VERSION ""

NS_ :

BS_:

BU_: SGW PBWM IDCM EVCU2 ECM DMPI BPCM AGSM

BO_ 2654408730 PLUG_AND_CHARGE_CONTRACT: 64 SGW
 SG_ PLUG_AND_CHARGE_CONTRACT_Sig8 : 455|64@0+ (0,0) [0|0] "" IDCM
 SG_ PLUG_AND_CHARGE_CONTRACT_Sig7 : 391|64@0+ (0,0) [0|0] "" IDCM
 SG_ PLUG_AND_CHARGE_CONTRACT_Sig6 : 327|64@0+ (0,0) [0|0] "" IDCM
 SG_ PLUG_AND_CHARGE_CONTRACT_Sig5 : 263|64@0+ (0,0) [0|0] "" IDCM
 SG_ PLUG_AND_CHARGE_CONTRACT_Sig4 : 199|64@0+ (0,0) [0|0] "" IDCM
 SG_ PLUG_AND_CHARGE_CONTRACT_Sig3 : 135|64@0+ (0,0) [0|0] "" IDCM
 SG_ PLUG_AND_CHARGE_CONTRACT_Sig2 : 71|64@0+ (0,0) [0|0] "" IDCM
 SG_ PLUG_AND_CHARGE_CONTRACT_Sig1 : 7|64@0+ (0,0) [0|0] "" IDCM

BO_ 212 PIM_B: 64 DMPI
 SG_ PIM_B_Torque_Achieved : 44|13@0+ (0.125,-512) [-512|511.875] "Nm"  EVCU2
 SG_ PIM_B_Torque_Achieved_V : 129|1@0+ (1,0) [0|1] "" EVCU2
 SG_ PIM_B_TorqAchieved_AEMD_V : 196|1@0+ (1,0) [0|1] "" EVCU2
 SG_ PIM_B_TorqAchieved_AEMD : 299|13@0+ (0.125,-512) [-512|511.875] "Nm"  EVCU2
 SG_ PIM_B_SPT_Stat : 78|2@0+ (1,0) [0|3] "" EVCU2
 SG_ PIM_B_Spd_Lim : 356|16@0+ (1,-32767) [-32767|32678] "rpm"  EVCU2
 SG_ PIM_B_RPM_V : 234|1@0+ (1,0) [0|1] "" PBWM,EVCU2
 SG_ PIM_B_RPM : 28|16@0+ (1,-32768) [-32768|32767] "rpm"  PBWM,EVCU2
 SG_ PIM_B_MtrMinCpbltyTrq : 321|13@0+ (0.125,-512) [-512|511.875] "Nm"  EVCU2
 SG_ PIM_B_MtrMaxCpbltyTrq : 318|13@0+ (0.125,-512) [-512|511.875] "Nm"  EVCU2
 SG_ PIM_B_MtrIndex : 398|5@0+ (1,0) [0|31] "" EVCU2
 SG_ PIM_B_MinTorq : 280|13@0+ (0.125,-512) [-512|511.875] "Nm"  EVCU2
 SG_ PIM_B_MaxTorq : 277|13@0+ (0.125,-512) [-512|511.875] "Nm"  EVCU2
 SG_ PIM_B_Invrtr_State : 186|4@0+ (1,0) [0|15] "" EVCU2
 SG_ PIM_B_InterlockSts : 229|2@0+ (1,0) [0|3] "-"  EVCU2
 SG_ PIM_B_HV_CnctrOpn_Req : 195|1@0+ (1,0) [0|1] "" EVCU2
 SG_ PIM_B_Dschrge_Status : 393|2@0+ (1,0) [0|3] "" EVCU2
 SG_ PIM_B_DeratingFactor : 388|6@0+ (0.02,0) [0|1.26] "" EVCU2
 SG_ PIM_B_DerateReason : 170|4@0+ (1,0) [0|15] "-"  EVCU2
 SG_ PIM_B_DC_Voltage : 271|10@0+ (1,0) [0|1022] "V"  EVCU2
 SG_ PIM_B_DC_Volt_V : 197|1@0+ (1,0) [0|1] "" EVCU2
 SG_ PIM_B_DC_Current_V : 198|1@0+ (1,0) [0|1] "" EVCU2
 SG_ PIM_B_DC_Current : 63|15@0+ (0.1,-1638.4) [-1638.4|1638.3] "A"  EVCU2,BPCM
 SG_ PIM_B_CpbltySpdDivVolt : 340|16@0+ (1,0) [0|65535] "rpm"  EVCU2
 SG_ PIM_B_CoolantTemp : 407|11@0+ (0.1,-40) [-40|164.7] "°C"  EVCU2
 SG_ PIM_B_AccelRawV : 193|1@0+ (1,0) [0|1] "" EVCU2
 SG_ PIM_B_6SO_Status : 64|2@0+ (1,0) [0|3] "" EVCU2
 SG_ PIM_B_3PS_Pos : 194|1@0+ (1,0) [0|1] "" EVCU2
 SG_ MC_PIM_B : 435|4@0+ (1,0) [0|15] "-"  EVCU2
 SG_ MAC_PIM_B : 471|48@0+ (1,0) [0|0] "" EVCU2
 SG_ CRC_PIM_B : 447|8@0+ (1,0) [0|255] "-"  EVCU2
 SG_ Cntr_PIM_B : 455|16@0+ (1,0) [0|65535] "" EVCU2
 SG_ PIM_B_AccelRaw : 372|16@0+ (1,-32768) [-32768|32767] "rpm/sec"  EVCU2

BO_ 211 PIM_A: 64 DMPI
 SG_ PIM_A_Torque_Achieved : 44|13@0+ (0.125,-512) [-512|511.875] "Nm"  EVCU2,ECM
 SG_ PIM_A_Torque_Achieved_V : 129|1@0+ (1,0) [0|1] "" EVCU2,ECM
 SG_ PIM_A_TorqAchieved_AEMD_V : 196|1@0+ (1,0) [0|1] "" EVCU2
 SG_ PIM_A_TorqAchieved_AEMD : 299|13@0+ (0.125,-512) [-512|511.875] "Nm"  EVCU2
 SG_ PIM_A_SPT_Stat : 78|2@0+ (1,0) [0|3] "" EVCU2
 SG_ PIM_A_Spd_Lim : 356|16@0+ (1,-32767) [-32767|32678] "rpm"  EVCU2
 SG_ PIM_A_RPM_V : 234|1@0+ (1,0) [0|1] "" EVCU2
 SG_ PIM_A_RPM : 28|16@0+ (1,-32768) [-32768|32767] "rpm"  EVCU2
 SG_ PIM_A_MtrMinCpbltyTrq : 321|13@0+ (0.125,-512) [-512|511.875] "Nm"  EVCU2
 SG_ PIM_A_MtrMaxCpbltyTrq : 318|13@0+ (0.125,-512) [-512|511.875] "Nm"  EVCU2
 SG_ PIM_A_MtrIndex : 398|5@0+ (1,0) [0|31] "" EVCU2
 SG_ PIM_A_MinTorq : 280|13@0+ (0.125,-512) [-512|511.875] "Nm"  EVCU2
 SG_ PIM_A_MaxTorq : 277|13@0+ (0.125,-512) [-512|511.875] "Nm"  EVCU2
 SG_ PIM_A_Invrtr_State : 186|4@0+ (1,0) [0|15] "" EVCU2
 SG_ PIM_A_InterlockSts : 229|2@0+ (1,0) [0|3] "-"  EVCU2
 SG_ PIM_A_HV_CnctrOpn_Req : 195|1@0+ (1,0) [0|1] "" EVCU2
 SG_ PIM_A_Dschrge_Status : 393|2@0+ (1,0) [0|3] "" EVCU2
 SG_ PIM_A_DeratingFactor : 388|6@0+ (0.02,0) [0|1.26] "" EVCU2
 SG_ PIM_A_DerateReason : 170|4@0+ (1,0) [0|15] "-"  EVCU2
 SG_ PIM_A_DC_Voltage : 271|10@0+ (1,0) [0|1022] "V"  EVCU2
 SG_ PIM_A_DC_Volt_V : 197|1@0+ (1,0) [0|1] "" EVCU2
 SG_ PIM_A_DC_Current_V : 198|1@0+ (1,0) [0|1] "" EVCU2
 SG_ PIM_A_DC_Current : 63|15@0+ (0.1,-1638.4) [-1638.4|1638.3] "A"  EVCU2,BPCM
 SG_ PIM_A_CpbltySpdDivVolt : 340|16@0+ (1,0) [0|65535] "rpm"  EVCU2
 SG_ PIM_A_CoolantTemp : 407|11@0+ (0.1,-40) [-40|164.7] "°C"  EVCU2
 SG_ PIM_A_AccelRawV : 193|1@0+ (1,0) [0|1] "" EVCU2
 SG_ PIM_A_6SO_Status : 64|2@0+ (1,0) [0|3] "" EVCU2
 SG_ PIM_A_3PS_Pos : 194|1@0+ (1,0) [0|1] "" EVCU2
 SG_ MC_PIM_A : 435|4@0+ (1,0) [0|15] "-"  EVCU2
 SG_ MAC_PIM_A : 471|48@0+ (1,0) [0|0] "" EVCU2
 SG_ CRC_PIM_A : 447|8@0+ (1,0) [0|255] "-"  EVCU2
 SG_ Cntr_PIM_A : 455|16@0+ (1,0) [0|65535] "" EVCU2
 SG_ PIM_A_AccelRaw : 372|16@0+ (1,-32768) [-32768|32767] "rpm/sec"  EVCU2

BO_ 2654339132 PDC_INFO_FD_PBWM: 32 PBWM
 SG_ WakeupSource_FD11_PBWM : 23|8@0+ (1,0) [0|255] "" EVCU2,SGW
 SG_ WakeupSource_FD05_PBWM : 175|8@0+ (1,0) [0|255] "" EVCU2,SGW
 SG_ StayActiveSource_FD11_PBWM : 31|64@0+ (1,0) [0|0] "" EVCU2,SGW
 SG_ StayActiveSource_FD05_PBWM : 99|64@0+ (1,0) [0|0] "" EVCU2,SGW
 SG_ PreviousCanNMState_FD11_PBWM : 11|4@0+ (1,0) [0|15] "" EVCU2,SGW
 SG_ PreviousCanNMState_FD05_PBWM : 103|4@0+ (1,0) [0|15] "" EVCU2,SGW
 SG_ GenericFailSts_FD11_PBWM : 5|1@0+ (1,0) [0|1] "" EVCU2,SGW
 SG_ GenericFailSts_FD05_PBWM : 89|1@0+ (1,0) [0|1] "" EVCU2,SGW
 SG_ EOL_FD11_PBWM : 7|1@0+ (1,0) [0|1] "-"  EVCU2,SGW
 SG_ EOL_FD05_PBWM : 1|1@0+ (1,0) [0|1] "-"  EVCU2,SGW
 SG_ DES_FD11_PBWM : 4|2@0+ (1,0) [0|3] "" EVCU2,SGW
 SG_ DES_FD05_PBWM : 91|2@0+ (1,0) [0|3] "" EVCU2,SGW
 SG_ CurrentFailSts_FD11_PBWM : 2|1@0+ (1,0) [0|1] "" EVCU2,SGW
 SG_ CurrentFailSts_FD05_PBWM : 6|1@0+ (1,0) [0|1] "" EVCU2,SGW
 SG_ CurrentCanNMState_FD11_PBWM : 15|4@0+ (1,0) [0|15] "" EVCU2,SGW
 SG_ CurrentCanNMState_FD05_PBWM : 95|4@0+ (1,0) [0|15] "" EVCU2,SGW

BO_ 2654339138 PDC_INFO_FD_DMPI: 32 DMPI
 SG_ WakeupSource_FD11_DMPI : 23|8@0+ (1,0) [0|255] "" EVCU2,SGW
 SG_ WakeupSource_FD05_DMPI : 175|8@0+ (1,0) [0|255] "" EVCU2,SGW
 SG_ StayActiveSource_FD11_DMPI : 31|64@0+ (1,0) [0|0] "" EVCU2,SGW
 SG_ StayActiveSource_FD05_DMPI : 99|64@0+ (1,0) [0|0] "" EVCU2,SGW
 SG_ PreviousCanNMState_FD11_DMPI : 11|4@0+ (1,0) [0|15] "" EVCU2,SGW
 SG_ PreviousCanNMState_FD05_DMPI : 103|4@0+ (1,0) [0|15] "" EVCU2,SGW
 SG_ GenericFailSts_FD11_DMPI : 5|1@0+ (1,0) [0|1] "" EVCU2,SGW
 SG_ GenericFailSts_FD05_DMPI : 89|1@0+ (1,0) [0|1] "" EVCU2,SGW
 SG_ EOL_FD11_DMPI : 7|1@0+ (1,0) [0|1] "-"  EVCU2,SGW
 SG_ EOL_FD05_DMPI : 1|1@0+ (1,0) [0|1] "-"  EVCU2,SGW
 SG_ DES_FD11_DMPI : 4|2@0+ (1,0) [0|3] "" EVCU2,SGW
 SG_ DES_FD05_DMPI : 91|2@0+ (1,0) [0|3] "" EVCU2,SGW
 SG_ CurrentFailSts_FD11_DMPI : 2|1@0+ (1,0) [0|1] "" EVCU2,SGW
 SG_ CurrentFailSts_FD05_DMPI : 6|1@0+ (1,0) [0|1] "" EVCU2,SGW
 SG_ CurrentCanNMState_FD11_DMPI : 15|4@0+ (1,0) [0|15] "" EVCU2,SGW
 SG_ CurrentCanNMState_FD05_DMPI : 95|4@0+ (1,0) [0|15] "" EVCU2,SGW

BO_ 1811 REAL_TIME_CLOCK: 64 EVCU2
 SG_ Real_Time_Validity : 39|1@0+ (1,0) [0|1] "" DMPI
 SG_ Real_Time_Clock : 7|32@0+ (1,0) [0|4294967295] "" DMPI
 SG_ MessageCounter_REAL_TIME_CLOCK : 435|4@0+ (1,0) [0|15] "-"  DMPI
 SG_ CRC_ANCHOR3_REAL_TIME_CLOCK : 447|8@0+ (1,0) [0|255] "-"  DMPI

BO_ 215 PCU_FD_1: 64 DMPI
 SG_ Pinion_OverspeedWarning : 33|1@0+ (1,0) [0|1] "" EVCU2
 SG_ PCU_Temporary_Stop_Flag : 75|1@0+ (1,0) [0|1] "" EVCU2
 SG_ PCU_MIL_Request : 103|1@0+ (1,0) [0|1] "" EVCU2,ECM
 SG_ PCU_MaxBoostedVoltage : 7|10@0+ (1,0) [0|1023] "V"  EVCU2
 SG_ PCU_Max_DischargePowerLmt : 31|14@0+ (0.01,0) [0|163.83] "kW"  EVCU2
 SG_ PCU_Max_ChargePowerLmt : 13|14@0+ (0.01,0) [0|163.83] "kW"  EVCU2
 SG_ PCU_DriveReadyCompletion_Status : 32|1@0+ (1,0) [0|1] "" EVCU2
 SG_ PCU_Diagnostic_Code : 87|16@0+ (1,0) [0|65535] "" EVCU2
 SG_ MessageCounter_PCU_FD_1 : 435|4@0+ (1,0) [0|15] "" EVCU2
 SG_ MAC_PCU_FD_1 : 471|48@0+ (1,0) [0|0] "" EVCU2
 SG_ CRC_PCU_FD_1 : 447|8@0+ (1,0) [0|255] "" EVCU2
 SG_ Cntr_PCU_FD_1 : 455|16@0+ (1,0) [0|65535] "" EVCU2
 SG_ BoostConverterFailureSts : 74|3@0+ (1,0) [0|7] "" EVCU2
 SG_ BoostConverter_Current : 102|15@0+ (0.1,-1638.3) [-1638.3|1638.40] "A"  EVCU2
 SG_ BoostConv_UpperIGBT_TempFltd : 47|12@0+ (0.1,-40) [-40|369.5] "°C"  EVCU2
 SG_ BoostConv_ReactorTemp : 71|12@0+ (0.1,-40) [-40|369.5] "ºC"  EVCU2
 SG_ BoostConv_LowerIGBT_TempFltd : 51|12@0+ (0.1,-40) [-40|369.5] "ºC"  EVCU2
 SG_ Output_Torque_Limit : 127|15@0+ (2,0) [0|65534] "Nm"  EVCU2
 SG_ BoostConverterDerateReason : 136|9@0+ (1,0) [0|511] "" EVCU2
 SG_ PCU_Max_DischargePowerLmt_ShrTrm : 159|14@0+ (0.01,0) [0|163.83] "kW"  EVCU2
 SG_ DMPI_OilTemperatureSts : 128|1@0+ (1,0) [0|1] "" EVCU2
 SG_ DMPI_TransmissionTemperature : 143|6@0+ (3,-40) [-40|149] "ºC"  EVCU2
 SG_ REPRGD_PFC_CLR_DMPI : 161|1@0+ (1,0) [0|1] "" ECM
 SG_ CODE_CLR_DMPI : 137|1@0+ (1,0) [0|1] "" ECM

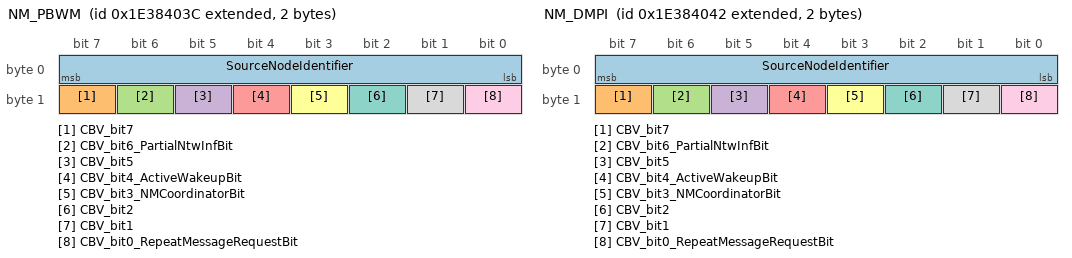
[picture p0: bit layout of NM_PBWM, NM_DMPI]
BO_ 2654486588 NM_PBWM: 2 PBWM
 SG_ SourceNodeIdentifier : 7|8@0+ (1,0) [0|255] "-"  DMPI,EVCU2,IDCM,SGW,BPCM,ECM
 SG_ CBV_bit7 : 15|1@0+ (1,0) [0|1] "" DMPI,EVCU2,IDCM,SGW,BPCM,ECM
 SG_ CBV_bit6_PartialNtwInfBit : 14|1@0+ (1,0) [0|1] "" DMPI,EVCU2,IDCM,SGW,BPCM,ECM
 SG_ CBV_bit5 : 13|1@0+ (1,0) [0|1] "" DMPI,EVCU2,IDCM,SGW,BPCM,ECM
 SG_ CBV_bit4_ActiveWakeupBit : 12|1@0+ (1,0) [0|1] "" DMPI,EVCU2,IDCM,SGW,BPCM,ECM
 SG_ CBV_bit3_NMCoordinatorBit : 11|1@0+ (1,0) [0|1] "" DMPI,EVCU2,IDCM,SGW,BPCM,ECM
 SG_ CBV_bit2 : 10|1@0+ (1,0) [0|1] "" DMPI,EVCU2,IDCM,SGW,BPCM,ECM
 SG_ CBV_bit1 : 9|1@0+ (1,0) [0|1] "" DMPI,EVCU2,IDCM,SGW,BPCM,ECM
 SG_ CBV_bit0_RepeatMessageRequestBit : 8|1@0+ (1,0) [0|1] "" DMPI,EVCU2,IDCM,SGW,BPCM,ECM

BO_ 2654486594 NM_DMPI: 2 DMPI
 SG_ SourceNodeIdentifier : 7|8@0+ (1,0) [0|255] "-"  PBWM,EVCU2,IDCM,SGW,BPCM,ECM
 SG_ CBV_bit7 : 15|1@0+ (1,0) [0|1] "" PBWM,EVCU2,IDCM,SGW,BPCM,ECM
 SG_ CBV_bit6_PartialNtwInfBit : 14|1@0+ (1,0) [0|1] "" PBWM,EVCU2,IDCM,SGW,BPCM,ECM
 SG_ CBV_bit5 : 13|1@0+ (1,0) [0|1] "" PBWM,EVCU2,IDCM,SGW,BPCM,ECM
 SG_ CBV_bit4_ActiveWakeupBit : 12|1@0+ (1,0) [0|1] "" PBWM,EVCU2,IDCM,SGW,BPCM,ECM
 SG_ CBV_bit3_NMCoordinatorBit : 11|1@0+ (1,0) [0|1] "" PBWM,EVCU2,IDCM,SGW,BPCM,ECM
 SG_ CBV_bit2 : 10|1@0+ (1,0) [0|1] "" PBWM,EVCU2,IDCM,SGW,BPCM,ECM
 SG_ CBV_bit1 : 9|1@0+ (1,0) [0|1] "" PBWM,EVCU2,IDCM,SGW,BPCM,ECM
 SG_ CBV_bit0_RepeatMessageRequestBit : 8|1@0+ (1,0) [0|1] "" PBWM,EVCU2,IDCM,SGW,BPCM,ECM

BO_ 214 INVTARGET1_2: 64 EVCU2
 SG_ UDCMin_Unlim_MCPB_2 : 129|16@0+ (0.01,0) [0|655.35] "V"  DMPI
 SG_ UDCMin_Unlim_MCPA_2 : 81|16@0+ (0.01,0) [0|655.35] "V"  DMPI
 SG_ UDCMax_Unlim_MCPB_2 : 113|16@0+ (0.01,0) [0|655.35] "V"  DMPI
 SG_ UDCMax_Unlim_MCPA_2 : 65|16@0+ (0.01,0) [0|655.35] "V"  DMPI
 SG_ TqGrdtLim_MCPB_2 : 144|16@0+ (0.1,0) [0|6553.5] "Nm/s"  DMPI
 SG_ TqGrdtLim_MCPA_2 : 97|16@0+ (0.1,0) [0|6553.5] "Nm/s"  DMPI
 SG_ TorqueCommand_MCPB_2 : 201|13@0+ (0.125,-512) [-512|511.875] "Nm"  DMPI
 SG_ TorqueCommand_MCPA_2 : 7|13@0+ (0.125,-512) [-512|511.875] "Nm"  DMPI
 SG_ TargetMotorRPM_MCPB_2 : 216|16@0+ (0.5,-16384) [-16384|16383.5] "rpm"  DMPI
 SG_ TargetMotorRPM_MCPA_2 : 22|16@0+ (0.5,-16384) [-16384|16383.5] "rpm"  DMPI
 SG_ SpdGrdtLim_MCPB_2 : 273|11@0+ (20,0) [0|40940] "rpm/s"  DMPI
 SG_ SpdGrdtLim_MCPA_2 : 160|11@0+ (20,0) [0|40940] "rpm/s"  DMPI
 SG_ Mtr_6SO_Request_MCPB_2 : 145|1@0+ (1,0) [0|1] "" DMPI
 SG_ Mtr_6SO_Request_MCPA_2 : 38|1@0+ (1,0) [0|1] "" DMPI
 SG_ ModeCommand_MCPB_2 : 220|4@0+ (1,0) [0|15] "" DMPI
 SG_ ModeCommand_MCPA_2 : 10|4@0+ (1,0) [0|15] "" DMPI
 SG_ MinTorque_Limit_MCPB_2 : 296|14@0+ (0.1,-1638.2) [-1638.2|0.1] "Nm"  DMPI
 SG_ MinTorque_Limit_MCPA_2 : 199|14@0+ (0.1,-1638.2) [-1638.2|0.1] "Nm"  DMPI
 SG_ MessageCounter_INVTARGET1_2 : 435|4@0+ (1,0) [0|15] "" DMPI
 SG_ MaxTorque_Limit_MCPB_2 : 294|14@0+ (0.1,0) [0|1638.3] "Nm"  DMPI
 SG_ MaxTorque_Limit_MCPA_2 : 181|14@0+ (0.1,0) [0|1638.3] "Nm"  DMPI
 SG_ MAC_INVTARGET1_2 : 471|48@0+ (1,0) [0|0] "" DMPI
 SG_ LgsDiagCldStrtCndMet_MCPB_2 : 267|1@0+ (1,0) [0|1] "" DMPI
 SG_ LgsDiagCldStrtCndFltPr_MCPB_2 : 268|1@0+ (1,0) [0|1] "" DMPI
 SG_ HVBatVlt_V_2 : 266|1@0+ (1,0) [0|1] "" DMPI
 SG_ EVCU_END_Request_Flag_2 : 256|1@0+ (1,0) [0|1] "" DMPI
 SG_ CRC_INVTARGET1_2 : 447|8@0+ (1,0) [0|255] "" DMPI
 SG_ Cntr_INVTARGET1_2 : 455|16@0+ (1,0) [0|65535] "" DMPI
 SG_ AEMD_MinOffset_MCPB_2 : 252|12@0+ (0.125,-511.875) [-511.875|0] "Nm"  DMPI
 SG_ AEMD_MinOffset_MCPA_2 : 41|12@0+ (0.125,-511.875) [-511.875|0] "Nm"  DMPI
 SG_ AEMD_MaxOffset_MCPB_2 : 232|12@0+ (0.125,0) [0|511.875] "Nm"  DMPI
 SG_ AEMD_Cutoff_FreqLow_MCPB_2 : 399|8@0+ (0.1,4.5) [4.5|30] "Hz"  DMPI
 SG_ AEMD_Cutoff_FreqLow_MCPA_2 : 391|8@0+ (0.1,4.5) [4.5|30] "Hz"  DMPI
 SG_ AEMD_Cutoff_FreqHigh_MCPB_2 : 383|8@0+ (0.1,0) [0|25.5] "Hz"  DMPI
 SG_ AEMD_Cutoff_FreqHigh_MCPA_2 : 375|8@0+ (0.1,0) [0|25.5] "Hz"  DMPI
 SG_ AEMD_Sclr_Gn_MCPB_2 : 354|11@0+ (0.01,0) [0|20.47] "rad/s/Nm"  DMPI
 SG_ AEMD_Sclr_Gn_MCPA_2 : 349|11@0+ (0.01,0) [0|20.47] "rad/s/Nm"  DMPI
 SG_ AEMD_Torque_BoostVolt_Margin : 37|12@0+ (0.125,0) [0|511.875] "Nm"  DMPI
 SG_ Boost_Torque_Margin_MCPB : 343|10@0+ (0.5,-256) [-256|255.5] "Nm"  DMPI
 SG_ Boost_Torque_Margin_MCPA : 321|10@0+ (0.5,-256) [-256|255.5] "Nm"  DMPI

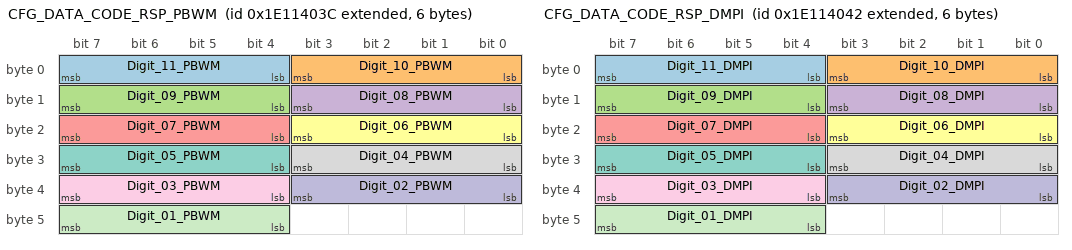
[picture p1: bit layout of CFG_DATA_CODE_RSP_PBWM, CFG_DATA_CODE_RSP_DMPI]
BO_ 2651930684 CFG_DATA_CODE_RSP_PBWM: 6 PBWM
 SG_ Digit_11_PBWM : 7|4@0+ (1,0) [0|15] "-"  EVCU2
 SG_ Digit_10_PBWM : 3|4@0+ (1,0) [0|15] "-"  EVCU2
 SG_ Digit_09_PBWM : 15|4@0+ (1,0) [0|15] "-"  EVCU2
 SG_ Digit_08_PBWM : 11|4@0+ (1,0) [0|15] "-"  EVCU2
 SG_ Digit_07_PBWM : 23|4@0+ (1,0) [0|15] "-"  EVCU2
 SG_ Digit_06_PBWM : 19|4@0+ (1,0) [0|15] "-"  EVCU2
 SG_ Digit_05_PBWM : 31|4@0+ (1,0) [0|15] "-"  EVCU2
 SG_ Digit_04_PBWM : 27|4@0+ (1,0) [0|15] "-"  EVCU2
 SG_ Digit_03_PBWM : 39|4@0+ (1,0) [0|15] "-"  EVCU2
 SG_ Digit_02_PBWM : 35|4@0+ (1,0) [0|15] "-"  EVCU2
 SG_ Digit_01_PBWM : 47|4@0+ (1,0) [0|15] "-"  EVCU2

BO_ 2651930690 CFG_DATA_CODE_RSP_DMPI: 6 DMPI
 SG_ Digit_11_DMPI : 7|4@0+ (1,0) [0|15] "-"  EVCU2
 SG_ Digit_10_DMPI : 3|4@0+ (1,0) [0|15] "-"  EVCU2
 SG_ Digit_09_DMPI : 15|4@0+ (1,0) [0|15] "-"  EVCU2
 SG_ Digit_08_DMPI : 11|4@0+ (1,0) [0|15] "-"  EVCU2
 SG_ Digit_07_DMPI : 23|4@0+ (1,0) [0|15] "-"  EVCU2
 SG_ Digit_06_DMPI : 19|4@0+ (1,0) [0|15] "-"  EVCU2
 SG_ Digit_05_DMPI : 31|4@0+ (1,0) [0|15] "-"  EVCU2
 SG_ Digit_04_DMPI : 27|4@0+ (1,0) [0|15] "-"  EVCU2
 SG_ Digit_03_DMPI : 39|4@0+ (1,0) [0|15] "-"  EVCU2
 SG_ Digit_02_DMPI : 35|4@0+ (1,0) [0|15] "-"  EVCU2
 SG_ Digit_01_DMPI : 47|4@0+ (1,0) [0|15] "-"  EVCU2

BO_ 2564682188 DIAGNOSTIC_ROE_PBWM: 8 PBWM
 SG_ N_PDU : 7|64@0+ (1,0) [0|0] "" SGW

BO_ 2564682444 DIAGNOSTIC_ROE_FD_PBWM: 64 PBWM
 SG_ N_PDU : 7|64@0+ (1,0) [0|0] "" SGW

BO_ 2564682307 DIAGNOSTIC_ROE_FD_DMPI: 64 DMPI
 SG_ N_PDU : 7|64@0+ (1,0) [0|0] "" SGW

BO_ 2564682051 DIAGNOSTIC_ROE_DMPI: 8 DMPI
 SG_ N_PDU : 7|64@0+ (1,0) [0|0] "" SGW

BO_ 2564485580 DIAGNOSTIC_RESPONSE_PBWM: 8 PBWM
 SG_ N_PDU : 7|64@0+ (1,0) [0|0] "" SGW

BO_ 2564485836 DIAGNOSTIC_RESPONSE_FD_PBWM: 64 PBWM
 SG_ N_PDU : 7|64@0+ (1,0) [0|0] "" SGW

BO_ 2564485699 DIAGNOSTIC_RESPONSE_FD_DMPI: 64 DMPI
 SG_ N_PDU : 7|64@0+ (1,0) [0|0] "" SGW

BO_ 2564485443 DIAGNOSTIC_RESPONSE_DMPI: 8 DMPI
 SG_ N_PDU : 7|64@0+ (1,0) [0|0] "" SGW

BO_ 2564476145 DIAGNOSTIC_REQUEST_PBWM: 8 SGW
 SG_ N_PDU : 7|64@0+ (1,0) [0|0] "" PBWM

BO_ 2564476146 DIAGNOSTIC_REQUEST_FD_PBWM: 64 SGW
 SG_ N_PDU : 7|64@0+ (1,0) [0|0] "" PBWM

BO_ 2564441074 DIAGNOSTIC_REQUEST_FD_DMPI: 64 SGW
 SG_ N_PDU : 7|64@0+ (1,0) [0|0] "" DMPI

BO_ 2564441073 DIAGNOSTIC_REQUEST_DMPI: 8 SGW
 SG_ N_PDU : 7|64@0+ (1,0) [0|0] "" DMPI

BO_ 504 MCPB_STATUS: 32 EVCU2
 SG_ MCPB_DC_Current_P : 38|15@0+ (0.1,-1638.4) [-1638.4|1638.3] "A"  BPCM
 SG_ MC_MCPB_STATUS : 179|4@0+ (1,0) [0|15] "-"  BPCM
 SG_ CRC_MCPB_STATUS : 191|8@0+ (1,0) [0|255] "-"  BPCM

BO_ 503 MCPA_STATUS: 32 EVCU2
 SG_ MCPA_DC_Current_P : 38|15@0+ (0.1,-1638.4) [-1638.4|1638.3] "A"  BPCM
 SG_ MC_MCPA_STATUS : 179|4@0+ (1,0) [0|15] "-"  BPCM
 SG_ CRC_MCPA_STATUS : 191|8@0+ (1,0) [0|255] "-"  BPCM

BO_ 124 GLIWA_MCPB_TX: 8 EVCU2
 SG_ N_PDU : 7|64@0+ (1,0) [0|0] "" SGW

BO_ 127 GLIWA_MCPB_RX: 8 SGW
 SG_ N_PDU : 7|64@0+ (1,0) [0|0] "" EVCU2

BO_ 123 GLIWA_MCPA_TX: 8 EVCU2
 SG_ N_PDU : 7|64@0+ (1,0) [0|0] "" SGW

BO_ 126 GLIWA_MCPA_RX: 8 SGW
 SG_ N_PDU : 7|64@0+ (1,0) [0|0] "" EVCU2

BO_ 1072 IDCM_CHADEMO_STATUS1: 64 IDCM
 SG_ EVSE_ThrshldVoltage : 399|10@0+ (1,0) [0|1023] "V"  EVCU2
 SG_ EVSE_RemainingSec : 423|8@0+ (10,0) [0|2550] "sec"  EVCU2
 SG_ EVSE_RemainingMin : 415|8@0+ (1,0) [0|255] "min"  EVCU2
 SG_ EVSE_EnergizingState : 402|1@0+ (1,0) [0|1] "" EVCU2
 SG_ EVSE_ChargingSystemError : 400|1@0+ (1,0) [0|1] "" EVCU2
 SG_ EVSE_CHAdeMOProtocol : 405|3@0+ (1,0) [0|7] "" EVCU2
 SG_ EVSE_BatteryCompatibilty : 401|1@0+ (1,0) [0|1] "" EVCU2
 SG_ CdM_Charger_connector_lock : 7|1@0+ (1,0) [0|1] "" EVCU2
 SG_ CdM_ExtFun_Thres_Volt : 356|11@0+ (1,0) [0|2047] "V"  EVCU2
 SG_ CdM_Avail_output_current_EXT : 370|10@0+ (1,0) [0|1023] "A"  EVCU2

BO_ 1073 EVCU_CHADEMO_STATUS1: 64 EVCU2
 SG_ VehicleDriveSts : 402|1@0+ (1,0) [0|1] "" IDCM
 SG_ TotalBatteryCapacity : 415|16@0+ (0.1,0) [0|6553.5] "KWh"  IDCM
 SG_ StopReqBeforeCharge : 400|1@0+ (1,0) [0|1] "" IDCM
 SG_ MinBatteryPackVoltage : 399|10@0+ (1,0) [0|1023] "V"  IDCM
 SG_ EVContactorSts : 401|1@0+ (1,0) [0|1] "" IDCM
 SG_ DisplaySOC : 390|7@0+ (1,0) [0|127] "%"  IDCM
 SG_ ChargedReferenceConstant : 374|7@0+ (1,0) [0|127] "%"  IDCM
 SG_ ChargedCurrentMin : 383|8@0+ (1,0) [0|255] "A"  IDCM
 SG_ CHAdeMOProtocol : 405|3@0+ (1,0) [0|7] "" IDCM
 SG_ BattVoltDeviationErr : 391|1@0+ (1,0) [0|1] "" IDCM
 SG_ EVCU_CP3Cmd : 375|1@0+ (1,0) [0|1] "" IDCM
 SG_ CdM_Remained_batt_capacity : 367|8@0+ (0.1,0) [0|25.5] "kWh"  IDCM
 SG_ CdM_ExtFun_Veh_HC_Control_Comp : 347|1@0+ (1,0) [0|1] "" IDCM
 SG_ CdM_ExtFun_Veh_Dyn_Control_Comp : 348|1@0+ (1,0) [0|1] "" IDCM
 SG_ CdM_ExtFun_Min_Batt_Volt : 346|11@0+ (1,0) [0|2047] "V"  IDCM
 SG_ CdM_Chrg_current_req_ext : 342|10@0+ (1,0) [0|1023] "A"  IDCM

BO_ 577 SYNCHRO_DC_GLOBAL: 32 ECM
 SG_ QualifyDriveCycle : 7|1@0+ (1,0) [0|1] "" DMPI,BPCM

BO_ 220 PT_SYSTEM_FD_OBD: 48 EVCU2
 SG_ VIN_MSG_OBD : 25|2@0+ (1,0) [0|3] "" DMPI,PBWM
 SG_ VIN_DATA_OBD : 39|56@0+ (1,0) [0|0] "" DMPI,PBWM
 SG_ VehicleSpeedVSOSig_OBD : 119|13@0+ (0.0625,0) [0|511.9375] "Km/h"  DMPI,PBWM,BPCM
 SG_ TotalOdometer_OBD : 95|20@0+ (1,0) [0|1048575] "km"  DMPI,PBWM,BPCM
 SG_ OperationalModeSts_OBD : 107|4@0+ (1,0) [0|15] "" PBWM,DMPI,IDCM,BPCM,AGSM,ECM
 SG_ EngineSpeedFailSts_W_OBD : 149|1@0+ (1,0) [0|1] "" DMPI
 SG_ EngineSpeed_W_OBD : 23|14@0+ (1,0) [0|16383] "1/min"  DMPI,PBWM,BPCM,ECM
 SG_ CmdIgnSts_OBD : 122|3@0+ (1,0) [0|7] "" PBWM,DMPI,IDCM,BPCM,AGSM,ECM
 SG_ IgnitionOnCounter_OBD : 7|16@0+ (1,0) [0|65535] "" DMPI,PBWM,BPCM
 SG_ ExternalTemperatureC_OBD : 135|9@0+ (0.5,-85) [-85|170.5] "°C"  DMPI,PBWM,BPCM
 SG_ Battery_Volt_1_OBD : 142|9@0+ (0.025,5) [5|17.775] "Volt"  DMPI,PBWM,BPCM
 SG_ MessageCounter_PT_SYSTEM_FD_OBD : 307|4@0+ (1,0) [0|15] "-"  DMPI,BPCM,AGSM,ECM
 SG_ CRC_PT_SYSTEM_FD_OBD : 319|8@0+ (1,0) [0|255] "-"  DMPI,BPCM,AGSM,ECM

BO_ 200 PT_SYSTEM_FD_4: 64 EVCU2
 SG_ TotalAxle_Rq_BSM_PT : 55|16@0+ (2,-65534) [-65534|65536] "Nm"  DMPI
 SG_ TotalAxle_Min_Rq_BSM_PT : 113|1@0+ (1,0) [0|1] "" DMPI
 SG_ TotalAxle_Max_Rq_BSM_PT : 114|1@0+ (1,0) [0|1] "" DMPI
 SG_ Total_AxleTorque_Static_PT : 71|16@0+ (2,-65534) [-65534|65536] "Nm"  DMPI
 SG_ RHFWheelSpeed_PT : 111|13@0+ (0.0625,0) [0|511.9375] "Km/h"  DMPI
 SG_ RHF_WheelSensorFailSts_PT : 9|1@0+ (1,0) [0|1] "" DMPI
 SG_ LHFWheelSpeed_PT : 7|13@0+ (0.0625,0) [0|511.9375] "Km/h"  DMPI
 SG_ LHF_WheelSensorFailSts_PT : 10|1@0+ (1,0) [0|1] "" DMPI
 SG_ Ft_RrCouplingTrq_Desired_PT : 103|8@0+ (12,0) [0|3060] "Nm"  DMPI
 SG_ Ft_RrCouplingTrq_Actual_PT : 87|8@0+ (12,0) [0|3060] "Nm"  DMPI
 SG_ ESCActive_PT : 8|1@0+ (1,0) [0|1] "" DMPI
 SG_ Axle_TorqueStatic_D_TTC_PT : 23|16@0+ (2,-65534) [-65534|65536] "Nm"  DMPI
 SG_ Axle_TorqueStatic_D_TTC_ESC_PT : 39|16@0+ (2,-65534) [-65534|65536] "Nm"  DMPI
 SG_ AWDSysStat_PT : 123|3@0+ (1,0) [0|7] "-"  DMPI
 SG_ AtmosphericPressureFailSts_PT : 112|1@0+ (1,0) [0|1] "" DMPI
 SG_ AtmosphericPressure_W_PT : 95|8@0+ (3.6,300) [300|1218] "mbar"  DMPI
 SG_ MessageCounter_PT_SYSTEM_FD_4 : 435|4@0+ (1,0) [0|15] "-"  DMPI
 SG_ CRC_PT_SYSTEM_FD_4 : 447|8@0+ (1,0) [0|255] "-"  DMPI

CM_ SG_ 212 PIM_B_Torque_Achieved_V "Achieved Torque value Validity, [1] = True";
CM_ SG_ 212 PIM_B_Torque_Achieved "Motr B Torque Achieved";
CM_ SG_ 212 PIM_B_TorqAchieved_AEMD_V "Motor Torque Achieved Validity";
CM_ SG_ 212 PIM_B_TorqAchieved_AEMD "Motor Torque Achieved";
CM_ SG_ 212 PIM_B_SPT_Stat "Inverter Isolation Status";
CM_ SG_ 212 PIM_B_Spd_Lim "Limited motor speed during reduced performance from MCP B";
CM_ SG_ 212 PIM_B_RPM_V "Motor B Speed Validity, [1] = True";
CM_ SG_ 212 PIM_B_RPM "Motor B Speed Raw";
CM_ SG_ 212 PIM_B_MtrMinCpbltyTrq "Motor B Min Capability Torque";
CM_ SG_ 212 PIM_B_MtrMaxCpbltyTrq "Motor B Max Capability Torque";
CM_ SG_ 212 PIM_B_MtrIndex "Motor B Capability Curve Array Index";
CM_ SG_ 212 PIM_B_MinTorq "Motor B Minimum Torque";
CM_ SG_ 212 PIM_B_MaxTorq "Motor B Maximum Torque";
CM_ SG_ 212 PIM_B_Invrtr_State "Inverter State of Operation of Motor B";
CM_ SG_ 212 PIM_B_InterlockSts "Front inverter interlock state";
CM_ SG_ 212 PIM_B_HV_CnctrOpn_Req "HV Battery pack contactor request";
CM_ SG_ 212 PIM_B_Dschrge_Status "The active discharge status of MCPB";
CM_ SG_ 212 PIM_B_DeratingFactor "Motor B Derating Factor";
CM_ SG_ 212 PIM_B_DerateReason "Inverter Derating Reason";
CM_ SG_ 212 PIM_B_DC_Voltage "Inverter Front DC Voltage.";
CM_ SG_ 212 PIM_B_DC_Volt_V "Motor B DC current  validity, [1] = True";
CM_ SG_ 212 PIM_B_DC_Current_V "Motor B DC current  validity, [1] = True";
CM_ SG_ 212 PIM_B_DC_Current "Motor B DC Current";
CM_ SG_ 212 PIM_B_CpbltySpdDivVolt "Motor B Speed at Capability Curve";
CM_ SG_ 212 PIM_B_CoolantTemp "PIM Coolant Temperature";
CM_ SG_ 212 PIM_B_AccelRawV "Motor B Acceleration Validity";
CM_ SG_ 212 CRC_PIM_B "CRC according to SAE J1850 standard that has to be calculated from bit 63 to bit 8 at each frame transmission.";
CM_ SG_ 212 MC_PIM_B "Message counter according to SAE J1850 standard that has to be calculated from bit 63 to bit 8 at each frame transmission.";
CM_ SG_ 212 PIM_B_3PS_Pos "3 phase motor short possible from MCP B; True = [1]";
CM_ SG_ 212 PIM_B_AccelRaw "Motor B Acceleration";
CM_ SG_ 211 CRC_PIM_A "CRC according to SAE J1850 standard that has to be calculated from bit 63 to bit 8 at each frame transmission.";
CM_ SG_ 211 MC_PIM_A "Message counter according to SAE J1850 standard that has to be calculated from bit 63 to bit 8 at each frame transmission.";
CM_ SG_ 211 PIM_A_3PS_Pos "3 phase motor short possible from MCP B; True = [1]";
CM_ SG_ 211 PIM_A_AccelRaw "Motor A Acceleration";
CM_ SG_ 211 PIM_A_AccelRawV "Motor A Acceleration Validity";
CM_ SG_ 211 PIM_A_CoolantTemp "PIM Coolant Temperature";
CM_ SG_ 211 PIM_A_CpbltySpdDivVolt "Motor A Speed at Capability Curve";
CM_ SG_ 211 PIM_A_DC_Current "Motor A DC Current";
CM_ SG_ 211 PIM_A_DC_Current_V "Motor A DC current  validity, [1] = True";
CM_ SG_ 211 PIM_A_DC_Volt_V "Motor A DC current  validity, [1] = True";
CM_ SG_ 211 PIM_A_DC_Voltage "Inverter Front DC Voltage.";
CM_ SG_ 211 PIM_A_DerateReason "Inverter Derating Reason";
CM_ SG_ 211 PIM_A_DeratingFactor "Motor A Derating Factor";
CM_ SG_ 211 PIM_A_Dschrge_Status "The active discharge status of MCPA";
CM_ SG_ 211 PIM_A_HV_CnctrOpn_Req "HV Battery pack contactor request";
CM_ SG_ 211 PIM_A_InterlockSts "Front inverter interlock state";
CM_ SG_ 211 PIM_A_Invrtr_State "Inverter State of Operation of Motor A";
CM_ SG_ 211 PIM_A_MaxTorq "Motor A Maximum Torque";
CM_ SG_ 211 PIM_A_MinTorq "Motor A Minimum Torque";
CM_ SG_ 211 PIM_A_MtrIndex "Motor A Capability Curve Array Index";
CM_ SG_ 211 PIM_A_MtrMaxCpbltyTrq "Motor A Max Capability Torque";
CM_ SG_ 211 PIM_A_MtrMinCpbltyTrq "Motor A Min Capability Torque";
CM_ SG_ 211 PIM_A_RPM "Motor A Speed Raw";
CM_ SG_ 211 PIM_A_RPM_V "Motor A Speed Validity, [1] = True";
CM_ SG_ 211 PIM_A_Spd_Lim "Limited motor speed during reduced performance from MCP B";
CM_ SG_ 211 PIM_A_SPT_Stat "Inverter Isolation Status";
CM_ SG_ 211 PIM_A_TorqAchieved_AEMD "Motor Torque Achieved";
CM_ SG_ 211 PIM_A_TorqAchieved_AEMD_V "Motor Torque Achieved Validity";
CM_ SG_ 211 PIM_A_Torque_Achieved "Motr A Torque Achieved";
CM_ SG_ 211 PIM_A_Torque_Achieved_V "Achieved Torque value Validity, [1] = True";
CM_ SG_ 2654339132 CurrentCanNMState_FD05_PBWM "Indicates that CanNM state the ECU is currently executing";
CM_ SG_ 2654339132 CurrentCanNMState_FD11_PBWM "Indicates that CanNM state the ECU is currently executing";
CM_ SG_ 2654339132 CurrentFailSts_FD05_PBWM "Indicates the presence/absence of at least one DTC with DTCStatus = present in the System Memory";
CM_ SG_ 2654339132 CurrentFailSts_FD11_PBWM "Indicates the presence/absence of at least one DTC with DTCStatus = present in the System Memory";
CM_ SG_ 2654339132 DES_FD05_PBWM "Indicates whether the ECU?s CAN cell is in either ErrorActive, or ErrorPassive state OR has just now recovered from a BusOff condition";
CM_ SG_ 2654339132 DES_FD11_PBWM "Indicates whether the ECU?s CAN cell is in either ErrorActive, or ErrorPassive state OR has just now recovered from a BusOff condition";
CM_ SG_ 2654339132 EOL_FD05_PBWM "Indicates if the ECU requires configuration data at the assembly plant End Of Line";
CM_ SG_ 2654339132 EOL_FD11_PBWM "Indicates if the ECU requires configuration data at the assembly plant End Of Line";
CM_ SG_ 2654339132 GenericFailSts_FD05_PBWM "Indicates the presence/absent of at least one DTC in the System Memory";
CM_ SG_ 2654339132 GenericFailSts_FD11_PBWM "Indicates the presence/absent of at least one DTC in the System Memory";
CM_ SG_ 2654339132 PreviousCanNMState_FD05_PBWM "Indicates the last CanNM state that the ECU existed in";
CM_ SG_ 2654339132 PreviousCanNMState_FD11_PBWM "Indicates the last CanNM state that the ECU existed in";
CM_ SG_ 2654339132 StayActiveSource_FD05_PBWM "Indicates the source that requests the ECU to stay active";
CM_ SG_ 2654339132 StayActiveSource_FD11_PBWM "Indicates the source that requests the ECU to stay active";
CM_ SG_ 2654339132 WakeupSource_FD05_PBWM "Indicates the reason the ECU was most recently awakened";
CM_ SG_ 2654339132 WakeupSource_FD11_PBWM "Indicates the reason the ECU was most recently awakened";
CM_ SG_ 2654339138 WakeupSource_FD11_DMPI "Indicates the reason the ECU was most recently awakened";
CM_ SG_ 2654339138 WakeupSource_FD05_DMPI "Indicates the reason the ECU was most recently awakened";
CM_ SG_ 2654339138 StayActiveSource_FD11_DMPI "Indicates the source that requests the ECU to stay active";
CM_ SG_ 2654339138 StayActiveSource_FD05_DMPI "Indicates the source that requests the ECU to stay active";
CM_ SG_ 2654339138 PreviousCanNMState_FD11_DMPI "Indicates the last CanNM state that the ECU existed in";
CM_ SG_ 2654339138 PreviousCanNMState_FD05_DMPI "Indicates the last CanNM state that the ECU existed in";
CM_ SG_ 2654339138 GenericFailSts_FD11_DMPI "Indicates the presence/absent of at least one DTC in the System Memory";
CM_ SG_ 2654339138 GenericFailSts_FD05_DMPI "Indicates the presence/absent of at least one DTC in the System Memory";
CM_ SG_ 2654339138 EOL_FD11_DMPI "Indicates if the ECU requires configuration data at the assembly plant End Of Line";
CM_ SG_ 2654339138 EOL_FD05_DMPI "Indicates if the ECU requires configuration data at the assembly plant End Of Line";
CM_ SG_ 2654339138 DES_FD11_DMPI "Indicates whether the ECU?s CAN cell is in either ErrorActive, or ErrorPassive state OR has just now recovered from a BusOff condition";
CM_ SG_ 2654339138 DES_FD05_DMPI "Indicates whether the ECU?s CAN cell is in either ErrorActive, or ErrorPassive state OR has just now recovered from a BusOff condition";
CM_ SG_ 2654339138 CurrentFailSts_FD11_DMPI "Indicates the presence/absence of at least one DTC with DTCStatus = present in the System Memory";
CM_ SG_ 2654339138 CurrentFailSts_FD05_DMPI "Indicates the presence/absence of at least one DTC with DTCStatus = present in the System Memory";
CM_ SG_ 2654339138 CurrentCanNMState_FD11_DMPI "Indicates that CanNM state the ECU is currently executing";
CM_ SG_ 2654339138 CurrentCanNMState_FD05_DMPI "Indicates that CanNM state the ECU is currently executing";
CM_ SG_ 1811 Real_Time_Validity "EVCU Real Time Clock Validity";
CM_ SG_ 1811 Real_Time_Clock "EVCU Real Time Clock";
CM_ SG_ 1811 MessageCounter_REAL_TIME_CLOCK "This signal is a counter used for safety checks strategies. This counter is incremented of 1 (one) unit at each frame transmission.";
CM_ SG_ 1811 CRC_ANCHOR3_REAL_TIME_CLOCK "CRC according to SAE J1850 standard at each frame transmission.";
CM_ SG_ 215 REPRGD_PFC_CLR_DMPI "Set Readiness to Incomplete";
CM_ SG_ 215 Pinion_OverspeedWarning "Over Speed flag";
CM_ SG_ 215 PCU_Temporary_Stop_Flag "Temporary Stop Flag";
CM_ SG_ 215 PCU_MaxBoostedVoltage "Maximum Achievable Boosted Voltage";
CM_ SG_ 215 PCU_Max_DischargePowerLmt_ShrTrm "This signal indicates maximum boost converter discharge power limit for the short term";
CM_ SG_ 215 PCU_Max_DischargePowerLmt "Availability Wout";
CM_ SG_ 215 PCU_Max_ChargePowerLmt "Availability Win";
CM_ SG_ 215 PCU_DriveReadyCompletion_Status "PCU Drive Ready Completion Status";
CM_ SG_ 215 PCU_Diagnostic_Code "PCU Diagnostic code";
CM_ SG_ 215 Output_Torque_Limit "Output Torque Limit for Differential Protection (Abs/positive values only)";
CM_ SG_ 215 MessageCounter_PCU_FD_1 "This signal is a counter used for safety checks strategies. This counter is incremented of 1 (one) unit at each frame transmission.";
CM_ SG_ 215 MAC_PCU_FD_1 "MAC";
CM_ SG_ 215 DMPI_TransmissionTemperature "Transmission Oil Teperature";
CM_ SG_ 215 DMPI_OilTemperatureSts "Transmission oil temperature status flag";
CM_ SG_ 215 CRC_PCU_FD_1 "CRC according to SAE J1850 standard at each frame transmission.";
CM_ SG_ 215 CODE_CLR_DMPI "Clear emission related faults";
CM_ SG_ 215 Cntr_PCU_FD_1 "Cntr";
CM_ SG_ 215 BoostConverterFailureSts "Boost Converter Failure Status";
CM_ SG_ 215 BoostConverterDerateReason "Boost Converter Derate Reason";
CM_ SG_ 215 BoostConv_UpperIGBT_TempFltd "Boost converter lower IGBT temperature";
CM_ SG_ 215 BoostConv_ReactorTemp "Boost converter reactor temperature";
CM_ SG_ 215 BoostConv_LowerIGBT_TempFltd "Boost converter upper IGBT temperature";
CM_ SG_ 2654486588 SourceNodeIdentifier "Source Node Identifier";
CM_ SG_ 2654486588 CBV_bit6_PartialNtwInfBit "Partial Network Information Bit (PNI)";
CM_ SG_ 2654486588 CBV_bit4_ActiveWakeupBit "Active Wakeup Bit";
CM_ SG_ 2654486588 CBV_bit3_NMCoordinatorBit "NM Coordinator Sleep Bit";
CM_ SG_ 2654486588 CBV_bit0_RepeatMessageRequestBit "Repeat Message Request Bit";
CM_ SG_ 2654486594 SourceNodeIdentifier "Source Node Identifier";
CM_ SG_ 2654486594 CBV_bit6_PartialNtwInfBit "Partial Network Information Bit (PNI)";
CM_ SG_ 2654486594 CBV_bit4_ActiveWakeupBit "Active Wakeup Bit";
CM_ SG_ 2654486594 CBV_bit3_NMCoordinatorBit "NM Coordinator Sleep Bit";
CM_ SG_ 2654486594 CBV_bit0_RepeatMessageRequestBit "Repeat Message Request Bit";
CM_ SG_ 214 UDCMin_Unlim_MCPB_2 "Minimum DC voltage limit before linear generator derating Consider Max or Min torque. Default 36V";
CM_ SG_ 214 UDCMin_Unlim_MCPA_2 "Minimum DC voltage limit before linear generator derating Consider Max or Min torque. Default 36V";
CM_ SG_ 214 UDCMax_Unlim_MCPB_2 "Maximum DC voltage limit before linear generator derating Consider Max or Min torque. Default 52V";
CM_ SG_ 214 UDCMax_Unlim_MCPA_2 "Maximum DC voltage limit before linear generator derating Consider Max or Min torque. Default 52V";
CM_ SG_ 214 TqGrdtLim_MCPB_2 "Positive or Negative Torque Gradient applied for Torque Control Mode and Speed Control Mode. Default 1000Nm/s";
CM_ SG_ 214 TqGrdtLim_MCPA_2 "Positive or Negative Torque Gradient applied for Torque Control Mode and Speed Control Mode. Default 1000Nm/s";
CM_ SG_ 214 TorqueCommand_MCPB_2 "Torque command for MCPB";
CM_ SG_ 214 TorqueCommand_MCPA_2 "Torque command for MCPA";
CM_ SG_ 214 TargetMotorRPM_MCPB_2 "Target Motor RPM for MCPB";
CM_ SG_ 214 TargetMotorRPM_MCPA_2 "Target Motor RPM for MCPA";
CM_ SG_ 214 SpdGrdtLim_MCPB_2 "Positive or negative (symetric) Speed Request Gradient applicable on both sign only for Speed Control Mode. Default 25,000 rpm/s";
CM_ SG_ 214 SpdGrdtLim_MCPA_2 "Positive or negative (symetric) Speed Request Gradient applicable on both sign only for Speed Control Mode. Default 25,000 rpm/s";
CM_ SG_ 214 Mtr_6SO_Request_MCPB_2 "Six Switch Open Request  for MCPB (1=RequestActive; 0=RequestNotActive)";
CM_ SG_ 214 Mtr_6SO_Request_MCPA_2 "Six Switch Open Request  for MCPA (1=RequestActive; 0=RequestNotActive)";
CM_ SG_ 214 ModeCommand_MCPB_2 "Mode command for MCPB";
CM_ SG_ 214 ModeCommand_MCPA_2 "Mode command for MCPA";
CM_ SG_ 214 MinTorque_Limit_MCPB_2 "Minimum Limit of Electric Machine torque defined by Master Controller";
CM_ SG_ 214 MinTorque_Limit_MCPA_2 "Minimum Limit of Electric Machine torque defined by Master Controller";
CM_ SG_ 214 MessageCounter_INVTARGET1_2 "This signal is a counter used for safety checks strategies. This counter is incremented of 1 (one) unit at each frame transmission.";
CM_ SG_ 214 MaxTorque_Limit_MCPB_2 "Maximum Limit of Electric Machine torque defined by Master Controller";
CM_ SG_ 214 MaxTorque_Limit_MCPA_2 "Maximum Limit of Electric Machine torque defined by Master Controller";
CM_ SG_ 214 MAC_INVTARGET1_2 "MAC";
CM_ SG_ 214 LgsDiagCldStrtCndMet_MCPB_2 "Legislated diagnostics cold start conditions met; true = [1]";
CM_ SG_ 214 LgsDiagCldStrtCndFltPr_MCPB_2 "Legislated diagnostics cold start conditions fault present; true = [1]";
CM_ SG_ 214 HVBatVlt_V_2 "High voltage battery pack voltage Validity";
CM_ SG_ 214 EVCU_END_Request_Flag_2 "PCU END Request Flag";
CM_ SG_ 214 CRC_INVTARGET1_2 "CRC according to SAE J1850 standard at each frame transmission.";
CM_ SG_ 214 Cntr_INVTARGET1_2 "Cntr";
CM_ SG_ 214 Boost_Torque_Margin_MCPB "Motor B Torque marging for Boost converter Voltage";
CM_ SG_ 214 Boost_Torque_Margin_MCPA "Motor A Torque marging for Boost converter Voltage";
CM_ SG_ 214 AEMD_Torque_BoostVolt_Margin "AEMD Torque for Boost Voltage Control";
CM_ SG_ 214 AEMD_Sclr_Gn_MCPB_2 "MCPB AEMD Scalar Gain";
CM_ SG_ 214 AEMD_Sclr_Gn_MCPA_2 "MCPA AEMD Scalar Gain";
CM_ SG_ 214 AEMD_MinOffset_MCPB_2 "MCPB AEMD Min Offset";
CM_ SG_ 214 AEMD_MinOffset_MCPA_2 "MCPA AEMD Min Offset";
CM_ SG_ 214 AEMD_MaxOffset_MCPB_2 "MCPB AEMD Max Offset";
CM_ SG_ 214 AEMD_Cutoff_FreqLow_MCPB_2 "AEMD cut-off Frequency Low for MCPB";
CM_ SG_ 214 AEMD_Cutoff_FreqLow_MCPA_2 "AEMD cut-off Frequency Low for MCPA";
CM_ SG_ 214 AEMD_Cutoff_FreqHigh_MCPB_2 "AEMD cut-off Frequency High for MCPB";
CM_ SG_ 214 AEMD_Cutoff_FreqHigh_MCPA_2 "AEMD cut-off Frequency High for MCPA";
CM_ SG_ 2564682188 N_PDU "This signal is used for diagnostic purposes";
CM_ SG_ 2564682444 N_PDU "This signal is used for diagnostic purposes";
CM_ SG_ 2564682307 N_PDU "This signal is used for diagnostic purposes";
CM_ SG_ 2564682051 N_PDU "This signal is used for diagnostic purposes";
CM_ SG_ 2564485580 N_PDU "This signal is used for diagnostic purposes";
CM_ SG_ 2564485836 N_PDU "This signal is used for diagnostic purposes";
CM_ SG_ 2564485699 N_PDU "This signal is used for diagnostic purposes";
CM_ SG_ 2564485443 N_PDU "This signal is used for diagnostic purposes";
CM_ SG_ 2564476145 N_PDU "This signal is used for diagnostic purposes";
CM_ SG_ 2564476146 N_PDU "This signal is used for diagnostic purposes";
CM_ SG_ 2564441074 N_PDU "This signal is used for diagnostic purposes";
CM_ SG_ 2564441073 N_PDU "This signal is used for diagnostic purposes";
CM_ SG_ 504 MCPB_DC_Current_P "Motor B DC Current";
CM_ SG_ 504 MC_MCPB_STATUS "Message counter according to SAE J1850 standard that has to be calculated from bit 63 to bit 8 at each frame transmission.";
CM_ SG_ 504 CRC_MCPB_STATUS "CRC according to SAE J1850 standard that has to be calculated from bit 63 to bit 8 at each frame transmission.";
CM_ SG_ 503 MCPA_DC_Current_P "Motor A DC Current";
CM_ SG_ 503 MC_MCPA_STATUS "Message counter according to SAE J1850 standard that has to be calculated from bit 63 to bit 8 at each frame transmission.";
CM_ SG_ 503 CRC_MCPA_STATUS "CRC according to SAE J1850 standard that has to be calculated from bit 63 to bit 8 at each frame transmission.";
CM_ SG_ 1072 EVSE_ThrshldVoltage "Voltage to judge changing stop which shall be used for the protection of traction battery";
CM_ SG_ 1072 EVSE_RemainingSec "Remaining charging time managed by charger";
CM_ SG_ 1072 EVSE_RemainingMin "Remaining charging time managed by charger";
CM_ SG_ 1072 EVSE_EnergizingState "Status flag indicating a state in which voltage can be applied from charge";
CM_ SG_ 1072 EVSE_ChargingSystemError "flag indicating vehicle error or charger error";
CM_ SG_ 1072 EVSE_CHAdeMOProtocol "Charging control version that charger corresponds with.";
CM_ SG_ 1072 EVSE_BatteryCompatibilty "available output voltage of charger  is not suitable for charging to battery.";
CM_ SG_ 1072 CdM_ExtFun_Thres_Volt "\"Voltage to judge changing stop which shall be  used for the protection of traction battery.\"";
CM_ SG_ 1072 CdM_Charger_connector_lock "This signal was created for LP3. Requester is Daniel Grobbel. CR number is 17996.";
CM_ SG_ 1072 CdM_Avail_output_current_EXT "Maximum output current value of the charger";
CM_ SG_ 1073 VehicleDriveSts "flag indicating position of a shift lever of vehicle";
CM_ SG_ 1073 TotalBatteryCapacity "Charged rate of battery calculated by vehicle that is only used for display on charger";
CM_ SG_ 1073 StopReqBeforeCharge "Stop request of charging control from vehicle before charging";
CM_ SG_ 1073 MinBatteryPackVoltage "The minimum voltage of the vehicle traction battery";
CM_ SG_ 1073 EVCU_CP3Cmd "Vehicle charge permission command for CHAdeMO";
CM_ SG_ 1073 EVContactorSts "closing / opening of EV contactor and a termination of weldingdetection";
CM_ SG_ 1073 DisplaySOC "Charged rate of battery calculated by vehicle that is only used for display on charger";
CM_ SG_ 1073 ChargedReferenceConstant "Fixed value to display charged rate";
CM_ SG_ 1073 ChargedCurrentMin "Minimum current required for charging";
CM_ SG_ 1073 CHAdeMOProtocol "Charging control version that charger corresponds with.";
CM_ SG_ 1073 CdM_Remained_batt_capacity "CHAdeMO - Remaining capacitance of the vehicle mounted battery (used so that the charger can display charge rate) - Backwords Compatibily";
CM_ SG_ 1073 CdM_ExtFun_Veh_HC_Control_Comp "A flag indicating a vehicle is compatible with high current control";
CM_ SG_ 1073 CdM_ExtFun_Veh_Dyn_Control_Comp "Flag indicating vehicle that is compatible with dynamic control.";
CM_ SG_ 1073 CdM_ExtFun_Min_Batt_Volt "The minimum voltage of the vehicle traction battery (voltage at the vehicle inlet).";
CM_ SG_ 1073 CdM_Chrg_current_req_ext "Current value that vehicle requests charger during charging";
CM_ SG_ 1073 BattVoltDeviationErr "Error flag indicating a voltage deviation";
CM_ SG_ 577 QualifyDriveCycle "Qualified Drive Cycle";
CM_ SG_ 220 VIN_MSG_OBD "VIN Message Information";
CM_ SG_ 220 VIN_DATA_OBD "VIN Digits (8 bit ascii encoded)";
CM_ SG_ 220 VehicleSpeedVSOSig_OBD "It is the average vehicle speed calculated.";
CM_ SG_ 220 OperationalModeSts_OBD "Used to give information about the Operational Mode Status";
CM_ SG_ 220 MessageCounter_PT_SYSTEM_FD_OBD "This signal is a counter used for safety checks strategies. This counter is incremented of 1 (one) unit at each frame transmission.";
CM_ SG_ 220 IgnitionOnCounter_OBD "Used to give information about the number of ignition cycles the vehicle has experienced";
CM_ SG_ 220 ExternalTemperatureC_OBD "Used to indicate the external temperature value in °C";
CM_ SG_ 220 EngineSpeedFailSts_W_OBD "Used to indicate if a Fail is present for the engine speed";
CM_ SG_ 220 EngineSpeed_W_OBD "It gives information on C-CAN network about engine speed";
CM_ SG_ 220 TotalOdometer_OBD "Used to give information about the total odometer value in km.";
CM_ SG_ 220 CRC_PT_SYSTEM_FD_OBD "CRC according to SAE J1850 standard at each frame transmission.";
CM_ SG_ 220 CmdIgnSts_OBD "Used to give information about the key selector position";
CM_ SG_ 220 Battery_Volt_1_OBD "Battery Volt 1 signal";
CM_ SG_ 200 TotalAxle_Rq_BSM_PT "Combined axle traction torque request";
CM_ SG_ 200 TotalAxle_Min_Rq_BSM_PT "Combined axle traction torque min limit flag. Active = [1]";
CM_ SG_ 200 TotalAxle_Max_Rq_BSM_PT "Combined axle traction torque max limit flag. Active = [1]";
CM_ SG_ 200 Total_AxleTorque_Static_PT "Static Axle Torque (effective total Axle torque)";
CM_ SG_ 200 RHFWheelSpeed_PT "This is the value of the right front wheel speed";
CM_ SG_ 200 RHF_WheelSensorFailSts_PT "This signal indicates the fail status of RHF sensor";
CM_ SG_ 200 MessageCounter_PT_SYSTEM_FD_4 "This signal is a counter used for safety checks strategies. This counter is incremented of 1 (one) unit at each frame transmission.";
CM_ SG_ 200 LHFWheelSpeed_PT "This is the value of the left front wheel speed";
CM_ SG_ 200 LHF_WheelSensorFailSts_PT "This signal indicates the fail status of LHF sensor";
CM_ SG_ 200 Ft_RrCouplingTrq_Desired_PT "Desired center differential torque (Nm)";
CM_ SG_ 200 Ft_RrCouplingTrq_Actual_PT "Actual center differential torque (Nm)";
CM_ SG_ 200 ESCActive_PT "This signal is set to Active when the brake intervention by ESC is active.";
CM_ SG_ 200 CRC_PT_SYSTEM_FD_4 "CRC according to SAE J1850 standard at each frame transmission.";
CM_ SG_ 200 Axle_TorqueStatic_D_TTC_PT "Driver requested Axle torque (filtered/ torque shaped)";
CM_ SG_ 200 Axle_TorqueStatic_D_TTC_ESC_PT "Driver requested Axle torque (filtered/ torque shaped) including ESC torque intervention";
CM_ SG_ 200 AWDSysStat_PT "Transfer Case Status";
CM_ SG_ 200 AtmosphericPressureFailSts_PT "This signal indicates if the atmospheric pressure sensor is in fail.";
CM_ SG_ 200 AtmosphericPressure_W_PT "It indicates atmospheric pressure read from the atmospheric pressure sensor";
BA_DEF_ BO_ "CANFD_BRS" ENUM "0","1";
BA_DEF_ BO_ "VFrameFormat" ENUM "StandardCAN","ExtendedCAN","reserved","reserved","reserved","reserved","reserved","reserved","reserved","reserved","reserved","reserved","reserved","reserved","StandardCAN_FD","ExtendedCAN_FD";
BA_DEF_ BO_ "CanTpFcFrameId" HEX 0 2147483647;
BA_DEF_ BO_ "DiagConnection" HEX 0 65535;
BA_DEF_ BO_ "DiagState" ENUM "No","Yes";
BA_DEF_ BO_ "NmAsrMessage" ENUM "No","Yes";
BA_DEF_ BO_ "GenMsgDelayTime" INT 0 65535;
BA_DEF_ BO_ "GenMsgCycleTime" INT 0 65535;
BA_DEF_ BO_ "GenMsgCycleTimeFast" INT 0 65535;
BA_DEF_ BO_ "GenMsgStartDelayTime" INT 0 65535;
BA_DEF_ BO_ "GenMsgILSupport" ENUM "No","Yes";
BA_DEF_ BO_ "GenMsgNrOfRepetition" INT 0 255;
BA_DEF_ BO_ "GenMsgSendType" ENUM "Cyclic","NotUsed","NotUsed","NotUsed","NotUsed","NotUsed","NotUsed","NotUsed","NoMsgSendType";
BA_DEF_ BO_ "NmMessage" ENUM "No","Yes";
BA_DEF_ BO_ "DiagResponse" ENUM "No","Yes";
BA_DEF_ BO_ "Type" ENUM "P","C","PE","COC","PE_Cntrl","E","E_Cntrl","OC","S","BAF","DC","EM","MM","ISO-TP","-";
BA_DEF_ BO_ "DiagRequest" ENUM "No","Yes";
BA_DEF_ SG_ "GenSigTimeoutTime_SGW" INT 0 65535;
BA_DEF_ SG_ "GenSigTimeoutTime_PBWM" INT 0 65535;
BA_DEF_ SG_ "GenSigTimeoutTime_IDCM" INT 0 65535;
BA_DEF_ SG_ "GenSigTimeoutTime_EVCU2" INT 0 65535;
BA_DEF_ SG_ "GenSigTimeoutTime_ECM" INT 0 65535;
BA_DEF_ SG_ "GenSigTimeoutTime_DMPI" INT 0 65535;
BA_DEF_ SG_ "GenSigTimeoutTime_BPCM" INT 0 65535;
BA_DEF_ SG_ "GenSigTimeoutTime_AGSM" INT 0 65535;
BA_DEF_ SG_ "SystemSignalLongSymbol" STRING ;
BA_DEF_ SG_ "GenSigSendType" ENUM "NotUsed","OnWrite","OnWriteWithRepetition","OnChange","OnChangeWithRepetition","IfActive","IfActiveWithRepetition","NoSigSendType";
BA_DEF_ SG_ "GenSigInactiveValue" INT 0 2147483647;
BA_DEF_ SG_ "GenSigStartValue" INT 0 2147483647;
BA_DEF_DEF_ "CANFD_BRS" "0";
BA_DEF_DEF_ "VFrameFormat" "StandardCAN_FD";
BA_DEF_DEF_ "CanTpFcFrameId" 2147483647;
BA_DEF_DEF_ "DiagConnection" 0;
BA_DEF_DEF_ "DiagState" "No";
BA_DEF_DEF_ "NmAsrMessage" "No";
BA_DEF_DEF_ "GenMsgDelayTime" 0;
BA_DEF_DEF_ "GenMsgCycleTime" 0;
BA_DEF_DEF_ "GenMsgCycleTimeFast" 0;
BA_DEF_DEF_ "GenMsgStartDelayTime" 0;
BA_DEF_DEF_ "GenMsgILSupport" "No";
BA_DEF_DEF_ "GenMsgNrOfRepetition" 0;
BA_DEF_DEF_ "GenMsgSendType" "NoMsgSendType";
BA_DEF_DEF_ "NmMessage" "No";
BA_DEF_DEF_ "DiagResponse" "No";
BA_DEF_DEF_ "Type" "-";
BA_DEF_DEF_ "DiagRequest" "No";
BA_DEF_DEF_ "GenSigTimeoutTime_SGW" 2500;
BA_DEF_DEF_ "GenSigTimeoutTime_PBWM" 2500;
BA_DEF_DEF_ "GenSigTimeoutTime_IDCM" 2500;
BA_DEF_DEF_ "GenSigTimeoutTime_EVCU2" 2500;
BA_DEF_DEF_ "GenSigTimeoutTime_ECM" 2500;
BA_DEF_DEF_ "GenSigTimeoutTime_DMPI" 2500;
BA_DEF_DEF_ "GenSigTimeoutTime_BPCM" 2500;
BA_DEF_DEF_ "GenSigTimeoutTime_AGSM" 2500;
BA_DEF_DEF_ "SystemSignalLongSymbol" "";
BA_DEF_DEF_ "GenSigSendType" "NoSigSendType";
BA_DEF_DEF_ "GenSigInactiveValue" 0;
BA_DEF_DEF_ "GenSigStartValue" 0;
BA_ "CANFD_BRS" BO_ 2654408730 1;
BA_ "VFrameFormat" BO_ 2654408730 15;
BA_ "CanTpFcFrameId" BO_ 2654408730 506929178;
BA_ "GenMsgDelayTime" BO_ 2654408730 20;
BA_ "GenMsgILSupport" BO_ 2654408730 1;
BA_ "Type" BO_ 2654408730 13;
BA_ "CANFD_BRS" BO_ 212 1;
BA_ "GenMsgCycleTime" BO_ 212 10;
BA_ "GenMsgILSupport" BO_ 212 1;
BA_ "GenMsgSendType" BO_ 212 0;
BA_ "Type" BO_ 212 1;
BA_ "CANFD_BRS" BO_ 211 1;
BA_ "GenMsgCycleTime" BO_ 211 10;
BA_ "GenMsgILSupport" BO_ 211 1;
BA_ "GenMsgSendType" BO_ 211 0;
BA_ "Type" BO_ 211 1;
BA_ "CANFD_BRS" BO_ 2654339132 1;
BA_ "VFrameFormat" BO_ 2654339132 15;
BA_ "GenMsgCycleTime" BO_ 2654339132 1000;
BA_ "GenMsgILSupport" BO_ 2654339132 1;
BA_ "GenMsgSendType" BO_ 2654339132 0;
BA_ "Type" BO_ 2654339132 1;
BA_ "CANFD_BRS" BO_ 2654339138 1;
BA_ "VFrameFormat" BO_ 2654339138 15;
BA_ "GenMsgCycleTime" BO_ 2654339138 1000;
BA_ "GenMsgILSupport" BO_ 2654339138 1;
BA_ "GenMsgSendType" BO_ 2654339138 0;
BA_ "Type" BO_ 2654339138 1;
BA_ "CANFD_BRS" BO_ 1811 1;
BA_ "GenMsgDelayTime" BO_ 1811 20;
BA_ "GenMsgCycleTime" BO_ 1811 1000;
BA_ "GenMsgILSupport" BO_ 1811 1;
BA_ "GenMsgSendType" BO_ 1811 0;
BA_ "Type" BO_ 1811 1;
BA_ "CANFD_BRS" BO_ 215 1;
BA_ "GenMsgCycleTime" BO_ 215 10;
BA_ "GenMsgILSupport" BO_ 215 1;
BA_ "GenMsgSendType" BO_ 215 0;
BA_ "Type" BO_ 215 1;
BA_ "CANFD_BRS" BO_ 2654486588 1;
BA_ "VFrameFormat" BO_ 2654486588 15;
BA_ "NmAsrMessage" BO_ 2654486588 1;
BA_ "NmMessage" BO_ 2654486588 1;
BA_ "Type" BO_ 2654486588 8;
BA_ "CANFD_BRS" BO_ 2654486594 1;
BA_ "VFrameFormat" BO_ 2654486594 15;
BA_ "NmAsrMessage" BO_ 2654486594 1;
BA_ "NmMessage" BO_ 2654486594 1;
BA_ "Type" BO_ 2654486594 8;
BA_ "CANFD_BRS" BO_ 214 1;
BA_ "GenMsgCycleTime" BO_ 214 5;
BA_ "GenMsgILSupport" BO_ 214 1;
BA_ "GenMsgSendType" BO_ 214 0;
BA_ "Type" BO_ 214 1;
BA_ "CANFD_BRS" BO_ 2651930684 1;
BA_ "VFrameFormat" BO_ 2651930684 15;
BA_ "GenMsgILSupport" BO_ 2651930684 1;
BA_ "Type" BO_ 2651930684 11;
BA_ "CANFD_BRS" BO_ 2651930690 1;
BA_ "VFrameFormat" BO_ 2651930690 15;
BA_ "GenMsgILSupport" BO_ 2651930690 1;
BA_ "Type" BO_ 2651930690 11;
BA_ "VFrameFormat" BO_ 2564682188 1;
BA_ "DiagConnection" BO_ 2564682188 61900;
BA_ "DiagResponse" BO_ 2564682188 1;
BA_ "Type" BO_ 2564682188 8;
BA_ "CANFD_BRS" BO_ 2564682444 1;
BA_ "VFrameFormat" BO_ 2564682444 15;
BA_ "DiagConnection" BO_ 2564682444 62156;
BA_ "DiagResponse" BO_ 2564682444 1;
BA_ "Type" BO_ 2564682444 8;
BA_ "CANFD_BRS" BO_ 2564682307 1;
BA_ "VFrameFormat" BO_ 2564682307 15;
BA_ "DiagConnection" BO_ 2564682307 62019;
BA_ "DiagResponse" BO_ 2564682307 1;
BA_ "Type" BO_ 2564682307 8;
BA_ "VFrameFormat" BO_ 2564682051 1;
BA_ "DiagConnection" BO_ 2564682051 61763;
BA_ "DiagResponse" BO_ 2564682051 1;
BA_ "Type" BO_ 2564682051 8;
BA_ "VFrameFormat" BO_ 2564485580 1;
BA_ "DiagConnection" BO_ 2564485580 61900;
BA_ "DiagResponse" BO_ 2564485580 1;
BA_ "Type" BO_ 2564485580 8;
BA_ "CANFD_BRS" BO_ 2564485836 1;
BA_ "VFrameFormat" BO_ 2564485836 15;
BA_ "DiagConnection" BO_ 2564485836 62156;
BA_ "DiagResponse" BO_ 2564485836 1;
BA_ "Type" BO_ 2564485836 8;
BA_ "CANFD_BRS" BO_ 2564485699 1;
BA_ "VFrameFormat" BO_ 2564485699 15;
BA_ "DiagConnection" BO_ 2564485699 62019;
BA_ "DiagResponse" BO_ 2564485699 1;
BA_ "Type" BO_ 2564485699 8;
BA_ "VFrameFormat" BO_ 2564485443 1;
BA_ "DiagConnection" BO_ 2564485443 61763;
BA_ "DiagResponse" BO_ 2564485443 1;
BA_ "Type" BO_ 2564485443 8;
BA_ "VFrameFormat" BO_ 2564476145 1;
BA_ "DiagConnection" BO_ 2564476145 61900;
BA_ "Type" BO_ 2564476145 8;
BA_ "DiagRequest" BO_ 2564476145 1;
BA_ "CANFD_BRS" BO_ 2564476146 1;
BA_ "VFrameFormat" BO_ 2564476146 15;
BA_ "DiagConnection" BO_ 2564476146 62156;
BA_ "Type" BO_ 2564476146 8;
BA_ "DiagRequest" BO_ 2564476146 1;
BA_ "CANFD_BRS" BO_ 2564441074 1;
BA_ "VFrameFormat" BO_ 2564441074 15;
BA_ "DiagConnection" BO_ 2564441074 62019;
BA_ "Type" BO_ 2564441074 8;
BA_ "DiagRequest" BO_ 2564441074 1;
BA_ "VFrameFormat" BO_ 2564441073 1;
BA_ "DiagConnection" BO_ 2564441073 61763;
BA_ "Type" BO_ 2564441073 8;
BA_ "DiagRequest" BO_ 2564441073 1;
BA_ "CANFD_BRS" BO_ 504 1;
BA_ "GenMsgCycleTime" BO_ 504 20;
BA_ "GenMsgILSupport" BO_ 504 1;
BA_ "GenMsgSendType" BO_ 504 0;
BA_ "Type" BO_ 504 1;
BA_ "CANFD_BRS" BO_ 503 1;
BA_ "GenMsgCycleTime" BO_ 503 20;
BA_ "GenMsgILSupport" BO_ 503 1;
BA_ "GenMsgSendType" BO_ 503 0;
BA_ "Type" BO_ 503 1;
BA_ "CANFD_BRS" BO_ 124 1;
BA_ "GenMsgILSupport" BO_ 124 1;
BA_ "Type" BO_ 124 8;
BA_ "CANFD_BRS" BO_ 127 1;
BA_ "GenMsgILSupport" BO_ 127 1;
BA_ "Type" BO_ 127 8;
BA_ "CANFD_BRS" BO_ 123 1;
BA_ "GenMsgILSupport" BO_ 123 1;
BA_ "Type" BO_ 123 8;
BA_ "CANFD_BRS" BO_ 126 1;
BA_ "GenMsgILSupport" BO_ 126 1;
BA_ "Type" BO_ 126 8;
BA_ "CANFD_BRS" BO_ 1072 1;
BA_ "GenMsgCycleTime" BO_ 1072 100;
BA_ "GenMsgILSupport" BO_ 1072 1;
BA_ "GenMsgSendType" BO_ 1072 0;
BA_ "Type" BO_ 1072 1;
BA_ "CANFD_BRS" BO_ 1073 1;
BA_ "GenMsgCycleTime" BO_ 1073 100;
BA_ "GenMsgILSupport" BO_ 1073 1;
BA_ "GenMsgSendType" BO_ 1073 0;
BA_ "Type" BO_ 1073 1;
BA_ "CANFD_BRS" BO_ 577 1;
BA_ "GenMsgDelayTime" BO_ 577 20;
BA_ "GenMsgCycleTime" BO_ 577 1000;
BA_ "GenMsgILSupport" BO_ 577 1;
BA_ "GenMsgSendType" BO_ 577 0;
BA_ "Type" BO_ 577 3;
BA_ "CANFD_BRS" BO_ 220 1;
BA_ "GenMsgCycleTime" BO_ 220 10;
BA_ "GenMsgILSupport" BO_ 220 1;
BA_ "GenMsgSendType" BO_ 220 0;
BA_ "Type" BO_ 220 1;
BA_ "CANFD_BRS" BO_ 200 1;
BA_ "GenMsgCycleTime" BO_ 200 10;
BA_ "GenMsgILSupport" BO_ 200 1;
BA_ "GenMsgSendType" BO_ 200 0;
BA_ "Type" BO_ 200 1;
BA_ "GenSigTimeoutTime_SGW" SG_ 215 PCU_Max_ChargePowerLmt 0;
BA_ "GenSigTimeoutTime_PBWM" SG_ 215 PCU_Max_ChargePowerLmt 0;
BA_ "GenSigTimeoutTime_IDCM" SG_ 215 PCU_Max_ChargePowerLmt 0;
BA_ "GenSigTimeoutTime_ECM" SG_ 215 PCU_Max_ChargePowerLmt 0;
BA_ "GenSigTimeoutTime_DMPI" SG_ 215 PCU_Max_ChargePowerLmt 0;
BA_ "GenSigTimeoutTime_BPCM" SG_ 215 PCU_Max_ChargePowerLmt 0;
BA_ "GenSigTimeoutTime_AGSM" SG_ 215 PCU_Max_ChargePowerLmt 0;
BA_ "GenSigTimeoutTime_SGW" SG_ 215 Output_Torque_Limit 0;
BA_ "GenSigTimeoutTime_PBWM" SG_ 215 Output_Torque_Limit 0;
BA_ "GenSigTimeoutTime_IDCM" SG_ 215 Output_Torque_Limit 0;
BA_ "GenSigTimeoutTime_ECM" SG_ 215 Output_Torque_Limit 0;
BA_ "GenSigTimeoutTime_DMPI" SG_ 215 Output_Torque_Limit 0;
BA_ "GenSigTimeoutTime_BPCM" SG_ 215 Output_Torque_Limit 0;
BA_ "GenSigTimeoutTime_AGSM" SG_ 215 Output_Torque_Limit 0;
BA_ "GenSigStartValue" SG_ 215 Output_Torque_Limit 32767;
BA_ "GenSigTimeoutTime_SGW" SG_ 215 BoostConv_UpperIGBT_TempFltd 0;
BA_ "GenSigTimeoutTime_PBWM" SG_ 215 BoostConv_UpperIGBT_TempFltd 0;
BA_ "GenSigTimeoutTime_IDCM" SG_ 215 BoostConv_UpperIGBT_TempFltd 0;
BA_ "GenSigTimeoutTime_ECM" SG_ 215 BoostConv_UpperIGBT_TempFltd 0;
BA_ "GenSigTimeoutTime_SGW" SG_ 215 BoostConverter_Current 0;
BA_ "GenSigTimeoutTime_PBWM" SG_ 215 BoostConverter_Current 0;
BA_ "GenSigTimeoutTime_IDCM" SG_ 215 BoostConverter_Current 0;
BA_ "GenSigTimeoutTime_ECM" SG_ 215 BoostConverter_Current 0;
BA_ "GenSigTimeoutTime_DMPI" SG_ 215 BoostConverter_Current 0;
BA_ "GenSigTimeoutTime_BPCM" SG_ 215 BoostConverter_Current 0;
BA_ "GenSigTimeoutTime_AGSM" SG_ 215 BoostConverter_Current 0;
BA_ "GenSigStartValue" SG_ 215 BoostConverter_Current 16384;
BA_ "GenSigTimeoutTime_SGW" SG_ 215 CODE_CLR_DMPI 0;
BA_ "GenSigTimeoutTime_PBWM" SG_ 215 CODE_CLR_DMPI 0;
BA_ "GenSigTimeoutTime_IDCM" SG_ 215 CODE_CLR_DMPI 0;
BA_ "GenSigTimeoutTime_EVCU2" SG_ 215 CODE_CLR_DMPI 0;
BA_ "GenSigTimeoutTime_DMPI" SG_ 215 CODE_CLR_DMPI 0;
BA_ "GenSigTimeoutTime_BPCM" SG_ 215 CODE_CLR_DMPI 0;
BA_ "GenSigTimeoutTime_AGSM" SG_ 215 CODE_CLR_DMPI 0;
BA_ "GenSigTimeoutTime_SGW" SG_ 215 REPRGD_PFC_CLR_DMPI 0;
BA_ "GenSigTimeoutTime_PBWM" SG_ 215 REPRGD_PFC_CLR_DMPI 0;
BA_ "GenSigTimeoutTime_IDCM" SG_ 215 REPRGD_PFC_CLR_DMPI 0;
BA_ "GenSigTimeoutTime_EVCU2" SG_ 215 REPRGD_PFC_CLR_DMPI 0;
BA_ "GenSigTimeoutTime_DMPI" SG_ 215 REPRGD_PFC_CLR_DMPI 0;
BA_ "GenSigTimeoutTime_BPCM" SG_ 215 REPRGD_PFC_CLR_DMPI 0;
BA_ "GenSigTimeoutTime_AGSM" SG_ 215 REPRGD_PFC_CLR_DMPI 0;
BA_ "GenSigTimeoutTime_SGW" SG_ 215 DMPI_TransmissionTemperature 0;
BA_ "GenSigTimeoutTime_PBWM" SG_ 215 DMPI_TransmissionTemperature 0;
BA_ "GenSigTimeoutTime_IDCM" SG_ 215 DMPI_TransmissionTemperature 0;
BA_ "GenSigTimeoutTime_ECM" SG_ 215 DMPI_TransmissionTemperature 0;
BA_ "GenSigTimeoutTime_DMPI" SG_ 215 DMPI_TransmissionTemperature 0;
BA_ "GenSigTimeoutTime_BPCM" SG_ 215 DMPI_TransmissionTemperature 0;
BA_ "GenSigTimeoutTime_AGSM" SG_ 215 DMPI_TransmissionTemperature 0;
BA_ "GenSigTimeoutTime_SGW" SG_ 215 BoostConverterDerateReason 0;
BA_ "GenSigTimeoutTime_PBWM" SG_ 215 BoostConverterDerateReason 0;
BA_ "GenSigTimeoutTime_IDCM" SG_ 215 BoostConverterDerateReason 0;
BA_ "GenSigTimeoutTime_ECM" SG_ 215 BoostConverterDerateReason 0;
BA_ "GenSigTimeoutTime_DMPI" SG_ 215 BoostConverterDerateReason 0;
BA_ "GenSigTimeoutTime_BPCM" SG_ 215 BoostConverterDerateReason 0;
BA_ "GenSigTimeoutTime_AGSM" SG_ 215 BoostConverterDerateReason 0;
BA_ "GenSigTimeoutTime_SGW" SG_ 215 DMPI_OilTemperatureSts 0;
BA_ "GenSigTimeoutTime_PBWM" SG_ 215 DMPI_OilTemperatureSts 0;
BA_ "GenSigTimeoutTime_IDCM" SG_ 215 DMPI_OilTemperatureSts 0;
BA_ "GenSigTimeoutTime_ECM" SG_ 215 DMPI_OilTemperatureSts 0;
BA_ "GenSigTimeoutTime_DMPI" SG_ 215 DMPI_OilTemperatureSts 0;
BA_ "GenSigTimeoutTime_BPCM" SG_ 215 DMPI_OilTemperatureSts 0;
BA_ "GenSigTimeoutTime_AGSM" SG_ 215 DMPI_OilTemperatureSts 0;
BA_ "GenSigTimeoutTime_SGW" SG_ 215 PCU_Max_DischargePowerLmt_ShrTrm 0;
BA_ "GenSigTimeoutTime_PBWM" SG_ 215 PCU_Max_DischargePowerLmt_ShrTrm 0;
BA_ "GenSigTimeoutTime_IDCM" SG_ 215 PCU_Max_DischargePowerLmt_ShrTrm 0;
BA_ "GenSigTimeoutTime_ECM" SG_ 215 PCU_Max_DischargePowerLmt_ShrTrm 0;
BA_ "GenSigTimeoutTime_DMPI" SG_ 215 PCU_Max_DischargePowerLmt_ShrTrm 0;
BA_ "GenSigTimeoutTime_BPCM" SG_ 215 PCU_Max_DischargePowerLmt_ShrTrm 0;
BA_ "GenSigTimeoutTime_AGSM" SG_ 215 PCU_Max_DischargePowerLmt_ShrTrm 0;
BA_ "GenSigTimeoutTime_SGW" SG_ 214 AEMD_Sclr_Gn_MCPA_2 0;
BA_ "GenSigTimeoutTime_PBWM" SG_ 214 AEMD_Sclr_Gn_MCPA_2 0;
BA_ "GenSigTimeoutTime_IDCM" SG_ 214 AEMD_Sclr_Gn_MCPA_2 0;
BA_ "GenSigTimeoutTime_EVCU2" SG_ 214 AEMD_Sclr_Gn_MCPA_2 0;
BA_ "GenSigTimeoutTime_ECM" SG_ 214 AEMD_Sclr_Gn_MCPA_2 0;
BA_ "GenSigTimeoutTime_BPCM" SG_ 214 AEMD_Sclr_Gn_MCPA_2 0;
BA_ "GenSigTimeoutTime_AGSM" SG_ 214 AEMD_Sclr_Gn_MCPA_2 0;
BA_ "GenSigTimeoutTime_SGW" SG_ 214 AEMD_Sclr_Gn_MCPB_2 0;
BA_ "GenSigTimeoutTime_PBWM" SG_ 214 AEMD_Sclr_Gn_MCPB_2 0;
BA_ "GenSigTimeoutTime_IDCM" SG_ 214 AEMD_Sclr_Gn_MCPB_2 0;
BA_ "GenSigTimeoutTime_EVCU2" SG_ 214 AEMD_Sclr_Gn_MCPB_2 0;
BA_ "GenSigTimeoutTime_ECM" SG_ 214 AEMD_Sclr_Gn_MCPB_2 0;
BA_ "GenSigTimeoutTime_BPCM" SG_ 214 AEMD_Sclr_Gn_MCPB_2 0;
BA_ "GenSigTimeoutTime_AGSM" SG_ 214 AEMD_Sclr_Gn_MCPB_2 0;
BA_ "GenSigTimeoutTime_SGW" SG_ 214 AEMD_Torque_BoostVolt_Margin 0;
BA_ "GenSigTimeoutTime_PBWM" SG_ 214 AEMD_Torque_BoostVolt_Margin 0;
BA_ "GenSigTimeoutTime_IDCM" SG_ 214 AEMD_Torque_BoostVolt_Margin 0;
BA_ "GenSigTimeoutTime_EVCU2" SG_ 214 AEMD_Torque_BoostVolt_Margin 0;
BA_ "GenSigTimeoutTime_ECM" SG_ 214 AEMD_Torque_BoostVolt_Margin 0;
BA_ "GenSigTimeoutTime_BPCM" SG_ 214 AEMD_Torque_BoostVolt_Margin 0;
BA_ "GenSigTimeoutTime_AGSM" SG_ 214 AEMD_Torque_BoostVolt_Margin 0;
BA_ "GenSigTimeoutTime_SGW" SG_ 214 Boost_Torque_Margin_MCPB 0;
BA_ "GenSigTimeoutTime_PBWM" SG_ 214 Boost_Torque_Margin_MCPB 0;
BA_ "GenSigTimeoutTime_IDCM" SG_ 214 Boost_Torque_Margin_MCPB 0;
BA_ "GenSigTimeoutTime_EVCU2" SG_ 214 Boost_Torque_Margin_MCPB 0;
BA_ "GenSigTimeoutTime_ECM" SG_ 214 Boost_Torque_Margin_MCPB 0;
BA_ "GenSigTimeoutTime_BPCM" SG_ 214 Boost_Torque_Margin_MCPB 0;
BA_ "GenSigTimeoutTime_AGSM" SG_ 214 Boost_Torque_Margin_MCPB 0;
BA_ "GenSigStartValue" SG_ 214 Boost_Torque_Margin_MCPB 512;
BA_ "GenSigTimeoutTime_SGW" SG_ 214 Boost_Torque_Margin_MCPA 0;
BA_ "GenSigTimeoutTime_PBWM" SG_ 214 Boost_Torque_Margin_MCPA 0;
BA_ "GenSigTimeoutTime_IDCM" SG_ 214 Boost_Torque_Margin_MCPA 0;
BA_ "GenSigTimeoutTime_EVCU2" SG_ 214 Boost_Torque_Margin_MCPA 0;
BA_ "GenSigTimeoutTime_ECM" SG_ 214 Boost_Torque_Margin_MCPA 0;
BA_ "GenSigTimeoutTime_BPCM" SG_ 214 Boost_Torque_Margin_MCPA 0;
BA_ "GenSigTimeoutTime_AGSM" SG_ 214 Boost_Torque_Margin_MCPA 0;
BA_ "GenSigStartValue" SG_ 214 Boost_Torque_Margin_MCPA 512;
BA_ "GenSigTimeoutTime_SGW" SG_ 214 MinTorque_Limit_MCPA_2 0;
BA_ "GenSigTimeoutTime_PBWM" SG_ 214 MinTorque_Limit_MCPA_2 0;
BA_ "GenSigTimeoutTime_IDCM" SG_ 214 MinTorque_Limit_MCPA_2 0;
BA_ "GenSigTimeoutTime_EVCU2" SG_ 214 MinTorque_Limit_MCPA_2 0;
BA_ "GenSigTimeoutTime_ECM" SG_ 214 MinTorque_Limit_MCPA_2 0;
BA_ "GenSigTimeoutTime_BPCM" SG_ 214 MinTorque_Limit_MCPA_2 0;
BA_ "GenSigTimeoutTime_AGSM" SG_ 214 MinTorque_Limit_MCPA_2 0;
BA_ "GenSigTimeoutTime_BPCM" SG_ 214 MinTorque_Limit_MCPB_2 0;
BA_ "GenSigTimeoutTime_AGSM" SG_ 214 MinTorque_Limit_MCPB_2 0;
BA_ "GenSigTimeoutTime_SGW" SG_ 214 AEMD_Cutoff_FreqHigh_MCPA_2 0;
BA_ "GenSigTimeoutTime_PBWM" SG_ 214 AEMD_Cutoff_FreqHigh_MCPA_2 0;
BA_ "GenSigTimeoutTime_IDCM" SG_ 214 AEMD_Cutoff_FreqHigh_MCPA_2 0;
BA_ "GenSigTimeoutTime_EVCU2" SG_ 214 AEMD_Cutoff_FreqHigh_MCPA_2 0;
BA_ "GenSigTimeoutTime_ECM" SG_ 214 AEMD_Cutoff_FreqHigh_MCPA_2 0;
BA_ "GenSigTimeoutTime_BPCM" SG_ 214 AEMD_Cutoff_FreqHigh_MCPA_2 0;
BA_ "GenSigTimeoutTime_AGSM" SG_ 214 AEMD_Cutoff_FreqHigh_MCPA_2 0;
BA_ "GenSigTimeoutTime_SGW" SG_ 214 AEMD_Cutoff_FreqHigh_MCPB_2 0;
BA_ "GenSigTimeoutTime_PBWM" SG_ 214 AEMD_Cutoff_FreqHigh_MCPB_2 0;
BA_ "GenSigTimeoutTime_IDCM" SG_ 214 AEMD_Cutoff_FreqHigh_MCPB_2 0;
BA_ "GenSigTimeoutTime_EVCU2" SG_ 214 AEMD_Cutoff_FreqHigh_MCPB_2 0;
BA_ "GenSigTimeoutTime_ECM" SG_ 214 AEMD_Cutoff_FreqHigh_MCPB_2 0;
BA_ "GenSigTimeoutTime_BPCM" SG_ 214 AEMD_Cutoff_FreqHigh_MCPB_2 0;
BA_ "GenSigTimeoutTime_AGSM" SG_ 214 AEMD_Cutoff_FreqHigh_MCPB_2 0;
BA_ "GenSigTimeoutTime_SGW" SG_ 214 AEMD_Cutoff_FreqLow_MCPA_2 0;
BA_ "GenSigTimeoutTime_PBWM" SG_ 214 AEMD_Cutoff_FreqLow_MCPA_2 0;
BA_ "GenSigTimeoutTime_IDCM" SG_ 214 AEMD_Cutoff_FreqLow_MCPA_2 0;
BA_ "GenSigTimeoutTime_EVCU2" SG_ 214 AEMD_Cutoff_FreqLow_MCPA_2 0;
BA_ "GenSigTimeoutTime_ECM" SG_ 214 AEMD_Cutoff_FreqLow_MCPA_2 0;
BA_ "GenSigTimeoutTime_BPCM" SG_ 214 AEMD_Cutoff_FreqLow_MCPA_2 0;
BA_ "GenSigTimeoutTime_AGSM" SG_ 214 AEMD_Cutoff_FreqLow_MCPA_2 0;
BA_ "GenSigTimeoutTime_SGW" SG_ 214 AEMD_Cutoff_FreqLow_MCPB_2 0;
BA_ "GenSigTimeoutTime_PBWM" SG_ 214 AEMD_Cutoff_FreqLow_MCPB_2 0;
BA_ "GenSigTimeoutTime_IDCM" SG_ 214 AEMD_Cutoff_FreqLow_MCPB_2 0;
BA_ "GenSigTimeoutTime_EVCU2" SG_ 214 AEMD_Cutoff_FreqLow_MCPB_2 0;
BA_ "GenSigTimeoutTime_ECM" SG_ 214 AEMD_Cutoff_FreqLow_MCPB_2 0;
BA_ "GenSigTimeoutTime_BPCM" SG_ 214 AEMD_Cutoff_FreqLow_MCPB_2 0;
BA_ "GenSigTimeoutTime_AGSM" SG_ 214 AEMD_Cutoff_FreqLow_MCPB_2 0;
BA_ "GenSigTimeoutTime_SGW" SG_ 214 AEMD_MaxOffset_MCPB_2 0;
BA_ "GenSigTimeoutTime_PBWM" SG_ 214 AEMD_MaxOffset_MCPB_2 0;
BA_ "GenSigTimeoutTime_IDCM" SG_ 214 AEMD_MaxOffset_MCPB_2 0;
BA_ "GenSigTimeoutTime_EVCU2" SG_ 214 AEMD_MaxOffset_MCPB_2 0;
BA_ "GenSigTimeoutTime_ECM" SG_ 214 AEMD_MaxOffset_MCPB_2 0;
BA_ "GenSigTimeoutTime_BPCM" SG_ 214 AEMD_MaxOffset_MCPB_2 0;
BA_ "GenSigTimeoutTime_AGSM" SG_ 214 AEMD_MaxOffset_MCPB_2 0;
BA_ "GenSigTimeoutTime_SGW" SG_ 214 AEMD_MinOffset_MCPA_2 0;
BA_ "GenSigTimeoutTime_PBWM" SG_ 214 AEMD_MinOffset_MCPA_2 0;
BA_ "GenSigTimeoutTime_IDCM" SG_ 214 AEMD_MinOffset_MCPA_2 0;
BA_ "GenSigTimeoutTime_EVCU2" SG_ 214 AEMD_MinOffset_MCPA_2 0;
BA_ "GenSigTimeoutTime_ECM" SG_ 214 AEMD_MinOffset_MCPA_2 0;
BA_ "GenSigTimeoutTime_BPCM" SG_ 214 AEMD_MinOffset_MCPA_2 0;
BA_ "GenSigTimeoutTime_AGSM" SG_ 214 AEMD_MinOffset_MCPA_2 0;
BA_ "GenSigStartValue" SG_ 214 AEMD_MinOffset_MCPA_2 4095;
BA_ "GenSigTimeoutTime_SGW" SG_ 214 AEMD_MinOffset_MCPB_2 0;
BA_ "GenSigTimeoutTime_PBWM" SG_ 214 AEMD_MinOffset_MCPB_2 0;
BA_ "GenSigTimeoutTime_IDCM" SG_ 214 AEMD_MinOffset_MCPB_2 0;
BA_ "GenSigTimeoutTime_EVCU2" SG_ 214 AEMD_MinOffset_MCPB_2 0;
BA_ "GenSigTimeoutTime_ECM" SG_ 214 AEMD_MinOffset_MCPB_2 0;
BA_ "GenSigTimeoutTime_BPCM" SG_ 214 AEMD_MinOffset_MCPB_2 0;
BA_ "GenSigTimeoutTime_AGSM" SG_ 214 AEMD_MinOffset_MCPB_2 0;
BA_ "GenSigStartValue" SG_ 214 AEMD_MinOffset_MCPB_2 4095;
BA_ "GenSigTimeoutTime_SGW" SG_ 214 Cntr_INVTARGET1_2 0;
BA_ "GenSigTimeoutTime_PBWM" SG_ 214 Cntr_INVTARGET1_2 0;
BA_ "GenSigTimeoutTime_IDCM" SG_ 214 Cntr_INVTARGET1_2 0;
BA_ "GenSigTimeoutTime_EVCU2" SG_ 214 Cntr_INVTARGET1_2 0;
BA_ "GenSigTimeoutTime_ECM" SG_ 214 Cntr_INVTARGET1_2 0;
BA_ "GenSigTimeoutTime_BPCM" SG_ 214 Cntr_INVTARGET1_2 0;
BA_ "GenSigTimeoutTime_AGSM" SG_ 214 Cntr_INVTARGET1_2 0;
BA_ "GenSigTimeoutTime_SGW" SG_ 214 CRC_INVTARGET1_2 0;
BA_ "GenSigTimeoutTime_PBWM" SG_ 214 CRC_INVTARGET1_2 0;
BA_ "GenSigTimeoutTime_IDCM" SG_ 214 CRC_INVTARGET1_2 0;
BA_ "GenSigTimeoutTime_EVCU2" SG_ 214 CRC_INVTARGET1_2 0;
BA_ "GenSigTimeoutTime_ECM" SG_ 214 CRC_INVTARGET1_2 0;
BA_ "GenSigTimeoutTime_BPCM" SG_ 214 CRC_INVTARGET1_2 0;
BA_ "GenSigTimeoutTime_AGSM" SG_ 214 CRC_INVTARGET1_2 0;
BA_ "GenSigTimeoutTime_SGW" SG_ 214 EVCU_END_Request_Flag_2 0;
BA_ "GenSigTimeoutTime_PBWM" SG_ 214 EVCU_END_Request_Flag_2 0;
BA_ "GenSigTimeoutTime_IDCM" SG_ 214 EVCU_END_Request_Flag_2 0;
BA_ "GenSigTimeoutTime_EVCU2" SG_ 214 EVCU_END_Request_Flag_2 0;
BA_ "GenSigTimeoutTime_ECM" SG_ 214 EVCU_END_Request_Flag_2 0;
BA_ "GenSigTimeoutTime_BPCM" SG_ 214 EVCU_END_Request_Flag_2 0;
BA_ "GenSigTimeoutTime_AGSM" SG_ 214 EVCU_END_Request_Flag_2 0;
BA_ "GenSigTimeoutTime_SGW" SG_ 214 HVBatVlt_V_2 0;
BA_ "GenSigTimeoutTime_PBWM" SG_ 214 HVBatVlt_V_2 0;
BA_ "GenSigTimeoutTime_IDCM" SG_ 214 HVBatVlt_V_2 0;
BA_ "GenSigTimeoutTime_EVCU2" SG_ 214 HVBatVlt_V_2 0;
BA_ "GenSigTimeoutTime_ECM" SG_ 214 HVBatVlt_V_2 0;
BA_ "GenSigTimeoutTime_BPCM" SG_ 214 HVBatVlt_V_2 0;
BA_ "GenSigTimeoutTime_AGSM" SG_ 214 HVBatVlt_V_2 0;
BA_ "GenSigTimeoutTime_SGW" SG_ 214 LgsDiagCldStrtCndFltPr_MCPB_2 0;
BA_ "GenSigTimeoutTime_PBWM" SG_ 214 LgsDiagCldStrtCndFltPr_MCPB_2 0;
BA_ "GenSigTimeoutTime_IDCM" SG_ 214 LgsDiagCldStrtCndFltPr_MCPB_2 0;
BA_ "GenSigTimeoutTime_EVCU2" SG_ 214 LgsDiagCldStrtCndFltPr_MCPB_2 0;
BA_ "GenSigTimeoutTime_ECM" SG_ 214 LgsDiagCldStrtCndFltPr_MCPB_2 0;
BA_ "GenSigTimeoutTime_BPCM" SG_ 214 LgsDiagCldStrtCndFltPr_MCPB_2 0;
BA_ "GenSigTimeoutTime_AGSM" SG_ 214 LgsDiagCldStrtCndFltPr_MCPB_2 0;
BA_ "GenSigTimeoutTime_SGW" SG_ 214 LgsDiagCldStrtCndMet_MCPB_2 0;
BA_ "GenSigTimeoutTime_PBWM" SG_ 214 LgsDiagCldStrtCndMet_MCPB_2 0;
BA_ "GenSigTimeoutTime_IDCM" SG_ 214 LgsDiagCldStrtCndMet_MCPB_2 0;
BA_ "GenSigTimeoutTime_EVCU2" SG_ 214 LgsDiagCldStrtCndMet_MCPB_2 0;
BA_ "GenSigTimeoutTime_ECM" SG_ 214 LgsDiagCldStrtCndMet_MCPB_2 0;
BA_ "GenSigTimeoutTime_BPCM" SG_ 214 LgsDiagCldStrtCndMet_MCPB_2 0;
BA_ "GenSigTimeoutTime_AGSM" SG_ 214 LgsDiagCldStrtCndMet_MCPB_2 0;
BA_ "GenSigTimeoutTime_SGW" SG_ 214 MAC_INVTARGET1_2 0;
BA_ "GenSigTimeoutTime_PBWM" SG_ 214 MAC_INVTARGET1_2 0;
BA_ "GenSigTimeoutTime_IDCM" SG_ 214 MAC_INVTARGET1_2 0;
BA_ "GenSigTimeoutTime_EVCU2" SG_ 214 MAC_INVTARGET1_2 0;
BA_ "GenSigTimeoutTime_ECM" SG_ 214 MAC_INVTARGET1_2 0;
BA_ "GenSigTimeoutTime_BPCM" SG_ 214 MAC_INVTARGET1_2 0;
BA_ "GenSigTimeoutTime_AGSM" SG_ 214 MAC_INVTARGET1_2 0;
BA_ "GenSigTimeoutTime_SGW" SG_ 214 MaxTorque_Limit_MCPA_2 0;
BA_ "GenSigTimeoutTime_PBWM" SG_ 214 MaxTorque_Limit_MCPA_2 0;
BA_ "GenSigTimeoutTime_IDCM" SG_ 214 MaxTorque_Limit_MCPA_2 0;
BA_ "GenSigTimeoutTime_EVCU2" SG_ 214 MaxTorque_Limit_MCPA_2 0;
BA_ "GenSigTimeoutTime_ECM" SG_ 214 MaxTorque_Limit_MCPA_2 0;
BA_ "GenSigTimeoutTime_BPCM" SG_ 214 MaxTorque_Limit_MCPA_2 0;
BA_ "GenSigTimeoutTime_AGSM" SG_ 214 MaxTorque_Limit_MCPA_2 0;
BA_ "GenSigStartValue" SG_ 214 MaxTorque_Limit_MCPA_2 16382;
BA_ "GenSigTimeoutTime_SGW" SG_ 214 MaxTorque_Limit_MCPB_2 0;
BA_ "GenSigTimeoutTime_PBWM" SG_ 214 MaxTorque_Limit_MCPB_2 0;
BA_ "GenSigTimeoutTime_IDCM" SG_ 214 MaxTorque_Limit_MCPB_2 0;
BA_ "GenSigTimeoutTime_EVCU2" SG_ 214 MaxTorque_Limit_MCPB_2 0;
BA_ "GenSigTimeoutTime_ECM" SG_ 214 MaxTorque_Limit_MCPB_2 0;
BA_ "GenSigTimeoutTime_BPCM" SG_ 214 MaxTorque_Limit_MCPB_2 0;
BA_ "GenSigTimeoutTime_AGSM" SG_ 214 MaxTorque_Limit_MCPB_2 0;
BA_ "GenSigStartValue" SG_ 214 MaxTorque_Limit_MCPB_2 16382;
BA_ "GenSigTimeoutTime_SGW" SG_ 214 MessageCounter_INVTARGET1_2 0;
BA_ "GenSigTimeoutTime_PBWM" SG_ 214 MessageCounter_INVTARGET1_2 0;
BA_ "GenSigTimeoutTime_IDCM" SG_ 214 MessageCounter_INVTARGET1_2 0;
BA_ "GenSigTimeoutTime_EVCU2" SG_ 214 MessageCounter_INVTARGET1_2 0;
BA_ "GenSigTimeoutTime_ECM" SG_ 214 MessageCounter_INVTARGET1_2 0;
BA_ "GenSigTimeoutTime_BPCM" SG_ 214 MessageCounter_INVTARGET1_2 0;
BA_ "GenSigTimeoutTime_AGSM" SG_ 214 MessageCounter_INVTARGET1_2 0;
BA_ "GenSigTimeoutTime_SGW" SG_ 1811 CRC_ANCHOR3_REAL_TIME_CLOCK 0;
BA_ "GenSigTimeoutTime_PBWM" SG_ 1811 CRC_ANCHOR3_REAL_TIME_CLOCK 0;
BA_ "GenSigTimeoutTime_IDCM" SG_ 1811 CRC_ANCHOR3_REAL_TIME_CLOCK 0;
BA_ "GenSigTimeoutTime_EVCU2" SG_ 1811 CRC_ANCHOR3_REAL_TIME_CLOCK 0;
BA_ "GenSigTimeoutTime_ECM" SG_ 1811 CRC_ANCHOR3_REAL_TIME_CLOCK 0;
BA_ "GenSigTimeoutTime_BPCM" SG_ 1811 CRC_ANCHOR3_REAL_TIME_CLOCK 0;
BA_ "GenSigTimeoutTime_AGSM" SG_ 1811 CRC_ANCHOR3_REAL_TIME_CLOCK 0;
BA_ "GenSigTimeoutTime_SGW" SG_ 1811 MessageCounter_REAL_TIME_CLOCK 0;
BA_ "GenSigTimeoutTime_PBWM" SG_ 1811 MessageCounter_REAL_TIME_CLOCK 0;
BA_ "GenSigTimeoutTime_IDCM" SG_ 1811 MessageCounter_REAL_TIME_CLOCK 0;
BA_ "GenSigTimeoutTime_EVCU2" SG_ 1811 MessageCounter_REAL_TIME_CLOCK 0;
BA_ "GenSigTimeoutTime_ECM" SG_ 1811 MessageCounter_REAL_TIME_CLOCK 0;
BA_ "GenSigTimeoutTime_BPCM" SG_ 1811 MessageCounter_REAL_TIME_CLOCK 0;
BA_ "GenSigTimeoutTime_AGSM" SG_ 1811 MessageCounter_REAL_TIME_CLOCK 0;
BA_ "GenSigTimeoutTime_SGW" SG_ 1811 Real_Time_Clock 0;
BA_ "GenSigTimeoutTime_PBWM" SG_ 1811 Real_Time_Clock 0;
BA_ "GenSigTimeoutTime_IDCM" SG_ 1811 Real_Time_Clock 0;
BA_ "GenSigTimeoutTime_EVCU2" SG_ 1811 Real_Time_Clock 0;
BA_ "GenSigTimeoutTime_ECM" SG_ 1811 Real_Time_Clock 0;
BA_ "GenSigTimeoutTime_BPCM" SG_ 1811 Real_Time_Clock 0;
BA_ "GenSigTimeoutTime_AGSM" SG_ 1811 Real_Time_Clock 0;
BA_ "GenSigTimeoutTime_SGW" SG_ 1811 Real_Time_Validity 0;
BA_ "GenSigTimeoutTime_PBWM" SG_ 1811 Real_Time_Validity 0;
BA_ "GenSigTimeoutTime_IDCM" SG_ 1811 Real_Time_Validity 0;
BA_ "GenSigTimeoutTime_EVCU2" SG_ 1811 Real_Time_Validity 0;
BA_ "GenSigTimeoutTime_ECM" SG_ 1811 Real_Time_Validity 0;
BA_ "GenSigTimeoutTime_BPCM" SG_ 1811 Real_Time_Validity 0;
BA_ "GenSigTimeoutTime_AGSM" SG_ 1811 Real_Time_Validity 0;
BA_ "GenSigTimeoutTime_SGW" SG_ 220 ExternalTemperatureC_OBD 0;
BA_ "GenSigTimeoutTime_IDCM" SG_ 220 ExternalTemperatureC_OBD 0;
BA_ "GenSigTimeoutTime_EVCU2" SG_ 220 ExternalTemperatureC_OBD 0;
BA_ "GenSigTimeoutTime_ECM" SG_ 220 ExternalTemperatureC_OBD 0;
BA_ "GenSigTimeoutTime_AGSM" SG_ 220 ExternalTemperatureC_OBD 0;
BA_ "GenSigStartValue" SG_ 220 ExternalTemperatureC_OBD 511;
BA_ "GenSigTimeoutTime_SGW" SG_ 220 IgnitionOnCounter_OBD 0;
BA_ "GenSigTimeoutTime_IDCM" SG_ 220 IgnitionOnCounter_OBD 0;
BA_ "GenSigTimeoutTime_EVCU2" SG_ 220 IgnitionOnCounter_OBD 0;
BA_ "GenSigTimeoutTime_ECM" SG_ 220 IgnitionOnCounter_OBD 0;
BA_ "GenSigTimeoutTime_AGSM" SG_ 220 IgnitionOnCounter_OBD 0;
BA_ "GenSigTimeoutTime_SGW" SG_ 220 CRC_PT_SYSTEM_FD_OBD 0;
BA_ "GenSigTimeoutTime_PBWM" SG_ 220 CRC_PT_SYSTEM_FD_OBD 0;
BA_ "GenSigTimeoutTime_IDCM" SG_ 220 CRC_PT_SYSTEM_FD_OBD 0;
BA_ "GenSigTimeoutTime_EVCU2" SG_ 220 CRC_PT_SYSTEM_FD_OBD 0;
BA_ "GenSigTimeoutTime_SGW" SG_ 220 CmdIgnSts_OBD 0;
BA_ "GenSigTimeoutTime_EVCU2" SG_ 220 CmdIgnSts_OBD 0;
BA_ "GenSigTimeoutTime_SGW" SG_ 220 MessageCounter_PT_SYSTEM_FD_OBD 0;
BA_ "GenSigTimeoutTime_PBWM" SG_ 220 MessageCounter_PT_SYSTEM_FD_OBD 0;
BA_ "GenSigTimeoutTime_IDCM" SG_ 220 MessageCounter_PT_SYSTEM_FD_OBD 0;
BA_ "GenSigTimeoutTime_EVCU2" SG_ 220 MessageCounter_PT_SYSTEM_FD_OBD 0;
BA_ "GenSigTimeoutTime_SGW" SG_ 220 VIN_MSG_OBD 0;
BA_ "GenSigTimeoutTime_IDCM" SG_ 220 VIN_MSG_OBD 0;
BA_ "GenSigTimeoutTime_EVCU2" SG_ 220 VIN_MSG_OBD 0;
BA_ "GenSigTimeoutTime_ECM" SG_ 220 VIN_MSG_OBD 0;
BA_ "GenSigTimeoutTime_BPCM" SG_ 220 VIN_MSG_OBD 0;
BA_ "GenSigTimeoutTime_AGSM" SG_ 220 VIN_MSG_OBD 0;
BA_ "GenSigStartValue" SG_ 220 VIN_MSG_OBD 3;
BA_ "GenSigTimeoutTime_SGW" SG_ 577 QualifyDriveCycle 0;
BA_ "GenSigTimeoutTime_PBWM" SG_ 577 QualifyDriveCycle 0;
BA_ "GenSigTimeoutTime_IDCM" SG_ 577 QualifyDriveCycle 0;
BA_ "GenSigTimeoutTime_EVCU2" SG_ 577 QualifyDriveCycle 0;
BA_ "GenSigTimeoutTime_ECM" SG_ 577 QualifyDriveCycle 0;
BA_ "GenSigTimeoutTime_AGSM" SG_ 577 QualifyDriveCycle 0;
BA_ "GenSigSendType" SG_ 577 QualifyDriveCycle 3;
BA_ "GenSigTimeoutTime_SGW" SG_ 220 EngineSpeed_W_OBD 0;
BA_ "GenSigTimeoutTime_IDCM" SG_ 220 EngineSpeed_W_OBD 0;
BA_ "GenSigTimeoutTime_EVCU2" SG_ 220 EngineSpeed_W_OBD 0;
BA_ "GenSigTimeoutTime_AGSM" SG_ 220 EngineSpeed_W_OBD 0;
BA_ "GenSigTimeoutTime_SGW" SG_ 220 EngineSpeedFailSts_W_OBD 0;
BA_ "GenSigTimeoutTime_PBWM" SG_ 220 EngineSpeedFailSts_W_OBD 0;
BA_ "GenSigTimeoutTime_IDCM" SG_ 220 EngineSpeedFailSts_W_OBD 0;
BA_ "GenSigTimeoutTime_EVCU2" SG_ 220 EngineSpeedFailSts_W_OBD 0;
BA_ "GenSigTimeoutTime_ECM" SG_ 220 EngineSpeedFailSts_W_OBD 0;
BA_ "GenSigTimeoutTime_BPCM" SG_ 220 EngineSpeedFailSts_W_OBD 0;
BA_ "GenSigTimeoutTime_AGSM" SG_ 220 EngineSpeedFailSts_W_OBD 0;
BA_ "GenSigTimeoutTime_SGW" SG_ 220 OperationalModeSts_OBD 0;
BA_ "GenSigTimeoutTime_EVCU2" SG_ 220 OperationalModeSts_OBD 0;
BA_ "GenSigTimeoutTime_SGW" SG_ 220 TotalOdometer_OBD 0;
BA_ "GenSigTimeoutTime_IDCM" SG_ 220 TotalOdometer_OBD 0;
BA_ "GenSigTimeoutTime_EVCU2" SG_ 220 TotalOdometer_OBD 0;
BA_ "GenSigTimeoutTime_ECM" SG_ 220 TotalOdometer_OBD 0;
BA_ "GenSigTimeoutTime_AGSM" SG_ 220 TotalOdometer_OBD 0;
BA_ "GenSigTimeoutTime_SGW" SG_ 220 VehicleSpeedVSOSig_OBD 0;
BA_ "GenSigTimeoutTime_IDCM" SG_ 220 VehicleSpeedVSOSig_OBD 0;
BA_ "GenSigTimeoutTime_EVCU2" SG_ 220 VehicleSpeedVSOSig_OBD 0;
BA_ "GenSigTimeoutTime_ECM" SG_ 220 VehicleSpeedVSOSig_OBD 0;
BA_ "GenSigTimeoutTime_AGSM" SG_ 220 VehicleSpeedVSOSig_OBD 0;
BA_ "GenSigTimeoutTime_SGW" SG_ 220 VIN_DATA_OBD 0;
BA_ "GenSigTimeoutTime_IDCM" SG_ 220 VIN_DATA_OBD 0;
BA_ "GenSigTimeoutTime_EVCU2" SG_ 220 VIN_DATA_OBD 0;
BA_ "GenSigTimeoutTime_ECM" SG_ 220 VIN_DATA_OBD 0;
BA_ "GenSigTimeoutTime_BPCM" SG_ 220 VIN_DATA_OBD 0;
BA_ "GenSigTimeoutTime_AGSM" SG_ 220 VIN_DATA_OBD 0;
BA_ "GenSigTimeoutTime_SGW" SG_ 200 TotalAxle_Min_Rq_BSM_PT 0;
BA_ "GenSigTimeoutTime_PBWM" SG_ 200 TotalAxle_Min_Rq_BSM_PT 0;
BA_ "GenSigTimeoutTime_IDCM" SG_ 200 TotalAxle_Min_Rq_BSM_PT 0;
BA_ "GenSigTimeoutTime_EVCU2" SG_ 200 TotalAxle_Min_Rq_BSM_PT 0;
BA_ "GenSigTimeoutTime_ECM" SG_ 200 TotalAxle_Min_Rq_BSM_PT 0;
BA_ "GenSigTimeoutTime_BPCM" SG_ 200 TotalAxle_Min_Rq_BSM_PT 0;
BA_ "GenSigTimeoutTime_AGSM" SG_ 200 TotalAxle_Min_Rq_BSM_PT 0;
BA_ "GenSigTimeoutTime_SGW" SG_ 200 TotalAxle_Rq_BSM_PT 0;
BA_ "GenSigTimeoutTime_PBWM" SG_ 200 TotalAxle_Rq_BSM_PT 0;
BA_ "GenSigTimeoutTime_IDCM" SG_ 200 TotalAxle_Rq_BSM_PT 0;
BA_ "GenSigTimeoutTime_EVCU2" SG_ 200 TotalAxle_Rq_BSM_PT 0;
BA_ "GenSigTimeoutTime_ECM" SG_ 200 TotalAxle_Rq_BSM_PT 0;
BA_ "GenSigTimeoutTime_BPCM" SG_ 200 TotalAxle_Rq_BSM_PT 0;
BA_ "GenSigTimeoutTime_AGSM" SG_ 200 TotalAxle_Rq_BSM_PT 0;
BA_ "GenSigStartValue" SG_ 200 TotalAxle_Rq_BSM_PT 32767;
BA_ "GenSigTimeoutTime_SGW" SG_ 200 Ft_RrCouplingTrq_Actual_PT 0;
BA_ "GenSigTimeoutTime_PBWM" SG_ 200 Ft_RrCouplingTrq_Actual_PT 0;
BA_ "GenSigTimeoutTime_IDCM" SG_ 200 Ft_RrCouplingTrq_Actual_PT 0;
BA_ "GenSigTimeoutTime_EVCU2" SG_ 200 Ft_RrCouplingTrq_Actual_PT 0;
BA_ "GenSigTimeoutTime_ECM" SG_ 200 Ft_RrCouplingTrq_Actual_PT 0;
BA_ "GenSigTimeoutTime_BPCM" SG_ 200 Ft_RrCouplingTrq_Actual_PT 0;
BA_ "GenSigTimeoutTime_AGSM" SG_ 200 Ft_RrCouplingTrq_Actual_PT 0;
BA_ "GenSigStartValue" SG_ 200 Ft_RrCouplingTrq_Actual_PT 255;
BA_ "GenSigTimeoutTime_SGW" SG_ 200 Ft_RrCouplingTrq_Desired_PT 0;
BA_ "GenSigTimeoutTime_PBWM" SG_ 200 Ft_RrCouplingTrq_Desired_PT 0;
BA_ "GenSigTimeoutTime_IDCM" SG_ 200 Ft_RrCouplingTrq_Desired_PT 0;
BA_ "GenSigTimeoutTime_EVCU2" SG_ 200 Ft_RrCouplingTrq_Desired_PT 0;
BA_ "GenSigTimeoutTime_ECM" SG_ 200 Ft_RrCouplingTrq_Desired_PT 0;
BA_ "GenSigTimeoutTime_BPCM" SG_ 200 Ft_RrCouplingTrq_Desired_PT 0;
BA_ "GenSigTimeoutTime_AGSM" SG_ 200 Ft_RrCouplingTrq_Desired_PT 0;
BA_ "GenSigStartValue" SG_ 200 Ft_RrCouplingTrq_Desired_PT 255;
BA_ "GenSigTimeoutTime_SGW" SG_ 200 LHF_WheelSensorFailSts_PT 0;
BA_ "GenSigTimeoutTime_PBWM" SG_ 200 LHF_WheelSensorFailSts_PT 0;
BA_ "GenSigTimeoutTime_IDCM" SG_ 200 LHF_WheelSensorFailSts_PT 0;
BA_ "GenSigTimeoutTime_EVCU2" SG_ 200 LHF_WheelSensorFailSts_PT 0;
BA_ "GenSigTimeoutTime_ECM" SG_ 200 LHF_WheelSensorFailSts_PT 0;
BA_ "GenSigTimeoutTime_BPCM" SG_ 200 LHF_WheelSensorFailSts_PT 0;
BA_ "GenSigTimeoutTime_AGSM" SG_ 200 LHF_WheelSensorFailSts_PT 0;
BA_ "GenSigTimeoutTime_SGW" SG_ 200 LHFWheelSpeed_PT 0;
BA_ "GenSigTimeoutTime_PBWM" SG_ 200 LHFWheelSpeed_PT 0;
BA_ "GenSigTimeoutTime_IDCM" SG_ 200 LHFWheelSpeed_PT 0;
BA_ "GenSigTimeoutTime_EVCU2" SG_ 200 LHFWheelSpeed_PT 0;
BA_ "GenSigTimeoutTime_ECM" SG_ 200 LHFWheelSpeed_PT 0;
BA_ "GenSigTimeoutTime_BPCM" SG_ 200 LHFWheelSpeed_PT 0;
BA_ "GenSigTimeoutTime_AGSM" SG_ 200 LHFWheelSpeed_PT 0;
BA_ "GenSigTimeoutTime_SGW" SG_ 200 RHF_WheelSensorFailSts_PT 0;
BA_ "GenSigTimeoutTime_PBWM" SG_ 200 RHF_WheelSensorFailSts_PT 0;
BA_ "GenSigTimeoutTime_IDCM" SG_ 200 RHF_WheelSensorFailSts_PT 0;
BA_ "GenSigTimeoutTime_EVCU2" SG_ 200 RHF_WheelSensorFailSts_PT 0;
BA_ "GenSigTimeoutTime_ECM" SG_ 200 RHF_WheelSensorFailSts_PT 0;
BA_ "GenSigTimeoutTime_BPCM" SG_ 200 RHF_WheelSensorFailSts_PT 0;
BA_ "GenSigTimeoutTime_AGSM" SG_ 200 RHF_WheelSensorFailSts_PT 0;
BA_ "GenSigTimeoutTime_SGW" SG_ 200 RHFWheelSpeed_PT 0;
BA_ "GenSigTimeoutTime_PBWM" SG_ 200 RHFWheelSpeed_PT 0;
BA_ "GenSigTimeoutTime_IDCM" SG_ 200 RHFWheelSpeed_PT 0;
BA_ "GenSigTimeoutTime_EVCU2" SG_ 200 RHFWheelSpeed_PT 0;
BA_ "GenSigTimeoutTime_ECM" SG_ 200 RHFWheelSpeed_PT 0;
BA_ "GenSigTimeoutTime_BPCM" SG_ 200 RHFWheelSpeed_PT 0;
BA_ "GenSigTimeoutTime_AGSM" SG_ 200 RHFWheelSpeed_PT 0;
BA_ "GenSigTimeoutTime_SGW" SG_ 200 Total_AxleTorque_Static_PT 0;
BA_ "GenSigTimeoutTime_PBWM" SG_ 200 Total_AxleTorque_Static_PT 0;
BA_ "GenSigTimeoutTime_IDCM" SG_ 200 Total_AxleTorque_Static_PT 0;
BA_ "GenSigTimeoutTime_EVCU2" SG_ 200 Total_AxleTorque_Static_PT 0;
BA_ "GenSigTimeoutTime_ECM" SG_ 200 Total_AxleTorque_Static_PT 0;
BA_ "GenSigTimeoutTime_BPCM" SG_ 200 Total_AxleTorque_Static_PT 0;
BA_ "GenSigTimeoutTime_AGSM" SG_ 200 Total_AxleTorque_Static_PT 0;
BA_ "GenSigStartValue" SG_ 200 Total_AxleTorque_Static_PT 32767;
BA_ "GenSigTimeoutTime_SGW" SG_ 200 TotalAxle_Max_Rq_BSM_PT 0;
BA_ "GenSigTimeoutTime_PBWM" SG_ 200 TotalAxle_Max_Rq_BSM_PT 0;
BA_ "GenSigTimeoutTime_IDCM" SG_ 200 TotalAxle_Max_Rq_BSM_PT 0;
BA_ "GenSigTimeoutTime_EVCU2" SG_ 200 TotalAxle_Max_Rq_BSM_PT 0;
BA_ "GenSigTimeoutTime_ECM" SG_ 200 TotalAxle_Max_Rq_BSM_PT 0;
BA_ "GenSigTimeoutTime_BPCM" SG_ 200 TotalAxle_Max_Rq_BSM_PT 0;
BA_ "GenSigTimeoutTime_AGSM" SG_ 200 TotalAxle_Max_Rq_BSM_PT 0;
BA_ "GenSigTimeoutTime_SGW" SG_ 200 CRC_PT_SYSTEM_FD_4 0;
BA_ "GenSigTimeoutTime_PBWM" SG_ 200 CRC_PT_SYSTEM_FD_4 0;
BA_ "GenSigTimeoutTime_IDCM" SG_ 200 CRC_PT_SYSTEM_FD_4 0;
BA_ "GenSigTimeoutTime_EVCU2" SG_ 200 CRC_PT_SYSTEM_FD_4 0;
BA_ "GenSigTimeoutTime_ECM" SG_ 200 CRC_PT_SYSTEM_FD_4 0;
BA_ "GenSigTimeoutTime_BPCM" SG_ 200 CRC_PT_SYSTEM_FD_4 0;
BA_ "GenSigTimeoutTime_AGSM" SG_ 200 CRC_PT_SYSTEM_FD_4 0;
BA_ "GenSigTimeoutTime_SGW" SG_ 200 MessageCounter_PT_SYSTEM_FD_4 0;
BA_ "GenSigTimeoutTime_PBWM" SG_ 200 MessageCounter_PT_SYSTEM_FD_4 0;
BA_ "GenSigTimeoutTime_IDCM" SG_ 200 MessageCounter_PT_SYSTEM_FD_4 0;
BA_ "GenSigTimeoutTime_EVCU2" SG_ 200 MessageCounter_PT_SYSTEM_FD_4 0;
BA_ "GenSigTimeoutTime_ECM" SG_ 200 MessageCounter_PT_SYSTEM_FD_4 0;
BA_ "GenSigTimeoutTime_BPCM" SG_ 200 MessageCounter_PT_SYSTEM_FD_4 0;
BA_ "GenSigTimeoutTime_AGSM" SG_ 200 MessageCounter_PT_SYSTEM_FD_4 0;
BA_ "GenSigTimeoutTime_SGW" SG_ 220 Battery_Volt_1_OBD 0;
BA_ "GenSigTimeoutTime_IDCM" SG_ 220 Battery_Volt_1_OBD 0;
BA_ "GenSigTimeoutTime_EVCU2" SG_ 220 Battery_Volt_1_OBD 0;
BA_ "GenSigTimeoutTime_ECM" SG_ 220 Battery_Volt_1_OBD 0;
BA_ "GenSigTimeoutTime_AGSM" SG_ 220 Battery_Volt_1_OBD 0;
BA_ "GenSigTimeoutTime_SGW" SG_ 200 AtmosphericPressure_W_PT 0;
BA_ "GenSigTimeoutTime_PBWM" SG_ 200 AtmosphericPressure_W_PT 0;
BA_ "GenSigTimeoutTime_IDCM" SG_ 200 AtmosphericPressure_W_PT 0;
BA_ "GenSigTimeoutTime_EVCU2" SG_ 200 AtmosphericPressure_W_PT 0;
BA_ "GenSigTimeoutTime_ECM" SG_ 200 AtmosphericPressure_W_PT 0;
BA_ "GenSigTimeoutTime_BPCM" SG_ 200 AtmosphericPressure_W_PT 0;
BA_ "GenSigTimeoutTime_AGSM" SG_ 200 AtmosphericPressure_W_PT 0;
BA_ "GenSigStartValue" SG_ 200 AtmosphericPressure_W_PT 255;
BA_ "GenSigTimeoutTime_SGW" SG_ 200 AtmosphericPressureFailSts_PT 0;
BA_ "GenSigTimeoutTime_PBWM" SG_ 200 AtmosphericPressureFailSts_PT 0;
BA_ "GenSigTimeoutTime_IDCM" SG_ 200 AtmosphericPressureFailSts_PT 0;
BA_ "GenSigTimeoutTime_EVCU2" SG_ 200 AtmosphericPressureFailSts_PT 0;
BA_ "GenSigTimeoutTime_ECM" SG_ 200 AtmosphericPressureFailSts_PT 0;
BA_ "GenSigTimeoutTime_BPCM" SG_ 200 AtmosphericPressureFailSts_PT 0;
BA_ "GenSigTimeoutTime_AGSM" SG_ 200 AtmosphericPressureFailSts_PT 0;
BA_ "GenSigTimeoutTime_SGW" SG_ 200 AWDSysStat_PT 0;
BA_ "GenSigTimeoutTime_PBWM" SG_ 200 AWDSysStat_PT 0;
BA_ "GenSigTimeoutTime_IDCM" SG_ 200 AWDSysStat_PT 0;
BA_ "GenSigTimeoutTime_EVCU2" SG_ 200 AWDSysStat_PT 0;
BA_ "GenSigTimeoutTime_ECM" SG_ 200 AWDSysStat_PT 0;
BA_ "GenSigTimeoutTime_BPCM" SG_ 200 AWDSysStat_PT 0;
BA_ "GenSigTimeoutTime_AGSM" SG_ 200 AWDSysStat_PT 0;
BA_ "GenSigStartValue" SG_ 200 AWDSysStat_PT 7;
BA_ "GenSigTimeoutTime_SGW" SG_ 200 Axle_TorqueStatic_D_TTC_ESC_PT 0;
BA_ "GenSigTimeoutTime_PBWM" SG_ 200 Axle_TorqueStatic_D_TTC_ESC_PT 0;
BA_ "GenSigTimeoutTime_IDCM" SG_ 200 Axle_TorqueStatic_D_TTC_ESC_PT 0;
BA_ "GenSigTimeoutTime_EVCU2" SG_ 200 Axle_TorqueStatic_D_TTC_ESC_PT 0;
BA_ "GenSigTimeoutTime_ECM" SG_ 200 Axle_TorqueStatic_D_TTC_ESC_PT 0;
BA_ "GenSigTimeoutTime_BPCM" SG_ 200 Axle_TorqueStatic_D_TTC_ESC_PT 0;
BA_ "GenSigTimeoutTime_AGSM" SG_ 200 Axle_TorqueStatic_D_TTC_ESC_PT 0;
BA_ "GenSigStartValue" SG_ 200 Axle_TorqueStatic_D_TTC_ESC_PT 32767;
BA_ "GenSigTimeoutTime_SGW" SG_ 200 Axle_TorqueStatic_D_TTC_PT 0;
BA_ "GenSigTimeoutTime_PBWM" SG_ 200 Axle_TorqueStatic_D_TTC_PT 0;
BA_ "GenSigTimeoutTime_IDCM" SG_ 200 Axle_TorqueStatic_D_TTC_PT 0;
BA_ "GenSigTimeoutTime_EVCU2" SG_ 200 Axle_TorqueStatic_D_TTC_PT 0;
BA_ "GenSigTimeoutTime_ECM" SG_ 200 Axle_TorqueStatic_D_TTC_PT 0;
BA_ "GenSigTimeoutTime_BPCM" SG_ 200 Axle_TorqueStatic_D_TTC_PT 0;
BA_ "GenSigTimeoutTime_AGSM" SG_ 200 Axle_TorqueStatic_D_TTC_PT 0;
BA_ "GenSigStartValue" SG_ 200 Axle_TorqueStatic_D_TTC_PT 32767;
BA_ "GenSigTimeoutTime_SGW" SG_ 200 ESCActive_PT 0;
BA_ "GenSigTimeoutTime_PBWM" SG_ 200 ESCActive_PT 0;
BA_ "GenSigTimeoutTime_IDCM" SG_ 200 ESCActive_PT 0;
BA_ "GenSigTimeoutTime_EVCU2" SG_ 200 ESCActive_PT 0;
BA_ "GenSigTimeoutTime_ECM" SG_ 200 ESCActive_PT 0;
BA_ "GenSigTimeoutTime_BPCM" SG_ 200 ESCActive_PT 0;
BA_ "GenSigTimeoutTime_AGSM" SG_ 200 ESCActive_PT 0;
BA_ "GenSigTimeoutTime_AGSM" SG_ 503 MC_MCPA_STATUS 0;
BA_ "GenSigTimeoutTime_SGW" SG_ 503 MCPA_DC_Current_P 0;
BA_ "GenSigTimeoutTime_PBWM" SG_ 503 MCPA_DC_Current_P 0;
BA_ "GenSigTimeoutTime_IDCM" SG_ 503 MCPA_DC_Current_P 0;
BA_ "GenSigTimeoutTime_EVCU2" SG_ 503 MCPA_DC_Current_P 0;
BA_ "GenSigTimeoutTime_ECM" SG_ 503 MCPA_DC_Current_P 0;
BA_ "GenSigTimeoutTime_DMPI" SG_ 503 MCPA_DC_Current_P 0;
BA_ "GenSigTimeoutTime_AGSM" SG_ 503 MCPA_DC_Current_P 0;
BA_ "GenSigStartValue" SG_ 503 MCPA_DC_Current_P 16384;
BA_ "GenSigTimeoutTime_SGW" SG_ 504 CRC_MCPB_STATUS 0;
BA_ "GenSigTimeoutTime_PBWM" SG_ 504 CRC_MCPB_STATUS 0;
BA_ "GenSigTimeoutTime_IDCM" SG_ 504 CRC_MCPB_STATUS 0;
BA_ "GenSigTimeoutTime_EVCU2" SG_ 504 CRC_MCPB_STATUS 0;
BA_ "GenSigTimeoutTime_ECM" SG_ 504 CRC_MCPB_STATUS 0;
BA_ "GenSigTimeoutTime_DMPI" SG_ 504 CRC_MCPB_STATUS 0;
BA_ "GenSigTimeoutTime_AGSM" SG_ 504 CRC_MCPB_STATUS 0;
BA_ "GenSigTimeoutTime_SGW" SG_ 214 UDCMin_Unlim_MCPA_2 0;
BA_ "GenSigTimeoutTime_PBWM" SG_ 214 UDCMin_Unlim_MCPA_2 0;
BA_ "GenSigTimeoutTime_IDCM" SG_ 214 UDCMin_Unlim_MCPA_2 0;
BA_ "GenSigTimeoutTime_EVCU2" SG_ 214 UDCMin_Unlim_MCPA_2 0;
BA_ "GenSigTimeoutTime_ECM" SG_ 214 UDCMin_Unlim_MCPA_2 0;
BA_ "GenSigTimeoutTime_BPCM" SG_ 214 UDCMin_Unlim_MCPA_2 0;
BA_ "GenSigTimeoutTime_AGSM" SG_ 214 UDCMin_Unlim_MCPA_2 0;
BA_ "GenSigTimeoutTime_SGW" SG_ 214 UDCMin_Unlim_MCPB_2 0;
BA_ "GenSigTimeoutTime_PBWM" SG_ 214 UDCMin_Unlim_MCPB_2 0;
BA_ "GenSigTimeoutTime_IDCM" SG_ 214 UDCMin_Unlim_MCPB_2 0;
BA_ "GenSigTimeoutTime_EVCU2" SG_ 214 UDCMin_Unlim_MCPB_2 0;
BA_ "GenSigTimeoutTime_ECM" SG_ 214 UDCMin_Unlim_MCPB_2 0;
BA_ "GenSigTimeoutTime_BPCM" SG_ 214 UDCMin_Unlim_MCPB_2 0;
BA_ "GenSigTimeoutTime_AGSM" SG_ 214 UDCMin_Unlim_MCPB_2 0;
BA_ "GenSigTimeoutTime_SGW" SG_ 214 MinTorque_Limit_MCPB_2 0;
BA_ "GenSigTimeoutTime_PBWM" SG_ 214 MinTorque_Limit_MCPB_2 0;
BA_ "GenSigTimeoutTime_IDCM" SG_ 214 MinTorque_Limit_MCPB_2 0;
BA_ "GenSigTimeoutTime_EVCU2" SG_ 214 MinTorque_Limit_MCPB_2 0;
BA_ "GenSigTimeoutTime_ECM" SG_ 214 MinTorque_Limit_MCPB_2 0;
BA_ "GenSigTimeoutTime_SGW" SG_ 214 ModeCommand_MCPA_2 0;
BA_ "GenSigTimeoutTime_PBWM" SG_ 214 ModeCommand_MCPA_2 0;
BA_ "GenSigTimeoutTime_IDCM" SG_ 214 ModeCommand_MCPA_2 0;
BA_ "GenSigTimeoutTime_EVCU2" SG_ 214 ModeCommand_MCPA_2 0;
BA_ "GenSigTimeoutTime_ECM" SG_ 214 ModeCommand_MCPA_2 0;
BA_ "GenSigTimeoutTime_BPCM" SG_ 214 ModeCommand_MCPA_2 0;
BA_ "GenSigTimeoutTime_AGSM" SG_ 214 ModeCommand_MCPA_2 0;
BA_ "GenSigTimeoutTime_SGW" SG_ 214 ModeCommand_MCPB_2 0;
BA_ "GenSigTimeoutTime_PBWM" SG_ 214 ModeCommand_MCPB_2 0;
BA_ "GenSigTimeoutTime_IDCM" SG_ 214 ModeCommand_MCPB_2 0;
BA_ "GenSigTimeoutTime_EVCU2" SG_ 214 ModeCommand_MCPB_2 0;
BA_ "GenSigTimeoutTime_ECM" SG_ 214 ModeCommand_MCPB_2 0;
BA_ "GenSigTimeoutTime_BPCM" SG_ 214 ModeCommand_MCPB_2 0;
BA_ "GenSigTimeoutTime_AGSM" SG_ 214 ModeCommand_MCPB_2 0;
BA_ "GenSigTimeoutTime_SGW" SG_ 214 Mtr_6SO_Request_MCPA_2 0;
BA_ "GenSigTimeoutTime_PBWM" SG_ 214 Mtr_6SO_Request_MCPA_2 0;
BA_ "GenSigTimeoutTime_IDCM" SG_ 214 Mtr_6SO_Request_MCPA_2 0;
BA_ "GenSigTimeoutTime_EVCU2" SG_ 214 Mtr_6SO_Request_MCPA_2 0;
BA_ "GenSigTimeoutTime_ECM" SG_ 214 Mtr_6SO_Request_MCPA_2 0;
BA_ "GenSigTimeoutTime_BPCM" SG_ 214 Mtr_6SO_Request_MCPA_2 0;
BA_ "GenSigTimeoutTime_AGSM" SG_ 214 Mtr_6SO_Request_MCPA_2 0;
BA_ "GenSigTimeoutTime_BPCM" SG_ 214 Mtr_6SO_Request_MCPB_2 0;
BA_ "GenSigTimeoutTime_AGSM" SG_ 214 Mtr_6SO_Request_MCPB_2 0;
BA_ "GenSigTimeoutTime_SGW" SG_ 214 Mtr_6SO_Request_MCPB_2 0;
BA_ "GenSigTimeoutTime_PBWM" SG_ 214 Mtr_6SO_Request_MCPB_2 0;
BA_ "GenSigTimeoutTime_IDCM" SG_ 214 Mtr_6SO_Request_MCPB_2 0;
BA_ "GenSigTimeoutTime_EVCU2" SG_ 214 Mtr_6SO_Request_MCPB_2 0;
BA_ "GenSigTimeoutTime_ECM" SG_ 214 Mtr_6SO_Request_MCPB_2 0;
BA_ "GenSigTimeoutTime_SGW" SG_ 214 SpdGrdtLim_MCPA_2 0;
BA_ "GenSigTimeoutTime_PBWM" SG_ 214 SpdGrdtLim_MCPA_2 0;
BA_ "GenSigTimeoutTime_IDCM" SG_ 214 SpdGrdtLim_MCPA_2 0;
BA_ "GenSigTimeoutTime_EVCU2" SG_ 214 SpdGrdtLim_MCPA_2 0;
BA_ "GenSigTimeoutTime_ECM" SG_ 214 SpdGrdtLim_MCPA_2 0;
BA_ "GenSigTimeoutTime_BPCM" SG_ 214 SpdGrdtLim_MCPA_2 0;
BA_ "GenSigTimeoutTime_AGSM" SG_ 214 SpdGrdtLim_MCPA_2 0;
BA_ "GenSigTimeoutTime_SGW" SG_ 214 SpdGrdtLim_MCPB_2 0;
BA_ "GenSigTimeoutTime_PBWM" SG_ 214 SpdGrdtLim_MCPB_2 0;
BA_ "GenSigTimeoutTime_IDCM" SG_ 214 SpdGrdtLim_MCPB_2 0;
BA_ "GenSigTimeoutTime_EVCU2" SG_ 214 SpdGrdtLim_MCPB_2 0;
BA_ "GenSigTimeoutTime_ECM" SG_ 214 SpdGrdtLim_MCPB_2 0;
BA_ "GenSigTimeoutTime_BPCM" SG_ 214 SpdGrdtLim_MCPB_2 0;
BA_ "GenSigTimeoutTime_AGSM" SG_ 214 SpdGrdtLim_MCPB_2 0;
BA_ "GenSigTimeoutTime_SGW" SG_ 214 TargetMotorRPM_MCPA_2 0;
BA_ "GenSigTimeoutTime_PBWM" SG_ 214 TargetMotorRPM_MCPA_2 0;
BA_ "GenSigTimeoutTime_IDCM" SG_ 214 TargetMotorRPM_MCPA_2 0;
BA_ "GenSigTimeoutTime_EVCU2" SG_ 214 TargetMotorRPM_MCPA_2 0;
BA_ "GenSigTimeoutTime_ECM" SG_ 214 TargetMotorRPM_MCPA_2 0;
BA_ "GenSigTimeoutTime_BPCM" SG_ 214 TargetMotorRPM_MCPA_2 0;
BA_ "GenSigTimeoutTime_AGSM" SG_ 214 TargetMotorRPM_MCPA_2 0;
BA_ "GenSigStartValue" SG_ 214 TargetMotorRPM_MCPA_2 32768;
BA_ "GenSigTimeoutTime_SGW" SG_ 214 TargetMotorRPM_MCPB_2 0;
BA_ "GenSigTimeoutTime_PBWM" SG_ 214 TargetMotorRPM_MCPB_2 0;
BA_ "GenSigTimeoutTime_IDCM" SG_ 214 TargetMotorRPM_MCPB_2 0;
BA_ "GenSigTimeoutTime_EVCU2" SG_ 214 TargetMotorRPM_MCPB_2 0;
BA_ "GenSigTimeoutTime_ECM" SG_ 214 TargetMotorRPM_MCPB_2 0;
BA_ "GenSigTimeoutTime_BPCM" SG_ 214 TargetMotorRPM_MCPB_2 0;
BA_ "GenSigTimeoutTime_AGSM" SG_ 214 TargetMotorRPM_MCPB_2 0;
BA_ "GenSigStartValue" SG_ 214 TargetMotorRPM_MCPB_2 32768;
BA_ "GenSigTimeoutTime_SGW" SG_ 214 TorqueCommand_MCPA_2 0;
BA_ "GenSigTimeoutTime_PBWM" SG_ 214 TorqueCommand_MCPA_2 0;
BA_ "GenSigTimeoutTime_IDCM" SG_ 214 TorqueCommand_MCPA_2 0;
BA_ "GenSigTimeoutTime_EVCU2" SG_ 214 TorqueCommand_MCPA_2 0;
BA_ "GenSigTimeoutTime_ECM" SG_ 214 TorqueCommand_MCPA_2 0;
BA_ "GenSigTimeoutTime_BPCM" SG_ 214 TorqueCommand_MCPA_2 0;
BA_ "GenSigTimeoutTime_AGSM" SG_ 214 TorqueCommand_MCPA_2 0;
BA_ "GenSigStartValue" SG_ 214 TorqueCommand_MCPA_2 4096;
BA_ "GenSigTimeoutTime_SGW" SG_ 214 TorqueCommand_MCPB_2 0;
BA_ "GenSigTimeoutTime_PBWM" SG_ 214 TorqueCommand_MCPB_2 0;
BA_ "GenSigTimeoutTime_IDCM" SG_ 214 TorqueCommand_MCPB_2 0;
BA_ "GenSigTimeoutTime_EVCU2" SG_ 214 TorqueCommand_MCPB_2 0;
BA_ "GenSigTimeoutTime_ECM" SG_ 214 TorqueCommand_MCPB_2 0;
BA_ "GenSigTimeoutTime_BPCM" SG_ 214 TorqueCommand_MCPB_2 0;
BA_ "GenSigTimeoutTime_AGSM" SG_ 214 TorqueCommand_MCPB_2 0;
BA_ "GenSigStartValue" SG_ 214 TorqueCommand_MCPB_2 4096;
BA_ "GenSigTimeoutTime_SGW" SG_ 214 TqGrdtLim_MCPA_2 0;
BA_ "GenSigTimeoutTime_PBWM" SG_ 214 TqGrdtLim_MCPA_2 0;
BA_ "GenSigTimeoutTime_IDCM" SG_ 214 TqGrdtLim_MCPA_2 0;
BA_ "GenSigTimeoutTime_EVCU2" SG_ 214 TqGrdtLim_MCPA_2 0;
BA_ "GenSigTimeoutTime_ECM" SG_ 214 TqGrdtLim_MCPA_2 0;
BA_ "GenSigTimeoutTime_BPCM" SG_ 214 TqGrdtLim_MCPA_2 0;
BA_ "GenSigTimeoutTime_AGSM" SG_ 214 TqGrdtLim_MCPA_2 0;
BA_ "GenSigTimeoutTime_SGW" SG_ 214 TqGrdtLim_MCPB_2 0;
BA_ "GenSigTimeoutTime_PBWM" SG_ 214 TqGrdtLim_MCPB_2 0;
BA_ "GenSigTimeoutTime_IDCM" SG_ 214 TqGrdtLim_MCPB_2 0;
BA_ "GenSigTimeoutTime_EVCU2" SG_ 214 TqGrdtLim_MCPB_2 0;
BA_ "GenSigTimeoutTime_ECM" SG_ 214 TqGrdtLim_MCPB_2 0;
BA_ "GenSigTimeoutTime_BPCM" SG_ 214 TqGrdtLim_MCPB_2 0;
BA_ "GenSigTimeoutTime_AGSM" SG_ 214 TqGrdtLim_MCPB_2 0;
BA_ "GenSigTimeoutTime_SGW" SG_ 214 UDCMax_Unlim_MCPA_2 0;
BA_ "GenSigTimeoutTime_PBWM" SG_ 214 UDCMax_Unlim_MCPA_2 0;
BA_ "GenSigTimeoutTime_IDCM" SG_ 214 UDCMax_Unlim_MCPA_2 0;
BA_ "GenSigTimeoutTime_EVCU2" SG_ 214 UDCMax_Unlim_MCPA_2 0;
BA_ "GenSigTimeoutTime_ECM" SG_ 214 UDCMax_Unlim_MCPA_2 0;
BA_ "GenSigTimeoutTime_BPCM" SG_ 214 UDCMax_Unlim_MCPA_2 0;
BA_ "GenSigTimeoutTime_AGSM" SG_ 214 UDCMax_Unlim_MCPA_2 0;
BA_ "GenSigTimeoutTime_SGW" SG_ 214 UDCMax_Unlim_MCPB_2 0;
BA_ "GenSigTimeoutTime_PBWM" SG_ 214 UDCMax_Unlim_MCPB_2 0;
BA_ "GenSigTimeoutTime_IDCM" SG_ 214 UDCMax_Unlim_MCPB_2 0;
BA_ "GenSigTimeoutTime_EVCU2" SG_ 214 UDCMax_Unlim_MCPB_2 0;
BA_ "GenSigTimeoutTime_ECM" SG_ 214 UDCMax_Unlim_MCPB_2 0;
BA_ "GenSigTimeoutTime_BPCM" SG_ 214 UDCMax_Unlim_MCPB_2 0;
BA_ "GenSigTimeoutTime_AGSM" SG_ 214 UDCMax_Unlim_MCPB_2 0;
BA_ "GenSigTimeoutTime_SGW" SG_ 1072 EVSE_ChargingSystemError 0;
BA_ "GenSigTimeoutTime_SGW" SG_ 1072 EVSE_EnergizingState 0;
BA_ "GenSigTimeoutTime_PBWM" SG_ 1072 EVSE_EnergizingState 0;
BA_ "GenSigTimeoutTime_IDCM" SG_ 1072 EVSE_EnergizingState 0;
BA_ "GenSigTimeoutTime_ECM" SG_ 1072 EVSE_EnergizingState 0;
BA_ "GenSigTimeoutTime_DMPI" SG_ 1072 EVSE_EnergizingState 0;
BA_ "GenSigTimeoutTime_BPCM" SG_ 1072 EVSE_EnergizingState 0;
BA_ "GenSigTimeoutTime_AGSM" SG_ 1072 EVSE_EnergizingState 0;
BA_ "GenSigTimeoutTime_SGW" SG_ 1072 EVSE_RemainingMin 0;
BA_ "GenSigTimeoutTime_PBWM" SG_ 1072 EVSE_RemainingMin 0;
BA_ "GenSigTimeoutTime_IDCM" SG_ 1072 EVSE_RemainingMin 0;
BA_ "GenSigTimeoutTime_ECM" SG_ 1072 EVSE_RemainingMin 0;
BA_ "GenSigTimeoutTime_DMPI" SG_ 1072 EVSE_RemainingMin 0;
BA_ "GenSigTimeoutTime_BPCM" SG_ 1072 EVSE_RemainingMin 0;
BA_ "GenSigTimeoutTime_AGSM" SG_ 1072 EVSE_RemainingMin 0;
BA_ "GenSigTimeoutTime_SGW" SG_ 1072 EVSE_RemainingSec 0;
BA_ "GenSigTimeoutTime_PBWM" SG_ 1072 EVSE_RemainingSec 0;
BA_ "GenSigTimeoutTime_IDCM" SG_ 1072 EVSE_RemainingSec 0;
BA_ "GenSigTimeoutTime_ECM" SG_ 1072 EVSE_RemainingSec 0;
BA_ "GenSigTimeoutTime_DMPI" SG_ 1072 EVSE_RemainingSec 0;
BA_ "GenSigTimeoutTime_BPCM" SG_ 1072 EVSE_RemainingSec 0;
BA_ "GenSigTimeoutTime_AGSM" SG_ 1072 EVSE_RemainingSec 0;
BA_ "GenSigTimeoutTime_PBWM" SG_ 1072 EVSE_ThrshldVoltage 0;
BA_ "GenSigTimeoutTime_IDCM" SG_ 1072 EVSE_ThrshldVoltage 0;
BA_ "GenSigTimeoutTime_ECM" SG_ 1072 EVSE_ThrshldVoltage 0;
BA_ "GenSigTimeoutTime_DMPI" SG_ 1072 EVSE_ThrshldVoltage 0;
BA_ "GenSigTimeoutTime_BPCM" SG_ 1072 EVSE_ThrshldVoltage 0;
BA_ "GenSigTimeoutTime_AGSM" SG_ 1072 EVSE_ThrshldVoltage 0;
BA_ "GenSigTimeoutTime_SGW" SG_ 1072 EVSE_ThrshldVoltage 0;
BA_ "GenSigTimeoutTime_SGW" SG_ 1072 CdM_Charger_connector_lock 0;
BA_ "GenSigTimeoutTime_PBWM" SG_ 1072 CdM_Charger_connector_lock 0;
BA_ "GenSigTimeoutTime_IDCM" SG_ 1072 CdM_Charger_connector_lock 0;
BA_ "GenSigTimeoutTime_ECM" SG_ 1072 CdM_Charger_connector_lock 0;
BA_ "GenSigTimeoutTime_DMPI" SG_ 1072 CdM_Charger_connector_lock 0;
BA_ "GenSigTimeoutTime_BPCM" SG_ 1072 CdM_Charger_connector_lock 0;
BA_ "GenSigTimeoutTime_AGSM" SG_ 1072 CdM_Charger_connector_lock 0;
BA_ "GenSigTimeoutTime_SGW" SG_ 1072 CdM_ExtFun_Thres_Volt 0;
BA_ "GenSigTimeoutTime_PBWM" SG_ 1072 CdM_ExtFun_Thres_Volt 0;
BA_ "GenSigTimeoutTime_IDCM" SG_ 1072 CdM_ExtFun_Thres_Volt 0;
BA_ "GenSigTimeoutTime_ECM" SG_ 1072 CdM_ExtFun_Thres_Volt 0;
BA_ "GenSigTimeoutTime_DMPI" SG_ 1072 CdM_ExtFun_Thres_Volt 0;
BA_ "GenSigTimeoutTime_BPCM" SG_ 1072 CdM_ExtFun_Thres_Volt 0;
BA_ "GenSigTimeoutTime_AGSM" SG_ 1072 CdM_ExtFun_Thres_Volt 0;
BA_ "GenSigTimeoutTime_SGW" SG_ 1072 CdM_Avail_output_current_EXT 0;
BA_ "GenSigTimeoutTime_PBWM" SG_ 1072 CdM_Avail_output_current_EXT 0;
BA_ "GenSigTimeoutTime_IDCM" SG_ 1072 CdM_Avail_output_current_EXT 0;
BA_ "GenSigTimeoutTime_ECM" SG_ 1072 CdM_Avail_output_current_EXT 0;
BA_ "GenSigTimeoutTime_DMPI" SG_ 1072 CdM_Avail_output_current_EXT 0;
BA_ "GenSigTimeoutTime_BPCM" SG_ 1072 CdM_Avail_output_current_EXT 0;
BA_ "GenSigTimeoutTime_AGSM" SG_ 1072 CdM_Avail_output_current_EXT 0;
BA_ "GenSigTimeoutTime_PBWM" SG_ 1072 EVSE_ChargingSystemError 0;
BA_ "GenSigTimeoutTime_IDCM" SG_ 1072 EVSE_ChargingSystemError 0;
BA_ "GenSigTimeoutTime_ECM" SG_ 1072 EVSE_ChargingSystemError 0;
BA_ "GenSigTimeoutTime_DMPI" SG_ 1072 EVSE_ChargingSystemError 0;
BA_ "GenSigTimeoutTime_BPCM" SG_ 1072 EVSE_ChargingSystemError 0;
BA_ "GenSigTimeoutTime_AGSM" SG_ 1072 EVSE_ChargingSystemError 0;
BA_ "GenSigTimeoutTime_SGW" SG_ 1072 EVSE_CHAdeMOProtocol 0;
BA_ "GenSigTimeoutTime_PBWM" SG_ 1072 EVSE_CHAdeMOProtocol 0;
BA_ "GenSigTimeoutTime_IDCM" SG_ 1072 EVSE_CHAdeMOProtocol 0;
BA_ "GenSigTimeoutTime_ECM" SG_ 1072 EVSE_CHAdeMOProtocol 0;
BA_ "GenSigTimeoutTime_DMPI" SG_ 1072 EVSE_CHAdeMOProtocol 0;
BA_ "GenSigTimeoutTime_BPCM" SG_ 1072 EVSE_CHAdeMOProtocol 0;
BA_ "GenSigTimeoutTime_AGSM" SG_ 1072 EVSE_CHAdeMOProtocol 0;
BA_ "GenSigTimeoutTime_SGW" SG_ 1072 EVSE_BatteryCompatibilty 0;
BA_ "GenSigTimeoutTime_PBWM" SG_ 1072 EVSE_BatteryCompatibilty 0;
BA_ "GenSigTimeoutTime_IDCM" SG_ 1072 EVSE_BatteryCompatibilty 0;
BA_ "GenSigTimeoutTime_ECM" SG_ 1072 EVSE_BatteryCompatibilty 0;
BA_ "GenSigTimeoutTime_DMPI" SG_ 1072 EVSE_BatteryCompatibilty 0;
BA_ "GenSigTimeoutTime_BPCM" SG_ 1072 EVSE_BatteryCompatibilty 0;
BA_ "GenSigTimeoutTime_AGSM" SG_ 1072 EVSE_BatteryCompatibilty 0;
BA_ "GenSigTimeoutTime_SGW" SG_ 1073 VehicleDriveSts 0;
BA_ "GenSigTimeoutTime_PBWM" SG_ 1073 VehicleDriveSts 0;
BA_ "GenSigTimeoutTime_EVCU2" SG_ 1073 VehicleDriveSts 0;
BA_ "GenSigTimeoutTime_ECM" SG_ 1073 VehicleDriveSts 0;
BA_ "GenSigTimeoutTime_DMPI" SG_ 1073 VehicleDriveSts 0;
BA_ "GenSigTimeoutTime_BPCM" SG_ 1073 VehicleDriveSts 0;
BA_ "GenSigTimeoutTime_AGSM" SG_ 1073 VehicleDriveSts 0;
BA_ "GenSigTimeoutTime_SGW" SG_ 1073 CHAdeMOProtocol 0;
BA_ "GenSigTimeoutTime_PBWM" SG_ 1073 CHAdeMOProtocol 0;
BA_ "GenSigTimeoutTime_EVCU2" SG_ 1073 CHAdeMOProtocol 0;
BA_ "GenSigTimeoutTime_ECM" SG_ 1073 CHAdeMOProtocol 0;
BA_ "GenSigTimeoutTime_DMPI" SG_ 1073 CHAdeMOProtocol 0;
BA_ "GenSigTimeoutTime_BPCM" SG_ 1073 CHAdeMOProtocol 0;
BA_ "GenSigTimeoutTime_AGSM" SG_ 1073 CHAdeMOProtocol 0;
BA_ "GenSigTimeoutTime_SGW" SG_ 1073 ChargedCurrentMin 0;
BA_ "GenSigTimeoutTime_PBWM" SG_ 1073 ChargedCurrentMin 0;
BA_ "GenSigTimeoutTime_EVCU2" SG_ 1073 ChargedCurrentMin 0;
BA_ "GenSigTimeoutTime_ECM" SG_ 1073 ChargedCurrentMin 0;
BA_ "GenSigTimeoutTime_DMPI" SG_ 1073 ChargedCurrentMin 0;
BA_ "GenSigTimeoutTime_BPCM" SG_ 1073 ChargedCurrentMin 0;
BA_ "GenSigTimeoutTime_AGSM" SG_ 1073 ChargedCurrentMin 0;
BA_ "GenSigTimeoutTime_SGW" SG_ 1073 ChargedReferenceConstant 0;
BA_ "GenSigTimeoutTime_PBWM" SG_ 1073 ChargedReferenceConstant 0;
BA_ "GenSigTimeoutTime_EVCU2" SG_ 1073 ChargedReferenceConstant 0;
BA_ "GenSigTimeoutTime_ECM" SG_ 1073 ChargedReferenceConstant 0;
BA_ "GenSigTimeoutTime_DMPI" SG_ 1073 ChargedReferenceConstant 0;
BA_ "GenSigTimeoutTime_BPCM" SG_ 1073 ChargedReferenceConstant 0;
BA_ "GenSigTimeoutTime_AGSM" SG_ 1073 ChargedReferenceConstant 0;
BA_ "GenSigTimeoutTime_SGW" SG_ 1073 DisplaySOC 0;
BA_ "GenSigTimeoutTime_PBWM" SG_ 1073 DisplaySOC 0;
BA_ "GenSigTimeoutTime_EVCU2" SG_ 1073 DisplaySOC 0;
BA_ "GenSigTimeoutTime_ECM" SG_ 1073 DisplaySOC 0;
BA_ "GenSigTimeoutTime_DMPI" SG_ 1073 DisplaySOC 0;
BA_ "GenSigTimeoutTime_BPCM" SG_ 1073 DisplaySOC 0;
BA_ "GenSigTimeoutTime_AGSM" SG_ 1073 DisplaySOC 0;
BA_ "GenSigTimeoutTime_SGW" SG_ 1073 EVContactorSts 0;
BA_ "GenSigTimeoutTime_PBWM" SG_ 1073 EVContactorSts 0;
BA_ "GenSigTimeoutTime_EVCU2" SG_ 1073 EVContactorSts 0;
BA_ "GenSigTimeoutTime_ECM" SG_ 1073 EVContactorSts 0;
BA_ "GenSigTimeoutTime_DMPI" SG_ 1073 EVContactorSts 0;
BA_ "GenSigTimeoutTime_BPCM" SG_ 1073 EVContactorSts 0;
BA_ "GenSigTimeoutTime_AGSM" SG_ 1073 EVContactorSts 0;
BA_ "GenSigTimeoutTime_SGW" SG_ 1073 MinBatteryPackVoltage 0;
BA_ "GenSigTimeoutTime_PBWM" SG_ 1073 MinBatteryPackVoltage 0;
BA_ "GenSigTimeoutTime_EVCU2" SG_ 1073 MinBatteryPackVoltage 0;
BA_ "GenSigTimeoutTime_ECM" SG_ 1073 MinBatteryPackVoltage 0;
BA_ "GenSigTimeoutTime_DMPI" SG_ 1073 MinBatteryPackVoltage 0;
BA_ "GenSigTimeoutTime_BPCM" SG_ 1073 MinBatteryPackVoltage 0;
BA_ "GenSigTimeoutTime_AGSM" SG_ 1073 MinBatteryPackVoltage 0;
BA_ "GenSigTimeoutTime_SGW" SG_ 1073 StopReqBeforeCharge 0;
BA_ "GenSigTimeoutTime_PBWM" SG_ 1073 StopReqBeforeCharge 0;
BA_ "GenSigTimeoutTime_EVCU2" SG_ 1073 StopReqBeforeCharge 0;
BA_ "GenSigTimeoutTime_ECM" SG_ 1073 StopReqBeforeCharge 0;
BA_ "GenSigTimeoutTime_DMPI" SG_ 1073 StopReqBeforeCharge 0;
BA_ "GenSigTimeoutTime_BPCM" SG_ 1073 StopReqBeforeCharge 0;
BA_ "GenSigTimeoutTime_AGSM" SG_ 1073 StopReqBeforeCharge 0;
BA_ "GenSigTimeoutTime_SGW" SG_ 1073 TotalBatteryCapacity 0;
BA_ "GenSigTimeoutTime_PBWM" SG_ 1073 TotalBatteryCapacity 0;
BA_ "GenSigTimeoutTime_EVCU2" SG_ 1073 TotalBatteryCapacity 0;
BA_ "GenSigTimeoutTime_ECM" SG_ 1073 TotalBatteryCapacity 0;
BA_ "GenSigTimeoutTime_DMPI" SG_ 1073 TotalBatteryCapacity 0;
BA_ "GenSigTimeoutTime_BPCM" SG_ 1073 TotalBatteryCapacity 0;
BA_ "GenSigTimeoutTime_AGSM" SG_ 1073 TotalBatteryCapacity 0;
BA_ "GenSigTimeoutTime_SGW" SG_ 1073 BattVoltDeviationErr 0;
BA_ "GenSigTimeoutTime_PBWM" SG_ 1073 BattVoltDeviationErr 0;
BA_ "GenSigTimeoutTime_EVCU2" SG_ 1073 BattVoltDeviationErr 0;
BA_ "GenSigTimeoutTime_ECM" SG_ 1073 BattVoltDeviationErr 0;
BA_ "GenSigTimeoutTime_DMPI" SG_ 1073 BattVoltDeviationErr 0;
BA_ "GenSigTimeoutTime_BPCM" SG_ 1073 BattVoltDeviationErr 0;
BA_ "GenSigTimeoutTime_AGSM" SG_ 1073 BattVoltDeviationErr 0;
BA_ "GenSigTimeoutTime_SGW" SG_ 1073 CdM_ExtFun_Veh_HC_Control_Comp 0;
BA_ "GenSigTimeoutTime_PBWM" SG_ 1073 CdM_ExtFun_Veh_HC_Control_Comp 0;
BA_ "GenSigTimeoutTime_EVCU2" SG_ 1073 CdM_ExtFun_Veh_HC_Control_Comp 0;
BA_ "GenSigTimeoutTime_ECM" SG_ 1073 CdM_ExtFun_Veh_HC_Control_Comp 0;
BA_ "GenSigTimeoutTime_DMPI" SG_ 1073 CdM_ExtFun_Veh_HC_Control_Comp 0;
BA_ "GenSigTimeoutTime_BPCM" SG_ 1073 CdM_ExtFun_Veh_HC_Control_Comp 0;
BA_ "GenSigTimeoutTime_AGSM" SG_ 1073 CdM_ExtFun_Veh_HC_Control_Comp 0;
BA_ "GenSigTimeoutTime_SGW" SG_ 1073 CdM_ExtFun_Min_Batt_Volt 0;
BA_ "GenSigTimeoutTime_PBWM" SG_ 1073 CdM_ExtFun_Min_Batt_Volt 0;
BA_ "GenSigTimeoutTime_EVCU2" SG_ 1073 CdM_ExtFun_Min_Batt_Volt 0;
BA_ "GenSigTimeoutTime_ECM" SG_ 1073 CdM_ExtFun_Min_Batt_Volt 0;
BA_ "GenSigTimeoutTime_DMPI" SG_ 1073 CdM_ExtFun_Min_Batt_Volt 0;
BA_ "GenSigTimeoutTime_BPCM" SG_ 1073 CdM_ExtFun_Min_Batt_Volt 0;
BA_ "GenSigTimeoutTime_AGSM" SG_ 1073 CdM_ExtFun_Min_Batt_Volt 0;
BA_ "GenSigTimeoutTime_SGW" SG_ 1073 CdM_ExtFun_Veh_Dyn_Control_Comp 0;
BA_ "GenSigTimeoutTime_PBWM" SG_ 1073 CdM_ExtFun_Veh_Dyn_Control_Comp 0;
BA_ "GenSigTimeoutTime_EVCU2" SG_ 1073 CdM_ExtFun_Veh_Dyn_Control_Comp 0;
BA_ "GenSigTimeoutTime_ECM" SG_ 1073 CdM_ExtFun_Veh_Dyn_Control_Comp 0;
BA_ "GenSigTimeoutTime_DMPI" SG_ 1073 CdM_ExtFun_Veh_Dyn_Control_Comp 0;
BA_ "GenSigTimeoutTime_BPCM" SG_ 1073 CdM_ExtFun_Veh_Dyn_Control_Comp 0;
BA_ "GenSigTimeoutTime_AGSM" SG_ 1073 CdM_ExtFun_Veh_Dyn_Control_Comp 0;
BA_ "GenSigTimeoutTime_SGW" SG_ 1073 CdM_Chrg_current_req_ext 0;
BA_ "GenSigTimeoutTime_PBWM" SG_ 1073 CdM_Chrg_current_req_ext 0;
BA_ "GenSigTimeoutTime_EVCU2" SG_ 1073 CdM_Chrg_current_req_ext 0;
BA_ "GenSigTimeoutTime_ECM" SG_ 1073 CdM_Chrg_current_req_ext 0;
BA_ "GenSigTimeoutTime_DMPI" SG_ 1073 CdM_Chrg_current_req_ext 0;
BA_ "GenSigTimeoutTime_BPCM" SG_ 1073 CdM_Chrg_current_req_ext 0;
BA_ "GenSigTimeoutTime_AGSM" SG_ 1073 CdM_Chrg_current_req_ext 0;
BA_ "GenSigTimeoutTime_SGW" SG_ 1073 EVCU_CP3Cmd 0;
BA_ "GenSigTimeoutTime_PBWM" SG_ 1073 EVCU_CP3Cmd 0;
BA_ "GenSigTimeoutTime_EVCU2" SG_ 1073 EVCU_CP3Cmd 0;
BA_ "GenSigTimeoutTime_ECM" SG_ 1073 EVCU_CP3Cmd 0;
BA_ "GenSigTimeoutTime_DMPI" SG_ 1073 EVCU_CP3Cmd 0;
BA_ "GenSigTimeoutTime_BPCM" SG_ 1073 EVCU_CP3Cmd 0;
BA_ "GenSigTimeoutTime_AGSM" SG_ 1073 EVCU_CP3Cmd 0;
BA_ "GenSigTimeoutTime_SGW" SG_ 1073 CdM_Remained_batt_capacity 0;
BA_ "GenSigTimeoutTime_PBWM" SG_ 1073 CdM_Remained_batt_capacity 0;
BA_ "GenSigTimeoutTime_EVCU2" SG_ 1073 CdM_Remained_batt_capacity 0;
BA_ "GenSigTimeoutTime_ECM" SG_ 1073 CdM_Remained_batt_capacity 0;
BA_ "GenSigTimeoutTime_DMPI" SG_ 1073 CdM_Remained_batt_capacity 0;
BA_ "GenSigTimeoutTime_BPCM" SG_ 1073 CdM_Remained_batt_capacity 0;
BA_ "GenSigTimeoutTime_AGSM" SG_ 1073 CdM_Remained_batt_capacity 0;
BA_ "GenSigTimeoutTime_SGW" SG_ 126 N_PDU 0;
BA_ "GenSigTimeoutTime_PBWM" SG_ 126 N_PDU 0;
BA_ "GenSigTimeoutTime_IDCM" SG_ 126 N_PDU 0;
BA_ "GenSigTimeoutTime_ECM" SG_ 126 N_PDU 0;
BA_ "GenSigTimeoutTime_DMPI" SG_ 126 N_PDU 0;
BA_ "GenSigTimeoutTime_BPCM" SG_ 126 N_PDU 0;
BA_ "GenSigTimeoutTime_AGSM" SG_ 126 N_PDU 0;
BA_ "GenSigTimeoutTime_PBWM" SG_ 123 N_PDU 0;
BA_ "GenSigTimeoutTime_IDCM" SG_ 123 N_PDU 0;
BA_ "GenSigTimeoutTime_EVCU2" SG_ 123 N_PDU 0;
BA_ "GenSigTimeoutTime_ECM" SG_ 123 N_PDU 0;
BA_ "GenSigTimeoutTime_DMPI" SG_ 123 N_PDU 0;
BA_ "GenSigTimeoutTime_BPCM" SG_ 123 N_PDU 0;
BA_ "GenSigTimeoutTime_AGSM" SG_ 123 N_PDU 0;
BA_ "GenSigTimeoutTime_SGW" SG_ 127 N_PDU 0;
BA_ "GenSigTimeoutTime_PBWM" SG_ 127 N_PDU 0;
BA_ "GenSigTimeoutTime_IDCM" SG_ 127 N_PDU 0;
BA_ "GenSigTimeoutTime_ECM" SG_ 127 N_PDU 0;
BA_ "GenSigTimeoutTime_DMPI" SG_ 127 N_PDU 0;
BA_ "GenSigTimeoutTime_BPCM" SG_ 127 N_PDU 0;
BA_ "GenSigTimeoutTime_AGSM" SG_ 127 N_PDU 0;
BA_ "GenSigTimeoutTime_PBWM" SG_ 124 N_PDU 0;
BA_ "GenSigTimeoutTime_IDCM" SG_ 124 N_PDU 0;
BA_ "GenSigTimeoutTime_EVCU2" SG_ 124 N_PDU 0;
BA_ "GenSigTimeoutTime_ECM" SG_ 124 N_PDU 0;
BA_ "GenSigTimeoutTime_DMPI" SG_ 124 N_PDU 0;
BA_ "GenSigTimeoutTime_BPCM" SG_ 124 N_PDU 0;
BA_ "GenSigTimeoutTime_AGSM" SG_ 124 N_PDU 0;
BA_ "GenSigTimeoutTime_SGW" SG_ 2564476146 N_PDU 0;
BA_ "GenSigTimeoutTime_PBWM" SG_ 2564476146 N_PDU 0;
BA_ "GenSigTimeoutTime_IDCM" SG_ 2564476146 N_PDU 0;
BA_ "GenSigTimeoutTime_EVCU2" SG_ 2564476146 N_PDU 0;
BA_ "GenSigTimeoutTime_ECM" SG_ 2564476146 N_PDU 0;
BA_ "GenSigTimeoutTime_DMPI" SG_ 2564476146 N_PDU 0;
BA_ "GenSigTimeoutTime_BPCM" SG_ 2564476146 N_PDU 0;
BA_ "GenSigTimeoutTime_AGSM" SG_ 2564476146 N_PDU 0;
BA_ "GenSigTimeoutTime_SGW" SG_ 2564441073 N_PDU 0;
BA_ "GenSigTimeoutTime_PBWM" SG_ 2564441073 N_PDU 0;
BA_ "GenSigTimeoutTime_IDCM" SG_ 2564441073 N_PDU 0;
BA_ "GenSigTimeoutTime_EVCU2" SG_ 2564441073 N_PDU 0;
BA_ "GenSigTimeoutTime_ECM" SG_ 2564441073 N_PDU 0;
BA_ "GenSigTimeoutTime_DMPI" SG_ 2564441073 N_PDU 0;
BA_ "GenSigTimeoutTime_BPCM" SG_ 2564441073 N_PDU 0;
BA_ "GenSigTimeoutTime_AGSM" SG_ 2564441073 N_PDU 0;
BA_ "GenSigTimeoutTime_SGW" SG_ 2564441074 N_PDU 0;
BA_ "GenSigTimeoutTime_PBWM" SG_ 2564441074 N_PDU 0;
BA_ "GenSigTimeoutTime_IDCM" SG_ 2564441074 N_PDU 0;
BA_ "GenSigTimeoutTime_EVCU2" SG_ 2564441074 N_PDU 0;
BA_ "GenSigTimeoutTime_ECM" SG_ 2564441074 N_PDU 0;
BA_ "GenSigTimeoutTime_DMPI" SG_ 2564441074 N_PDU 0;
BA_ "GenSigTimeoutTime_BPCM" SG_ 2564441074 N_PDU 0;
BA_ "GenSigTimeoutTime_AGSM" SG_ 2564441074 N_PDU 0;
BA_ "GenSigTimeoutTime_SGW" SG_ 2564476145 N_PDU 0;
BA_ "GenSigTimeoutTime_PBWM" SG_ 2564476145 N_PDU 0;
BA_ "GenSigTimeoutTime_IDCM" SG_ 2564476145 N_PDU 0;
BA_ "GenSigTimeoutTime_EVCU2" SG_ 2564476145 N_PDU 0;
BA_ "GenSigTimeoutTime_ECM" SG_ 2564476145 N_PDU 0;
BA_ "GenSigTimeoutTime_DMPI" SG_ 2564476145 N_PDU 0;
BA_ "GenSigTimeoutTime_BPCM" SG_ 2564476145 N_PDU 0;
BA_ "GenSigTimeoutTime_AGSM" SG_ 2564476145 N_PDU 0;
BA_ "GenSigTimeoutTime_SGW" SG_ 2564485443 N_PDU 0;
BA_ "GenSigTimeoutTime_PBWM" SG_ 2564485443 N_PDU 0;
BA_ "GenSigTimeoutTime_IDCM" SG_ 2564485443 N_PDU 0;
BA_ "GenSigTimeoutTime_EVCU2" SG_ 2564485443 N_PDU 0;
BA_ "GenSigTimeoutTime_ECM" SG_ 2564485443 N_PDU 0;
BA_ "GenSigTimeoutTime_DMPI" SG_ 2564485443 N_PDU 0;
BA_ "GenSigTimeoutTime_BPCM" SG_ 2564485443 N_PDU 0;
BA_ "GenSigTimeoutTime_AGSM" SG_ 2564485443 N_PDU 0;
BA_ "GenSigTimeoutTime_SGW" SG_ 2564485699 N_PDU 0;
BA_ "GenSigTimeoutTime_PBWM" SG_ 2564485699 N_PDU 0;
BA_ "GenSigTimeoutTime_IDCM" SG_ 2564485699 N_PDU 0;
BA_ "GenSigTimeoutTime_EVCU2" SG_ 2564485699 N_PDU 0;
BA_ "GenSigTimeoutTime_ECM" SG_ 2564485699 N_PDU 0;
BA_ "GenSigTimeoutTime_DMPI" SG_ 2564485699 N_PDU 0;
BA_ "GenSigTimeoutTime_BPCM" SG_ 2564485699 N_PDU 0;
BA_ "GenSigTimeoutTime_AGSM" SG_ 2564485699 N_PDU 0;
BA_ "GenSigTimeoutTime_SGW" SG_ 2651930684 Digit_11_PBWM 0;
BA_ "GenSigTimeoutTime_PBWM" SG_ 2651930684 Digit_11_PBWM 0;
BA_ "GenSigTimeoutTime_IDCM" SG_ 2651930684 Digit_11_PBWM 0;
BA_ "GenSigTimeoutTime_ECM" SG_ 2651930684 Digit_11_PBWM 0;
BA_ "GenSigTimeoutTime_DMPI" SG_ 2651930684 Digit_11_PBWM 0;
BA_ "GenSigTimeoutTime_BPCM" SG_ 2651930684 Digit_11_PBWM 0;
BA_ "GenSigTimeoutTime_AGSM" SG_ 2651930684 Digit_11_PBWM 0;
BA_ "GenSigTimeoutTime_SGW" SG_ 2651930684 Digit_09_PBWM 0;
BA_ "GenSigTimeoutTime_PBWM" SG_ 2651930684 Digit_09_PBWM 0;
BA_ "GenSigTimeoutTime_IDCM" SG_ 2651930684 Digit_09_PBWM 0;
BA_ "GenSigTimeoutTime_ECM" SG_ 2651930684 Digit_09_PBWM 0;
BA_ "GenSigTimeoutTime_DMPI" SG_ 2651930684 Digit_09_PBWM 0;
BA_ "GenSigTimeoutTime_BPCM" SG_ 2651930684 Digit_09_PBWM 0;
BA_ "GenSigTimeoutTime_AGSM" SG_ 2651930684 Digit_09_PBWM 0;
BA_ "GenSigTimeoutTime_SGW" SG_ 2651930684 Digit_10_PBWM 0;
BA_ "GenSigTimeoutTime_PBWM" SG_ 2651930684 Digit_10_PBWM 0;
BA_ "GenSigTimeoutTime_IDCM" SG_ 2651930684 Digit_10_PBWM 0;
BA_ "GenSigTimeoutTime_ECM" SG_ 2651930684 Digit_10_PBWM 0;
BA_ "GenSigTimeoutTime_DMPI" SG_ 2651930684 Digit_10_PBWM 0;
BA_ "GenSigTimeoutTime_BPCM" SG_ 2651930684 Digit_10_PBWM 0;
BA_ "GenSigTimeoutTime_AGSM" SG_ 2651930684 Digit_10_PBWM 0;
BA_ "GenSigTimeoutTime_SGW" SG_ 2651930684 Digit_08_PBWM 0;
BA_ "GenSigTimeoutTime_PBWM" SG_ 2651930684 Digit_08_PBWM 0;
BA_ "GenSigTimeoutTime_IDCM" SG_ 2651930684 Digit_08_PBWM 0;
BA_ "GenSigTimeoutTime_ECM" SG_ 2651930684 Digit_08_PBWM 0;
BA_ "GenSigTimeoutTime_DMPI" SG_ 2651930684 Digit_08_PBWM 0;
BA_ "GenSigTimeoutTime_BPCM" SG_ 2651930684 Digit_08_PBWM 0;
BA_ "GenSigTimeoutTime_AGSM" SG_ 2651930684 Digit_08_PBWM 0;
BA_ "GenSigTimeoutTime_SGW" SG_ 2651930684 Digit_07_PBWM 0;
BA_ "GenSigTimeoutTime_PBWM" SG_ 2651930684 Digit_07_PBWM 0;
BA_ "GenSigTimeoutTime_IDCM" SG_ 2651930684 Digit_07_PBWM 0;
BA_ "GenSigTimeoutTime_ECM" SG_ 2651930684 Digit_07_PBWM 0;
BA_ "GenSigTimeoutTime_DMPI" SG_ 2651930684 Digit_07_PBWM 0;
BA_ "GenSigTimeoutTime_BPCM" SG_ 2651930684 Digit_07_PBWM 0;
BA_ "GenSigTimeoutTime_AGSM" SG_ 2651930684 Digit_07_PBWM 0;
BA_ "GenSigTimeoutTime_SGW" SG_ 2651930684 Digit_05_PBWM 0;
BA_ "GenSigTimeoutTime_PBWM" SG_ 2651930684 Digit_05_PBWM 0;
BA_ "GenSigTimeoutTime_IDCM" SG_ 2651930684 Digit_05_PBWM 0;
BA_ "GenSigTimeoutTime_ECM" SG_ 2651930684 Digit_05_PBWM 0;
BA_ "GenSigTimeoutTime_DMPI" SG_ 2651930684 Digit_05_PBWM 0;
BA_ "GenSigTimeoutTime_BPCM" SG_ 2651930684 Digit_05_PBWM 0;
BA_ "GenSigTimeoutTime_AGSM" SG_ 2651930684 Digit_05_PBWM 0;
BA_ "GenSigTimeoutTime_SGW" SG_ 2651930684 Digit_06_PBWM 0;
BA_ "GenSigTimeoutTime_PBWM" SG_ 2651930684 Digit_06_PBWM 0;
BA_ "GenSigTimeoutTime_IDCM" SG_ 2651930684 Digit_06_PBWM 0;
BA_ "GenSigTimeoutTime_ECM" SG_ 2651930684 Digit_06_PBWM 0;
BA_ "GenSigTimeoutTime_DMPI" SG_ 2651930684 Digit_06_PBWM 0;
BA_ "GenSigTimeoutTime_BPCM" SG_ 2651930684 Digit_06_PBWM 0;
BA_ "GenSigTimeoutTime_AGSM" SG_ 2651930684 Digit_06_PBWM 0;
BA_ "GenSigTimeoutTime_SGW" SG_ 2651930690 Digit_08_DMPI 0;
BA_ "GenSigTimeoutTime_PBWM" SG_ 2651930690 Digit_08_DMPI 0;
BA_ "GenSigTimeoutTime_IDCM" SG_ 2651930690 Digit_08_DMPI 0;
BA_ "GenSigTimeoutTime_ECM" SG_ 2651930690 Digit_08_DMPI 0;
BA_ "GenSigTimeoutTime_DMPI" SG_ 2651930690 Digit_08_DMPI 0;
BA_ "GenSigTimeoutTime_BPCM" SG_ 2651930690 Digit_08_DMPI 0;
BA_ "GenSigTimeoutTime_AGSM" SG_ 2651930690 Digit_08_DMPI 0;
BA_ "GenSigTimeoutTime_SGW" SG_ 2651930690 Digit_09_DMPI 0;
BA_ "GenSigTimeoutTime_PBWM" SG_ 2651930690 Digit_09_DMPI 0;
BA_ "GenSigTimeoutTime_IDCM" SG_ 2651930690 Digit_09_DMPI 0;
BA_ "GenSigTimeoutTime_ECM" SG_ 2651930690 Digit_09_DMPI 0;
BA_ "GenSigTimeoutTime_DMPI" SG_ 2651930690 Digit_09_DMPI 0;
BA_ "GenSigTimeoutTime_BPCM" SG_ 2651930690 Digit_09_DMPI 0;
BA_ "GenSigTimeoutTime_AGSM" SG_ 2651930690 Digit_09_DMPI 0;
BA_ "GenSigTimeoutTime_SGW" SG_ 2651930690 Digit_10_DMPI 0;
BA_ "GenSigTimeoutTime_PBWM" SG_ 2651930690 Digit_10_DMPI 0;
BA_ "GenSigTimeoutTime_IDCM" SG_ 2651930690 Digit_10_DMPI 0;
BA_ "GenSigTimeoutTime_ECM" SG_ 2651930690 Digit_10_DMPI 0;
BA_ "GenSigTimeoutTime_DMPI" SG_ 2651930690 Digit_10_DMPI 0;
BA_ "GenSigTimeoutTime_BPCM" SG_ 2651930690 Digit_10_DMPI 0;
BA_ "GenSigTimeoutTime_AGSM" SG_ 2651930690 Digit_10_DMPI 0;
BA_ "GenSigTimeoutTime_SGW" SG_ 2651930690 Digit_11_DMPI 0;
BA_ "GenSigTimeoutTime_PBWM" SG_ 2651930690 Digit_11_DMPI 0;
BA_ "GenSigTimeoutTime_IDCM" SG_ 2651930690 Digit_11_DMPI 0;
BA_ "GenSigTimeoutTime_ECM" SG_ 2651930690 Digit_11_DMPI 0;
BA_ "GenSigTimeoutTime_DMPI" SG_ 2651930690 Digit_11_DMPI 0;
BA_ "GenSigTimeoutTime_BPCM" SG_ 2651930690 Digit_11_DMPI 0;
BA_ "GenSigTimeoutTime_AGSM" SG_ 2651930690 Digit_11_DMPI 0;
BA_ "GenSigTimeoutTime_SGW" SG_ 2651930684 Digit_01_PBWM 0;
BA_ "GenSigTimeoutTime_PBWM" SG_ 2651930684 Digit_01_PBWM 0;
BA_ "GenSigTimeoutTime_IDCM" SG_ 2651930684 Digit_01_PBWM 0;
BA_ "GenSigTimeoutTime_ECM" SG_ 2651930684 Digit_01_PBWM 0;
BA_ "GenSigTimeoutTime_DMPI" SG_ 2651930684 Digit_01_PBWM 0;
BA_ "GenSigTimeoutTime_BPCM" SG_ 2651930684 Digit_01_PBWM 0;
BA_ "GenSigTimeoutTime_AGSM" SG_ 2651930684 Digit_01_PBWM 0;
BA_ "GenSigSendType" SG_ 2651930684 Digit_01_PBWM 1;
BA_ "GenSigTimeoutTime_SGW" SG_ 2651930684 Digit_02_PBWM 0;
BA_ "GenSigTimeoutTime_PBWM" SG_ 2651930684 Digit_02_PBWM 0;
BA_ "GenSigTimeoutTime_IDCM" SG_ 2651930684 Digit_02_PBWM 0;
BA_ "GenSigTimeoutTime_ECM" SG_ 2651930684 Digit_02_PBWM 0;
BA_ "GenSigTimeoutTime_DMPI" SG_ 2651930684 Digit_02_PBWM 0;
BA_ "GenSigTimeoutTime_BPCM" SG_ 2651930684 Digit_02_PBWM 0;
BA_ "GenSigTimeoutTime_AGSM" SG_ 2651930684 Digit_02_PBWM 0;
BA_ "GenSigTimeoutTime_SGW" SG_ 2651930684 Digit_03_PBWM 0;
BA_ "GenSigTimeoutTime_PBWM" SG_ 2651930684 Digit_03_PBWM 0;
BA_ "GenSigTimeoutTime_IDCM" SG_ 2651930684 Digit_03_PBWM 0;
BA_ "GenSigTimeoutTime_ECM" SG_ 2651930684 Digit_03_PBWM 0;
BA_ "GenSigTimeoutTime_DMPI" SG_ 2651930684 Digit_03_PBWM 0;
BA_ "GenSigTimeoutTime_BPCM" SG_ 2651930684 Digit_03_PBWM 0;
BA_ "GenSigTimeoutTime_AGSM" SG_ 2651930684 Digit_03_PBWM 0;
BA_ "GenSigTimeoutTime_SGW" SG_ 2651930684 Digit_04_PBWM 0;
BA_ "GenSigTimeoutTime_PBWM" SG_ 2651930684 Digit_04_PBWM 0;
BA_ "GenSigTimeoutTime_IDCM" SG_ 2651930684 Digit_04_PBWM 0;
BA_ "GenSigTimeoutTime_ECM" SG_ 2651930684 Digit_04_PBWM 0;
BA_ "GenSigTimeoutTime_DMPI" SG_ 2651930684 Digit_04_PBWM 0;
BA_ "GenSigTimeoutTime_BPCM" SG_ 2651930684 Digit_04_PBWM 0;
BA_ "GenSigTimeoutTime_AGSM" SG_ 2651930684 Digit_04_PBWM 0;
BA_ "GenSigTimeoutTime_SGW" SG_ 2651930690 Digit_01_DMPI 0;
BA_ "GenSigTimeoutTime_PBWM" SG_ 2651930690 Digit_01_DMPI 0;
BA_ "GenSigTimeoutTime_IDCM" SG_ 2651930690 Digit_01_DMPI 0;
BA_ "GenSigTimeoutTime_ECM" SG_ 2651930690 Digit_01_DMPI 0;
BA_ "GenSigTimeoutTime_DMPI" SG_ 2651930690 Digit_01_DMPI 0;
BA_ "GenSigTimeoutTime_BPCM" SG_ 2651930690 Digit_01_DMPI 0;
BA_ "GenSigTimeoutTime_AGSM" SG_ 2651930690 Digit_01_DMPI 0;
BA_ "GenSigSendType" SG_ 2651930690 Digit_01_DMPI 1;
BA_ "GenSigTimeoutTime_SGW" SG_ 2651930690 Digit_02_DMPI 0;
BA_ "GenSigTimeoutTime_PBWM" SG_ 2651930690 Digit_02_DMPI 0;
BA_ "GenSigTimeoutTime_IDCM" SG_ 2651930690 Digit_02_DMPI 0;
BA_ "GenSigTimeoutTime_ECM" SG_ 2651930690 Digit_02_DMPI 0;
BA_ "GenSigTimeoutTime_DMPI" SG_ 2651930690 Digit_02_DMPI 0;
BA_ "GenSigTimeoutTime_BPCM" SG_ 2651930690 Digit_02_DMPI 0;
BA_ "GenSigTimeoutTime_AGSM" SG_ 2651930690 Digit_02_DMPI 0;
BA_ "GenSigTimeoutTime_SGW" SG_ 2651930690 Digit_03_DMPI 0;
BA_ "GenSigTimeoutTime_PBWM" SG_ 2651930690 Digit_03_DMPI 0;
BA_ "GenSigTimeoutTime_IDCM" SG_ 2651930690 Digit_03_DMPI 0;
BA_ "GenSigTimeoutTime_ECM" SG_ 2651930690 Digit_03_DMPI 0;
BA_ "GenSigTimeoutTime_DMPI" SG_ 2651930690 Digit_03_DMPI 0;
BA_ "GenSigTimeoutTime_BPCM" SG_ 2651930690 Digit_03_DMPI 0;
BA_ "GenSigTimeoutTime_AGSM" SG_ 2651930690 Digit_03_DMPI 0;
BA_ "GenSigTimeoutTime_SGW" SG_ 2651930690 Digit_04_DMPI 0;
BA_ "GenSigTimeoutTime_PBWM" SG_ 2651930690 Digit_04_DMPI 0;
BA_ "GenSigTimeoutTime_IDCM" SG_ 2651930690 Digit_04_DMPI 0;
BA_ "GenSigTimeoutTime_ECM" SG_ 2651930690 Digit_04_DMPI 0;
BA_ "GenSigTimeoutTime_DMPI" SG_ 2651930690 Digit_04_DMPI 0;
BA_ "GenSigTimeoutTime_BPCM" SG_ 2651930690 Digit_04_DMPI 0;
BA_ "GenSigTimeoutTime_AGSM" SG_ 2651930690 Digit_04_DMPI 0;
BA_ "GenSigTimeoutTime_SGW" SG_ 2651930690 Digit_05_DMPI 0;
BA_ "GenSigTimeoutTime_PBWM" SG_ 2651930690 Digit_05_DMPI 0;
BA_ "GenSigTimeoutTime_IDCM" SG_ 2651930690 Digit_05_DMPI 0;
BA_ "GenSigTimeoutTime_ECM" SG_ 2651930690 Digit_05_DMPI 0;
BA_ "GenSigTimeoutTime_DMPI" SG_ 2651930690 Digit_05_DMPI 0;
BA_ "GenSigTimeoutTime_BPCM" SG_ 2651930690 Digit_05_DMPI 0;
BA_ "GenSigTimeoutTime_AGSM" SG_ 2651930690 Digit_05_DMPI 0;
BA_ "GenSigTimeoutTime_SGW" SG_ 2651930690 Digit_06_DMPI 0;
BA_ "GenSigTimeoutTime_PBWM" SG_ 2651930690 Digit_06_DMPI 0;
BA_ "GenSigTimeoutTime_IDCM" SG_ 2651930690 Digit_06_DMPI 0;
BA_ "GenSigTimeoutTime_ECM" SG_ 2651930690 Digit_06_DMPI 0;
BA_ "GenSigTimeoutTime_DMPI" SG_ 2651930690 Digit_06_DMPI 0;
BA_ "GenSigTimeoutTime_BPCM" SG_ 2651930690 Digit_06_DMPI 0;
BA_ "GenSigTimeoutTime_AGSM" SG_ 2651930690 Digit_06_DMPI 0;
BA_ "GenSigTimeoutTime_SGW" SG_ 2651930690 Digit_07_DMPI 0;
BA_ "GenSigTimeoutTime_PBWM" SG_ 2651930690 Digit_07_DMPI 0;
BA_ "GenSigTimeoutTime_IDCM" SG_ 2651930690 Digit_07_DMPI 0;
BA_ "GenSigTimeoutTime_ECM" SG_ 2651930690 Digit_07_DMPI 0;
BA_ "GenSigTimeoutTime_DMPI" SG_ 2651930690 Digit_07_DMPI 0;
BA_ "GenSigTimeoutTime_BPCM" SG_ 2651930690 Digit_07_DMPI 0;
BA_ "GenSigTimeoutTime_AGSM" SG_ 2651930690 Digit_07_DMPI 0;
BA_ "GenSigTimeoutTime_SGW" SG_ 212 PIM_B_Torque_Achieved_V 0;
BA_ "GenSigTimeoutTime_PBWM" SG_ 212 PIM_B_Torque_Achieved_V 0;
BA_ "GenSigTimeoutTime_IDCM" SG_ 212 PIM_B_Torque_Achieved_V 0;
BA_ "GenSigTimeoutTime_ECM" SG_ 212 PIM_B_Torque_Achieved_V 0;
BA_ "GenSigTimeoutTime_DMPI" SG_ 212 PIM_B_Torque_Achieved_V 0;
BA_ "GenSigTimeoutTime_BPCM" SG_ 212 PIM_B_Torque_Achieved_V 0;
BA_ "GenSigTimeoutTime_AGSM" SG_ 212 PIM_B_Torque_Achieved_V 0;
BA_ "GenSigTimeoutTime_SGW" SG_ 212 PIM_B_TorqAchieved_AEMD 0;
BA_ "GenSigTimeoutTime_PBWM" SG_ 212 PIM_B_TorqAchieved_AEMD 0;
BA_ "GenSigTimeoutTime_IDCM" SG_ 212 PIM_B_TorqAchieved_AEMD 0;
BA_ "GenSigTimeoutTime_ECM" SG_ 212 PIM_B_TorqAchieved_AEMD 0;
BA_ "GenSigTimeoutTime_DMPI" SG_ 212 PIM_B_TorqAchieved_AEMD 0;
BA_ "GenSigTimeoutTime_BPCM" SG_ 212 PIM_B_TorqAchieved_AEMD 0;
BA_ "GenSigTimeoutTime_AGSM" SG_ 212 PIM_B_TorqAchieved_AEMD 0;
BA_ "GenSigStartValue" SG_ 212 PIM_B_TorqAchieved_AEMD 4096;
BA_ "GenSigTimeoutTime_SGW" SG_ 212 PIM_B_TorqAchieved_AEMD_V 0;
BA_ "GenSigTimeoutTime_PBWM" SG_ 212 PIM_B_TorqAchieved_AEMD_V 0;
BA_ "GenSigTimeoutTime_IDCM" SG_ 212 PIM_B_TorqAchieved_AEMD_V 0;
BA_ "GenSigTimeoutTime_ECM" SG_ 212 PIM_B_TorqAchieved_AEMD_V 0;
BA_ "GenSigTimeoutTime_DMPI" SG_ 212 PIM_B_TorqAchieved_AEMD_V 0;
BA_ "GenSigTimeoutTime_BPCM" SG_ 212 PIM_B_TorqAchieved_AEMD_V 0;
BA_ "GenSigTimeoutTime_AGSM" SG_ 212 PIM_B_TorqAchieved_AEMD_V 0;
BA_ "GenSigTimeoutTime_SGW" SG_ 212 PIM_B_MinTorq 0;
BA_ "GenSigTimeoutTime_PBWM" SG_ 212 PIM_B_MinTorq 0;
BA_ "GenSigTimeoutTime_IDCM" SG_ 212 PIM_B_MinTorq 0;
BA_ "GenSigTimeoutTime_ECM" SG_ 212 PIM_B_MinTorq 0;
BA_ "GenSigTimeoutTime_DMPI" SG_ 212 PIM_B_MinTorq 0;
BA_ "GenSigTimeoutTime_BPCM" SG_ 212 PIM_B_MinTorq 0;
BA_ "GenSigTimeoutTime_AGSM" SG_ 212 PIM_B_MinTorq 0;
BA_ "GenSigStartValue" SG_ 212 PIM_B_MinTorq 4096;
BA_ "GenSigTimeoutTime_SGW" SG_ 212 PIM_B_MtrIndex 0;
BA_ "GenSigTimeoutTime_PBWM" SG_ 212 PIM_B_MtrIndex 0;
BA_ "GenSigTimeoutTime_IDCM" SG_ 212 PIM_B_MtrIndex 0;
BA_ "GenSigTimeoutTime_ECM" SG_ 212 PIM_B_MtrIndex 0;
BA_ "GenSigTimeoutTime_DMPI" SG_ 212 PIM_B_MtrIndex 0;
BA_ "GenSigTimeoutTime_BPCM" SG_ 212 PIM_B_MtrIndex 0;
BA_ "GenSigTimeoutTime_AGSM" SG_ 212 PIM_B_MtrIndex 0;
BA_ "GenSigTimeoutTime_SGW" SG_ 212 PIM_B_MtrMaxCpbltyTrq 0;
BA_ "GenSigTimeoutTime_PBWM" SG_ 212 PIM_B_MtrMaxCpbltyTrq 0;
BA_ "GenSigTimeoutTime_IDCM" SG_ 212 PIM_B_MtrMaxCpbltyTrq 0;
BA_ "GenSigTimeoutTime_ECM" SG_ 212 PIM_B_MtrMaxCpbltyTrq 0;
BA_ "GenSigTimeoutTime_DMPI" SG_ 212 PIM_B_MtrMaxCpbltyTrq 0;
BA_ "GenSigTimeoutTime_BPCM" SG_ 212 PIM_B_MtrMaxCpbltyTrq 0;
BA_ "GenSigTimeoutTime_AGSM" SG_ 212 PIM_B_MtrMaxCpbltyTrq 0;
BA_ "GenSigStartValue" SG_ 212 PIM_B_MtrMaxCpbltyTrq 4096;
BA_ "GenSigTimeoutTime_SGW" SG_ 212 PIM_B_MtrMinCpbltyTrq 0;
BA_ "GenSigTimeoutTime_PBWM" SG_ 212 PIM_B_MtrMinCpbltyTrq 0;
BA_ "GenSigTimeoutTime_IDCM" SG_ 212 PIM_B_MtrMinCpbltyTrq 0;
BA_ "GenSigTimeoutTime_ECM" SG_ 212 PIM_B_MtrMinCpbltyTrq 0;
BA_ "GenSigTimeoutTime_DMPI" SG_ 212 PIM_B_MtrMinCpbltyTrq 0;
BA_ "GenSigTimeoutTime_BPCM" SG_ 212 PIM_B_MtrMinCpbltyTrq 0;
BA_ "GenSigTimeoutTime_AGSM" SG_ 212 PIM_B_MtrMinCpbltyTrq 0;
BA_ "GenSigStartValue" SG_ 212 PIM_B_MtrMinCpbltyTrq 4096;
BA_ "GenSigTimeoutTime_SGW" SG_ 212 PIM_B_RPM 0;
BA_ "GenSigTimeoutTime_IDCM" SG_ 212 PIM_B_RPM 0;
BA_ "GenSigTimeoutTime_ECM" SG_ 212 PIM_B_RPM 0;
BA_ "GenSigTimeoutTime_DMPI" SG_ 212 PIM_B_RPM 0;
BA_ "GenSigTimeoutTime_BPCM" SG_ 212 PIM_B_RPM 0;
BA_ "GenSigTimeoutTime_AGSM" SG_ 212 PIM_B_RPM 0;
BA_ "GenSigStartValue" SG_ 212 PIM_B_RPM 32768;
BA_ "GenSigTimeoutTime_SGW" SG_ 212 PIM_B_RPM_V 0;
BA_ "GenSigTimeoutTime_IDCM" SG_ 212 PIM_B_RPM_V 0;
BA_ "GenSigTimeoutTime_ECM" SG_ 212 PIM_B_RPM_V 0;
BA_ "GenSigTimeoutTime_DMPI" SG_ 212 PIM_B_RPM_V 0;
BA_ "GenSigTimeoutTime_BPCM" SG_ 212 PIM_B_RPM_V 0;
BA_ "GenSigTimeoutTime_AGSM" SG_ 212 PIM_B_RPM_V 0;
BA_ "GenSigTimeoutTime_SGW" SG_ 212 PIM_B_Spd_Lim 0;
BA_ "GenSigTimeoutTime_PBWM" SG_ 212 PIM_B_Spd_Lim 0;
BA_ "GenSigTimeoutTime_IDCM" SG_ 212 PIM_B_Spd_Lim 0;
BA_ "GenSigTimeoutTime_ECM" SG_ 212 PIM_B_Spd_Lim 0;
BA_ "GenSigTimeoutTime_DMPI" SG_ 212 PIM_B_Spd_Lim 0;
BA_ "GenSigTimeoutTime_BPCM" SG_ 212 PIM_B_Spd_Lim 0;
BA_ "GenSigTimeoutTime_AGSM" SG_ 212 PIM_B_Spd_Lim 0;
BA_ "GenSigTimeoutTime_SGW" SG_ 212 PIM_B_SPT_Stat 0;
BA_ "GenSigTimeoutTime_PBWM" SG_ 212 PIM_B_SPT_Stat 0;
BA_ "GenSigTimeoutTime_IDCM" SG_ 212 PIM_B_SPT_Stat 0;
BA_ "GenSigTimeoutTime_ECM" SG_ 212 PIM_B_SPT_Stat 0;
BA_ "GenSigTimeoutTime_DMPI" SG_ 212 PIM_B_SPT_Stat 0;
BA_ "GenSigTimeoutTime_BPCM" SG_ 212 PIM_B_SPT_Stat 0;
BA_ "GenSigTimeoutTime_AGSM" SG_ 212 PIM_B_SPT_Stat 0;
BA_ "GenSigTimeoutTime_SGW" SG_ 212 PIM_B_Torque_Achieved 0;
BA_ "GenSigTimeoutTime_PBWM" SG_ 212 PIM_B_Torque_Achieved 0;
BA_ "GenSigTimeoutTime_IDCM" SG_ 212 PIM_B_Torque_Achieved 0;
BA_ "GenSigTimeoutTime_ECM" SG_ 212 PIM_B_Torque_Achieved 0;
BA_ "GenSigTimeoutTime_DMPI" SG_ 212 PIM_B_Torque_Achieved 0;
BA_ "GenSigTimeoutTime_BPCM" SG_ 212 PIM_B_Torque_Achieved 0;
BA_ "GenSigTimeoutTime_AGSM" SG_ 212 PIM_B_Torque_Achieved 0;
BA_ "GenSigStartValue" SG_ 212 PIM_B_Torque_Achieved 4096;
BA_ "GenSigTimeoutTime_SGW" SG_ 212 PIM_B_CoolantTemp 0;
BA_ "GenSigTimeoutTime_PBWM" SG_ 212 PIM_B_CoolantTemp 0;
BA_ "GenSigTimeoutTime_IDCM" SG_ 212 PIM_B_CoolantTemp 0;
BA_ "GenSigTimeoutTime_ECM" SG_ 212 PIM_B_CoolantTemp 0;
BA_ "GenSigTimeoutTime_DMPI" SG_ 212 PIM_B_CoolantTemp 0;
BA_ "GenSigTimeoutTime_BPCM" SG_ 212 PIM_B_CoolantTemp 0;
BA_ "GenSigTimeoutTime_AGSM" SG_ 212 PIM_B_CoolantTemp 0;
BA_ "GenSigTimeoutTime_SGW" SG_ 212 PIM_B_CpbltySpdDivVolt 0;
BA_ "GenSigTimeoutTime_PBWM" SG_ 212 PIM_B_CpbltySpdDivVolt 0;
BA_ "GenSigTimeoutTime_IDCM" SG_ 212 PIM_B_CpbltySpdDivVolt 0;
BA_ "GenSigTimeoutTime_ECM" SG_ 212 PIM_B_CpbltySpdDivVolt 0;
BA_ "GenSigTimeoutTime_DMPI" SG_ 212 PIM_B_CpbltySpdDivVolt 0;
BA_ "GenSigTimeoutTime_BPCM" SG_ 212 PIM_B_CpbltySpdDivVolt 0;
BA_ "GenSigTimeoutTime_AGSM" SG_ 212 PIM_B_CpbltySpdDivVolt 0;
BA_ "GenSigTimeoutTime_SGW" SG_ 212 PIM_B_DC_Current 0;
BA_ "GenSigTimeoutTime_PBWM" SG_ 212 PIM_B_DC_Current 0;
BA_ "GenSigTimeoutTime_IDCM" SG_ 212 PIM_B_DC_Current 0;
BA_ "GenSigTimeoutTime_ECM" SG_ 212 PIM_B_DC_Current 0;
BA_ "GenSigTimeoutTime_DMPI" SG_ 212 PIM_B_DC_Current 0;
BA_ "GenSigTimeoutTime_AGSM" SG_ 212 PIM_B_DC_Current 0;
BA_ "GenSigStartValue" SG_ 212 PIM_B_DC_Current 16384;
BA_ "GenSigTimeoutTime_SGW" SG_ 212 PIM_B_DC_Current_V 0;
BA_ "GenSigTimeoutTime_PBWM" SG_ 212 PIM_B_DC_Current_V 0;
BA_ "GenSigTimeoutTime_IDCM" SG_ 212 PIM_B_DC_Current_V 0;
BA_ "GenSigTimeoutTime_ECM" SG_ 212 PIM_B_DC_Current_V 0;
BA_ "GenSigTimeoutTime_DMPI" SG_ 212 PIM_B_DC_Current_V 0;
BA_ "GenSigTimeoutTime_BPCM" SG_ 212 PIM_B_DC_Current_V 0;
BA_ "GenSigTimeoutTime_AGSM" SG_ 212 PIM_B_DC_Current_V 0;
BA_ "GenSigTimeoutTime_SGW" SG_ 212 PIM_B_DC_Volt_V 0;
BA_ "GenSigTimeoutTime_PBWM" SG_ 212 PIM_B_DC_Volt_V 0;
BA_ "GenSigTimeoutTime_IDCM" SG_ 212 PIM_B_DC_Volt_V 0;
BA_ "GenSigTimeoutTime_ECM" SG_ 212 PIM_B_DC_Volt_V 0;
BA_ "GenSigTimeoutTime_DMPI" SG_ 212 PIM_B_DC_Volt_V 0;
BA_ "GenSigTimeoutTime_BPCM" SG_ 212 PIM_B_DC_Volt_V 0;
BA_ "GenSigTimeoutTime_AGSM" SG_ 212 PIM_B_DC_Volt_V 0;
BA_ "GenSigTimeoutTime_SGW" SG_ 212 PIM_B_DC_Voltage 0;
BA_ "GenSigTimeoutTime_PBWM" SG_ 212 PIM_B_DC_Voltage 0;
BA_ "GenSigTimeoutTime_IDCM" SG_ 212 PIM_B_DC_Voltage 0;
BA_ "GenSigTimeoutTime_ECM" SG_ 212 PIM_B_DC_Voltage 0;
BA_ "GenSigTimeoutTime_DMPI" SG_ 212 PIM_B_DC_Voltage 0;
BA_ "GenSigTimeoutTime_BPCM" SG_ 212 PIM_B_DC_Voltage 0;
BA_ "GenSigTimeoutTime_AGSM" SG_ 212 PIM_B_DC_Voltage 0;
BA_ "GenSigTimeoutTime_SGW" SG_ 212 PIM_B_DerateReason 0;
BA_ "GenSigTimeoutTime_PBWM" SG_ 212 PIM_B_DerateReason 0;
BA_ "GenSigTimeoutTime_IDCM" SG_ 212 PIM_B_DerateReason 0;
BA_ "GenSigTimeoutTime_ECM" SG_ 212 PIM_B_DerateReason 0;
BA_ "GenSigTimeoutTime_DMPI" SG_ 212 PIM_B_DerateReason 0;
BA_ "GenSigTimeoutTime_BPCM" SG_ 212 PIM_B_DerateReason 0;
BA_ "GenSigTimeoutTime_AGSM" SG_ 212 PIM_B_DerateReason 0;
BA_ "GenSigTimeoutTime_SGW" SG_ 212 PIM_B_DeratingFactor 0;
BA_ "GenSigTimeoutTime_PBWM" SG_ 212 PIM_B_DeratingFactor 0;
BA_ "GenSigTimeoutTime_IDCM" SG_ 212 PIM_B_DeratingFactor 0;
BA_ "GenSigTimeoutTime_ECM" SG_ 212 PIM_B_DeratingFactor 0;
BA_ "GenSigTimeoutTime_DMPI" SG_ 212 PIM_B_DeratingFactor 0;
BA_ "GenSigTimeoutTime_BPCM" SG_ 212 PIM_B_DeratingFactor 0;
BA_ "GenSigTimeoutTime_AGSM" SG_ 212 PIM_B_DeratingFactor 0;
BA_ "GenSigTimeoutTime_SGW" SG_ 212 PIM_B_Dschrge_Status 0;
BA_ "GenSigTimeoutTime_PBWM" SG_ 212 PIM_B_Dschrge_Status 0;
BA_ "GenSigTimeoutTime_IDCM" SG_ 212 PIM_B_Dschrge_Status 0;
BA_ "GenSigTimeoutTime_ECM" SG_ 212 PIM_B_Dschrge_Status 0;
BA_ "GenSigTimeoutTime_DMPI" SG_ 212 PIM_B_Dschrge_Status 0;
BA_ "GenSigTimeoutTime_BPCM" SG_ 212 PIM_B_Dschrge_Status 0;
BA_ "GenSigTimeoutTime_AGSM" SG_ 212 PIM_B_Dschrge_Status 0;
BA_ "GenSigTimeoutTime_SGW" SG_ 212 PIM_B_HV_CnctrOpn_Req 0;
BA_ "GenSigTimeoutTime_PBWM" SG_ 212 PIM_B_HV_CnctrOpn_Req 0;
BA_ "GenSigTimeoutTime_IDCM" SG_ 212 PIM_B_HV_CnctrOpn_Req 0;
BA_ "GenSigTimeoutTime_ECM" SG_ 212 PIM_B_HV_CnctrOpn_Req 0;
BA_ "GenSigTimeoutTime_DMPI" SG_ 212 PIM_B_HV_CnctrOpn_Req 0;
BA_ "GenSigTimeoutTime_BPCM" SG_ 212 PIM_B_HV_CnctrOpn_Req 0;
BA_ "GenSigTimeoutTime_AGSM" SG_ 212 PIM_B_HV_CnctrOpn_Req 0;
BA_ "GenSigTimeoutTime_SGW" SG_ 212 PIM_B_InterlockSts 0;
BA_ "GenSigTimeoutTime_PBWM" SG_ 212 PIM_B_InterlockSts 0;
BA_ "GenSigTimeoutTime_IDCM" SG_ 212 PIM_B_InterlockSts 0;
BA_ "GenSigTimeoutTime_ECM" SG_ 212 PIM_B_InterlockSts 0;
BA_ "GenSigTimeoutTime_DMPI" SG_ 212 PIM_B_InterlockSts 0;
BA_ "GenSigTimeoutTime_BPCM" SG_ 212 PIM_B_InterlockSts 0;
BA_ "GenSigTimeoutTime_AGSM" SG_ 212 PIM_B_InterlockSts 0;
BA_ "GenSigTimeoutTime_SGW" SG_ 212 PIM_B_Invrtr_State 0;
BA_ "GenSigTimeoutTime_PBWM" SG_ 212 PIM_B_Invrtr_State 0;
BA_ "GenSigTimeoutTime_IDCM" SG_ 212 PIM_B_Invrtr_State 0;
BA_ "GenSigTimeoutTime_ECM" SG_ 212 PIM_B_Invrtr_State 0;
BA_ "GenSigTimeoutTime_DMPI" SG_ 212 PIM_B_Invrtr_State 0;
BA_ "GenSigTimeoutTime_BPCM" SG_ 212 PIM_B_Invrtr_State 0;
BA_ "GenSigTimeoutTime_AGSM" SG_ 212 PIM_B_Invrtr_State 0;
BA_ "GenSigTimeoutTime_SGW" SG_ 212 PIM_B_MaxTorq 0;
BA_ "GenSigTimeoutTime_PBWM" SG_ 212 PIM_B_MaxTorq 0;
BA_ "GenSigTimeoutTime_IDCM" SG_ 212 PIM_B_MaxTorq 0;
BA_ "GenSigTimeoutTime_ECM" SG_ 212 PIM_B_MaxTorq 0;
BA_ "GenSigTimeoutTime_DMPI" SG_ 212 PIM_B_MaxTorq 0;
BA_ "GenSigTimeoutTime_BPCM" SG_ 212 PIM_B_MaxTorq 0;
BA_ "GenSigTimeoutTime_AGSM" SG_ 212 PIM_B_MaxTorq 0;
BA_ "GenSigStartValue" SG_ 212 PIM_B_MaxTorq 4096;
BA_ "GenSigTimeoutTime_SGW" SG_ 212 PIM_B_AccelRawV 0;
BA_ "GenSigTimeoutTime_PBWM" SG_ 212 PIM_B_AccelRawV 0;
BA_ "GenSigTimeoutTime_IDCM" SG_ 212 PIM_B_AccelRawV 0;
BA_ "GenSigTimeoutTime_ECM" SG_ 212 PIM_B_AccelRawV 0;
BA_ "GenSigTimeoutTime_DMPI" SG_ 212 PIM_B_AccelRawV 0;
BA_ "GenSigTimeoutTime_BPCM" SG_ 212 PIM_B_AccelRawV 0;
BA_ "GenSigTimeoutTime_AGSM" SG_ 212 PIM_B_AccelRawV 0;
BA_ "GenSigTimeoutTime_SGW" SG_ 212 PIM_B_6SO_Status 0;
BA_ "GenSigTimeoutTime_PBWM" SG_ 212 PIM_B_6SO_Status 0;
BA_ "GenSigTimeoutTime_IDCM" SG_ 212 PIM_B_6SO_Status 0;
BA_ "GenSigTimeoutTime_ECM" SG_ 212 PIM_B_6SO_Status 0;
BA_ "GenSigTimeoutTime_DMPI" SG_ 212 PIM_B_6SO_Status 0;
BA_ "GenSigTimeoutTime_BPCM" SG_ 212 PIM_B_6SO_Status 0;
BA_ "GenSigTimeoutTime_AGSM" SG_ 212 PIM_B_6SO_Status 0;
BA_ "GenSigTimeoutTime_SGW" SG_ 212 PIM_B_3PS_Pos 0;
BA_ "GenSigTimeoutTime_PBWM" SG_ 212 PIM_B_3PS_Pos 0;
BA_ "GenSigTimeoutTime_IDCM" SG_ 212 PIM_B_3PS_Pos 0;
BA_ "GenSigTimeoutTime_ECM" SG_ 212 PIM_B_3PS_Pos 0;
BA_ "GenSigTimeoutTime_DMPI" SG_ 212 PIM_B_3PS_Pos 0;
BA_ "GenSigTimeoutTime_BPCM" SG_ 212 PIM_B_3PS_Pos 0;
BA_ "GenSigTimeoutTime_AGSM" SG_ 212 PIM_B_3PS_Pos 0;
BA_ "GenSigTimeoutTime_SGW" SG_ 212 MC_PIM_B 0;
BA_ "GenSigTimeoutTime_PBWM" SG_ 212 MC_PIM_B 0;
BA_ "GenSigTimeoutTime_IDCM" SG_ 212 MC_PIM_B 0;
BA_ "GenSigTimeoutTime_ECM" SG_ 212 MC_PIM_B 0;
BA_ "GenSigTimeoutTime_DMPI" SG_ 212 MC_PIM_B 0;
BA_ "GenSigTimeoutTime_BPCM" SG_ 212 MC_PIM_B 0;
BA_ "GenSigTimeoutTime_AGSM" SG_ 212 MC_PIM_B 0;
BA_ "GenSigTimeoutTime_SGW" SG_ 212 MAC_PIM_B 0;
BA_ "GenSigTimeoutTime_PBWM" SG_ 212 MAC_PIM_B 0;
BA_ "GenSigTimeoutTime_IDCM" SG_ 212 MAC_PIM_B 0;
BA_ "GenSigTimeoutTime_ECM" SG_ 212 MAC_PIM_B 0;
BA_ "GenSigTimeoutTime_DMPI" SG_ 212 MAC_PIM_B 0;
BA_ "GenSigTimeoutTime_BPCM" SG_ 212 MAC_PIM_B 0;
BA_ "GenSigTimeoutTime_AGSM" SG_ 212 MAC_PIM_B 0;
BA_ "GenSigTimeoutTime_SGW" SG_ 212 CRC_PIM_B 0;
BA_ "GenSigTimeoutTime_PBWM" SG_ 212 CRC_PIM_B 0;
BA_ "GenSigTimeoutTime_IDCM" SG_ 212 CRC_PIM_B 0;
BA_ "GenSigTimeoutTime_ECM" SG_ 212 CRC_PIM_B 0;
BA_ "GenSigTimeoutTime_DMPI" SG_ 212 CRC_PIM_B 0;
BA_ "GenSigTimeoutTime_BPCM" SG_ 212 CRC_PIM_B 0;
BA_ "GenSigTimeoutTime_AGSM" SG_ 212 CRC_PIM_B 0;
BA_ "GenSigTimeoutTime_SGW" SG_ 212 Cntr_PIM_B 0;
BA_ "GenSigTimeoutTime_PBWM" SG_ 212 Cntr_PIM_B 0;
BA_ "GenSigTimeoutTime_IDCM" SG_ 212 Cntr_PIM_B 0;
BA_ "GenSigTimeoutTime_ECM" SG_ 212 Cntr_PIM_B 0;
BA_ "GenSigTimeoutTime_DMPI" SG_ 212 Cntr_PIM_B 0;
BA_ "GenSigTimeoutTime_BPCM" SG_ 212 Cntr_PIM_B 0;
BA_ "GenSigTimeoutTime_AGSM" SG_ 212 Cntr_PIM_B 0;
BA_ "GenSigTimeoutTime_SGW" SG_ 211 PIM_A_Torque_Achieved_V 0;
BA_ "GenSigTimeoutTime_PBWM" SG_ 211 PIM_A_Torque_Achieved_V 0;
BA_ "GenSigTimeoutTime_IDCM" SG_ 211 PIM_A_Torque_Achieved_V 0;
BA_ "GenSigTimeoutTime_DMPI" SG_ 211 PIM_A_Torque_Achieved_V 0;
BA_ "GenSigTimeoutTime_BPCM" SG_ 211 PIM_A_Torque_Achieved_V 0;
BA_ "GenSigTimeoutTime_AGSM" SG_ 211 PIM_A_Torque_Achieved_V 0;
BA_ "GenSigTimeoutTime_SGW" SG_ 211 PIM_A_TorqAchieved_AEMD_V 0;
BA_ "GenSigTimeoutTime_PBWM" SG_ 211 PIM_A_TorqAchieved_AEMD_V 0;
BA_ "GenSigTimeoutTime_IDCM" SG_ 211 PIM_A_TorqAchieved_AEMD_V 0;
BA_ "GenSigTimeoutTime_ECM" SG_ 211 PIM_A_TorqAchieved_AEMD_V 0;
BA_ "GenSigTimeoutTime_DMPI" SG_ 211 PIM_A_TorqAchieved_AEMD_V 0;
BA_ "GenSigTimeoutTime_BPCM" SG_ 211 PIM_A_TorqAchieved_AEMD_V 0;
BA_ "GenSigTimeoutTime_AGSM" SG_ 211 PIM_A_TorqAchieved_AEMD_V 0;
BA_ "GenSigTimeoutTime_SGW" SG_ 211 PIM_A_TorqAchieved_AEMD 0;
BA_ "GenSigTimeoutTime_PBWM" SG_ 211 PIM_A_TorqAchieved_AEMD 0;
BA_ "GenSigTimeoutTime_IDCM" SG_ 211 PIM_A_TorqAchieved_AEMD 0;
BA_ "GenSigTimeoutTime_ECM" SG_ 211 PIM_A_TorqAchieved_AEMD 0;
BA_ "GenSigTimeoutTime_DMPI" SG_ 211 PIM_A_TorqAchieved_AEMD 0;
BA_ "GenSigTimeoutTime_BPCM" SG_ 211 PIM_A_TorqAchieved_AEMD 0;
BA_ "GenSigTimeoutTime_AGSM" SG_ 211 PIM_A_TorqAchieved_AEMD 0;
BA_ "GenSigStartValue" SG_ 211 PIM_A_TorqAchieved_AEMD 4096;
BA_ "GenSigTimeoutTime_SGW" SG_ 211 PIM_A_SPT_Stat 0;
BA_ "GenSigTimeoutTime_PBWM" SG_ 211 PIM_A_SPT_Stat 0;
BA_ "GenSigTimeoutTime_IDCM" SG_ 211 PIM_A_SPT_Stat 0;
BA_ "GenSigTimeoutTime_ECM" SG_ 211 PIM_A_SPT_Stat 0;
BA_ "GenSigTimeoutTime_DMPI" SG_ 211 PIM_A_SPT_Stat 0;
BA_ "GenSigTimeoutTime_BPCM" SG_ 211 PIM_A_SPT_Stat 0;
BA_ "GenSigTimeoutTime_AGSM" SG_ 211 PIM_A_SPT_Stat 0;
BA_ "GenSigTimeoutTime_SGW" SG_ 211 PIM_A_Spd_Lim 0;
BA_ "GenSigTimeoutTime_PBWM" SG_ 211 PIM_A_Spd_Lim 0;
BA_ "GenSigTimeoutTime_IDCM" SG_ 211 PIM_A_Spd_Lim 0;
BA_ "GenSigTimeoutTime_ECM" SG_ 211 PIM_A_Spd_Lim 0;
BA_ "GenSigTimeoutTime_DMPI" SG_ 211 PIM_A_Spd_Lim 0;
BA_ "GenSigTimeoutTime_BPCM" SG_ 211 PIM_A_Spd_Lim 0;
BA_ "GenSigTimeoutTime_AGSM" SG_ 211 PIM_A_Spd_Lim 0;
BA_ "GenSigTimeoutTime_SGW" SG_ 211 PIM_A_RPM_V 0;
BA_ "GenSigTimeoutTime_PBWM" SG_ 211 PIM_A_RPM_V 0;
BA_ "GenSigTimeoutTime_IDCM" SG_ 211 PIM_A_RPM_V 0;
BA_ "GenSigTimeoutTime_ECM" SG_ 211 PIM_A_RPM_V 0;
BA_ "GenSigTimeoutTime_DMPI" SG_ 211 PIM_A_RPM_V 0;
BA_ "GenSigTimeoutTime_BPCM" SG_ 211 PIM_A_RPM_V 0;
BA_ "GenSigTimeoutTime_AGSM" SG_ 211 PIM_A_RPM_V 0;
BA_ "GenSigTimeoutTime_SGW" SG_ 211 PIM_A_RPM 0;
BA_ "GenSigTimeoutTime_PBWM" SG_ 211 PIM_A_RPM 0;
BA_ "GenSigTimeoutTime_IDCM" SG_ 211 PIM_A_RPM 0;
BA_ "GenSigTimeoutTime_ECM" SG_ 211 PIM_A_RPM 0;
BA_ "GenSigTimeoutTime_DMPI" SG_ 211 PIM_A_RPM 0;
BA_ "GenSigTimeoutTime_BPCM" SG_ 211 PIM_A_RPM 0;
BA_ "GenSigTimeoutTime_AGSM" SG_ 211 PIM_A_RPM 0;
BA_ "GenSigStartValue" SG_ 211 PIM_A_RPM 32768;
BA_ "GenSigTimeoutTime_SGW" SG_ 211 PIM_A_MtrMinCpbltyTrq 0;
BA_ "GenSigTimeoutTime_PBWM" SG_ 211 PIM_A_MtrMinCpbltyTrq 0;
BA_ "GenSigTimeoutTime_IDCM" SG_ 211 PIM_A_MtrMinCpbltyTrq 0;
BA_ "GenSigTimeoutTime_ECM" SG_ 211 PIM_A_MtrMinCpbltyTrq 0;
BA_ "GenSigTimeoutTime_DMPI" SG_ 211 PIM_A_MtrMinCpbltyTrq 0;
BA_ "GenSigTimeoutTime_BPCM" SG_ 211 PIM_A_MtrMinCpbltyTrq 0;
BA_ "GenSigTimeoutTime_AGSM" SG_ 211 PIM_A_MtrMinCpbltyTrq 0;
BA_ "GenSigStartValue" SG_ 211 PIM_A_MtrMinCpbltyTrq 4096;
BA_ "GenSigTimeoutTime_SGW" SG_ 211 PIM_A_MtrMaxCpbltyTrq 0;
BA_ "GenSigTimeoutTime_PBWM" SG_ 211 PIM_A_MtrMaxCpbltyTrq 0;
BA_ "GenSigTimeoutTime_IDCM" SG_ 211 PIM_A_MtrMaxCpbltyTrq 0;
BA_ "GenSigTimeoutTime_ECM" SG_ 211 PIM_A_MtrMaxCpbltyTrq 0;
BA_ "GenSigTimeoutTime_DMPI" SG_ 211 PIM_A_MtrMaxCpbltyTrq 0;
BA_ "GenSigTimeoutTime_BPCM" SG_ 211 PIM_A_MtrMaxCpbltyTrq 0;
BA_ "GenSigTimeoutTime_AGSM" SG_ 211 PIM_A_MtrMaxCpbltyTrq 0;
BA_ "GenSigStartValue" SG_ 211 PIM_A_MtrMaxCpbltyTrq 4096;
BA_ "GenSigTimeoutTime_SGW" SG_ 211 PIM_A_MtrIndex 0;
BA_ "GenSigTimeoutTime_PBWM" SG_ 211 PIM_A_MtrIndex 0;
BA_ "GenSigTimeoutTime_IDCM" SG_ 211 PIM_A_MtrIndex 0;
BA_ "GenSigTimeoutTime_ECM" SG_ 211 PIM_A_MtrIndex 0;
BA_ "GenSigTimeoutTime_DMPI" SG_ 211 PIM_A_MtrIndex 0;
BA_ "GenSigTimeoutTime_BPCM" SG_ 211 PIM_A_MtrIndex 0;
BA_ "GenSigTimeoutTime_AGSM" SG_ 211 PIM_A_MtrIndex 0;
BA_ "GenSigTimeoutTime_SGW" SG_ 211 PIM_A_MinTorq 0;
BA_ "GenSigTimeoutTime_PBWM" SG_ 211 PIM_A_MinTorq 0;
BA_ "GenSigTimeoutTime_IDCM" SG_ 211 PIM_A_MinTorq 0;
BA_ "GenSigTimeoutTime_ECM" SG_ 211 PIM_A_MinTorq 0;
BA_ "GenSigTimeoutTime_DMPI" SG_ 211 PIM_A_MinTorq 0;
BA_ "GenSigTimeoutTime_BPCM" SG_ 211 PIM_A_MinTorq 0;
BA_ "GenSigTimeoutTime_AGSM" SG_ 211 PIM_A_MinTorq 0;
BA_ "GenSigStartValue" SG_ 211 PIM_A_MinTorq 4096;
BA_ "GenSigTimeoutTime_SGW" SG_ 211 PIM_A_MaxTorq 0;
BA_ "GenSigTimeoutTime_PBWM" SG_ 211 PIM_A_MaxTorq 0;
BA_ "GenSigTimeoutTime_IDCM" SG_ 211 PIM_A_MaxTorq 0;
BA_ "GenSigTimeoutTime_ECM" SG_ 211 PIM_A_MaxTorq 0;
BA_ "GenSigTimeoutTime_DMPI" SG_ 211 PIM_A_MaxTorq 0;
BA_ "GenSigTimeoutTime_BPCM" SG_ 211 PIM_A_MaxTorq 0;
BA_ "GenSigTimeoutTime_AGSM" SG_ 211 PIM_A_MaxTorq 0;
BA_ "GenSigStartValue" SG_ 211 PIM_A_MaxTorq 4096;
BA_ "GenSigTimeoutTime_SGW" SG_ 211 PIM_A_Invrtr_State 0;
BA_ "GenSigTimeoutTime_PBWM" SG_ 211 PIM_A_Invrtr_State 0;
BA_ "GenSigTimeoutTime_IDCM" SG_ 211 PIM_A_Invrtr_State 0;
BA_ "GenSigTimeoutTime_ECM" SG_ 211 PIM_A_Invrtr_State 0;
BA_ "GenSigTimeoutTime_DMPI" SG_ 211 PIM_A_Invrtr_State 0;
BA_ "GenSigTimeoutTime_BPCM" SG_ 211 PIM_A_Invrtr_State 0;
BA_ "GenSigTimeoutTime_AGSM" SG_ 211 PIM_A_Invrtr_State 0;
BA_ "GenSigTimeoutTime_SGW" SG_ 211 PIM_A_InterlockSts 0;
BA_ "GenSigTimeoutTime_PBWM" SG_ 211 PIM_A_InterlockSts 0;
BA_ "GenSigTimeoutTime_IDCM" SG_ 211 PIM_A_InterlockSts 0;
BA_ "GenSigTimeoutTime_ECM" SG_ 211 PIM_A_InterlockSts 0;
BA_ "GenSigTimeoutTime_DMPI" SG_ 211 PIM_A_InterlockSts 0;
BA_ "GenSigTimeoutTime_BPCM" SG_ 211 PIM_A_InterlockSts 0;
BA_ "GenSigTimeoutTime_AGSM" SG_ 211 PIM_A_InterlockSts 0;
BA_ "GenSigTimeoutTime_SGW" SG_ 211 PIM_A_HV_CnctrOpn_Req 0;
BA_ "GenSigTimeoutTime_PBWM" SG_ 211 PIM_A_HV_CnctrOpn_Req 0;
BA_ "GenSigTimeoutTime_IDCM" SG_ 211 PIM_A_HV_CnctrOpn_Req 0;
BA_ "GenSigTimeoutTime_ECM" SG_ 211 PIM_A_HV_CnctrOpn_Req 0;
BA_ "GenSigTimeoutTime_DMPI" SG_ 211 PIM_A_HV_CnctrOpn_Req 0;
BA_ "GenSigTimeoutTime_BPCM" SG_ 211 PIM_A_HV_CnctrOpn_Req 0;
BA_ "GenSigTimeoutTime_AGSM" SG_ 211 PIM_A_HV_CnctrOpn_Req 0;
BA_ "GenSigTimeoutTime_SGW" SG_ 211 PIM_A_Dschrge_Status 0;
BA_ "GenSigTimeoutTime_PBWM" SG_ 211 PIM_A_Dschrge_Status 0;
BA_ "GenSigTimeoutTime_IDCM" SG_ 211 PIM_A_Dschrge_Status 0;
BA_ "GenSigTimeoutTime_ECM" SG_ 211 PIM_A_Dschrge_Status 0;
BA_ "GenSigTimeoutTime_DMPI" SG_ 211 PIM_A_Dschrge_Status 0;
BA_ "GenSigTimeoutTime_BPCM" SG_ 211 PIM_A_Dschrge_Status 0;
BA_ "GenSigTimeoutTime_AGSM" SG_ 211 PIM_A_Dschrge_Status 0;
BA_ "GenSigTimeoutTime_BPCM" SG_ 211 PIM_A_DeratingFactor 0;
BA_ "GenSigTimeoutTime_AGSM" SG_ 211 PIM_A_DeratingFactor 0;
BA_ "GenSigTimeoutTime_SGW" SG_ 211 PIM_A_DeratingFactor 0;
BA_ "GenSigTimeoutTime_PBWM" SG_ 211 PIM_A_DeratingFactor 0;
BA_ "GenSigTimeoutTime_IDCM" SG_ 211 PIM_A_DeratingFactor 0;
BA_ "GenSigTimeoutTime_ECM" SG_ 211 PIM_A_DeratingFactor 0;
BA_ "GenSigTimeoutTime_DMPI" SG_ 211 PIM_A_DeratingFactor 0;
BA_ "GenSigTimeoutTime_SGW" SG_ 211 PIM_A_DerateReason 0;
BA_ "GenSigTimeoutTime_PBWM" SG_ 211 PIM_A_DerateReason 0;
BA_ "GenSigTimeoutTime_IDCM" SG_ 211 PIM_A_DerateReason 0;
BA_ "GenSigTimeoutTime_ECM" SG_ 211 PIM_A_DerateReason 0;
BA_ "GenSigTimeoutTime_DMPI" SG_ 211 PIM_A_DerateReason 0;
BA_ "GenSigTimeoutTime_BPCM" SG_ 211 PIM_A_DerateReason 0;
BA_ "GenSigTimeoutTime_AGSM" SG_ 211 PIM_A_DerateReason 0;
BA_ "GenSigTimeoutTime_SGW" SG_ 211 PIM_A_DC_Voltage 0;
BA_ "GenSigTimeoutTime_PBWM" SG_ 211 PIM_A_DC_Voltage 0;
BA_ "GenSigTimeoutTime_IDCM" SG_ 211 PIM_A_DC_Voltage 0;
BA_ "GenSigTimeoutTime_ECM" SG_ 211 PIM_A_DC_Voltage 0;
BA_ "GenSigTimeoutTime_DMPI" SG_ 211 PIM_A_DC_Voltage 0;
BA_ "GenSigTimeoutTime_BPCM" SG_ 211 PIM_A_DC_Voltage 0;
BA_ "GenSigTimeoutTime_AGSM" SG_ 211 PIM_A_DC_Voltage 0;
BA_ "GenSigTimeoutTime_SGW" SG_ 211 PIM_A_DC_Volt_V 0;
BA_ "GenSigTimeoutTime_PBWM" SG_ 211 PIM_A_DC_Volt_V 0;
BA_ "GenSigTimeoutTime_IDCM" SG_ 211 PIM_A_DC_Volt_V 0;
BA_ "GenSigTimeoutTime_ECM" SG_ 211 PIM_A_DC_Volt_V 0;
BA_ "GenSigTimeoutTime_DMPI" SG_ 211 PIM_A_DC_Volt_V 0;
BA_ "GenSigTimeoutTime_BPCM" SG_ 211 PIM_A_DC_Volt_V 0;
BA_ "GenSigTimeoutTime_AGSM" SG_ 211 PIM_A_DC_Volt_V 0;
BA_ "GenSigTimeoutTime_SGW" SG_ 211 PIM_A_DC_Current_V 0;
BA_ "GenSigTimeoutTime_PBWM" SG_ 211 PIM_A_DC_Current_V 0;
BA_ "GenSigTimeoutTime_IDCM" SG_ 211 PIM_A_DC_Current_V 0;
BA_ "GenSigTimeoutTime_ECM" SG_ 211 PIM_A_DC_Current_V 0;
BA_ "GenSigTimeoutTime_SGW" SG_ 211 PIM_A_Torque_Achieved 0;
BA_ "GenSigTimeoutTime_PBWM" SG_ 211 PIM_A_Torque_Achieved 0;
BA_ "GenSigTimeoutTime_IDCM" SG_ 211 PIM_A_Torque_Achieved 0;
BA_ "GenSigTimeoutTime_DMPI" SG_ 211 PIM_A_Torque_Achieved 0;
BA_ "GenSigTimeoutTime_BPCM" SG_ 211 PIM_A_Torque_Achieved 0;
BA_ "GenSigTimeoutTime_AGSM" SG_ 211 PIM_A_Torque_Achieved 0;
BA_ "GenSigStartValue" SG_ 211 PIM_A_Torque_Achieved 4096;
BA_ "GenSigTimeoutTime_SGW" SG_ 212 PIM_B_AccelRaw 0;
BA_ "GenSigTimeoutTime_PBWM" SG_ 212 PIM_B_AccelRaw 0;
BA_ "GenSigTimeoutTime_IDCM" SG_ 212 PIM_B_AccelRaw 0;
BA_ "GenSigTimeoutTime_ECM" SG_ 212 PIM_B_AccelRaw 0;
BA_ "GenSigTimeoutTime_DMPI" SG_ 212 PIM_B_AccelRaw 0;
BA_ "GenSigTimeoutTime_BPCM" SG_ 212 PIM_B_AccelRaw 0;
BA_ "GenSigTimeoutTime_AGSM" SG_ 212 PIM_B_AccelRaw 0;
BA_ "GenSigStartValue" SG_ 212 PIM_B_AccelRaw 32768;
BA_ "GenSigTimeoutTime_SGW" SG_ 211 PIM_A_AccelRaw 0;
BA_ "GenSigTimeoutTime_PBWM" SG_ 211 PIM_A_AccelRaw 0;
BA_ "GenSigTimeoutTime_IDCM" SG_ 211 PIM_A_AccelRaw 0;
BA_ "GenSigTimeoutTime_ECM" SG_ 211 PIM_A_AccelRaw 0;
BA_ "GenSigTimeoutTime_DMPI" SG_ 211 PIM_A_AccelRaw 0;
BA_ "GenSigTimeoutTime_BPCM" SG_ 211 PIM_A_AccelRaw 0;
BA_ "GenSigTimeoutTime_AGSM" SG_ 211 PIM_A_AccelRaw 0;
BA_ "GenSigStartValue" SG_ 211 PIM_A_AccelRaw 32768;
BA_ "GenSigTimeoutTime_PBWM" SG_ 2654339132 WakeupSource_FD11_PBWM 0;
BA_ "GenSigTimeoutTime_IDCM" SG_ 2654339132 WakeupSource_FD11_PBWM 0;
BA_ "GenSigTimeoutTime_ECM" SG_ 2654339132 WakeupSource_FD11_PBWM 0;
BA_ "GenSigTimeoutTime_DMPI" SG_ 2654339132 WakeupSource_FD11_PBWM 0;
BA_ "GenSigTimeoutTime_BPCM" SG_ 2654339132 WakeupSource_FD11_PBWM 0;
BA_ "GenSigTimeoutTime_AGSM" SG_ 2654339132 WakeupSource_FD11_PBWM 0;
BA_ "GenSigTimeoutTime_PBWM" SG_ 2654339132 WakeupSource_FD05_PBWM 0;
BA_ "GenSigTimeoutTime_IDCM" SG_ 2654339132 WakeupSource_FD05_PBWM 0;
BA_ "GenSigTimeoutTime_ECM" SG_ 2654339132 WakeupSource_FD05_PBWM 0;
BA_ "GenSigTimeoutTime_DMPI" SG_ 2654339132 WakeupSource_FD05_PBWM 0;
BA_ "GenSigTimeoutTime_BPCM" SG_ 2654339132 WakeupSource_FD05_PBWM 0;
BA_ "GenSigTimeoutTime_AGSM" SG_ 2654339132 WakeupSource_FD05_PBWM 0;
BA_ "GenSigTimeoutTime_PBWM" SG_ 2654339132 StayActiveSource_FD11_PBWM 0;
BA_ "GenSigTimeoutTime_IDCM" SG_ 2654339132 StayActiveSource_FD11_PBWM 0;
BA_ "GenSigTimeoutTime_ECM" SG_ 2654339132 StayActiveSource_FD11_PBWM 0;
BA_ "GenSigTimeoutTime_DMPI" SG_ 2654339132 StayActiveSource_FD11_PBWM 0;
BA_ "GenSigTimeoutTime_BPCM" SG_ 2654339132 StayActiveSource_FD11_PBWM 0;
BA_ "GenSigTimeoutTime_AGSM" SG_ 2654339132 StayActiveSource_FD11_PBWM 0;
BA_ "GenSigTimeoutTime_PBWM" SG_ 2654339132 StayActiveSource_FD05_PBWM 0;
BA_ "GenSigTimeoutTime_IDCM" SG_ 2654339132 StayActiveSource_FD05_PBWM 0;
BA_ "GenSigTimeoutTime_ECM" SG_ 2654339132 StayActiveSource_FD05_PBWM 0;
BA_ "GenSigTimeoutTime_DMPI" SG_ 2654339132 StayActiveSource_FD05_PBWM 0;
BA_ "GenSigTimeoutTime_BPCM" SG_ 2654339132 StayActiveSource_FD05_PBWM 0;
BA_ "GenSigTimeoutTime_AGSM" SG_ 2654339132 StayActiveSource_FD05_PBWM 0;
BA_ "GenSigTimeoutTime_PBWM" SG_ 2654339132 PreviousCanNMState_FD11_PBWM 0;
BA_ "GenSigTimeoutTime_IDCM" SG_ 2654339132 PreviousCanNMState_FD11_PBWM 0;
BA_ "GenSigTimeoutTime_ECM" SG_ 2654339132 PreviousCanNMState_FD11_PBWM 0;
BA_ "GenSigTimeoutTime_DMPI" SG_ 2654339132 PreviousCanNMState_FD11_PBWM 0;
BA_ "GenSigTimeoutTime_BPCM" SG_ 2654339132 PreviousCanNMState_FD11_PBWM 0;
BA_ "GenSigTimeoutTime_AGSM" SG_ 2654339132 PreviousCanNMState_FD11_PBWM 0;
BA_ "GenSigTimeoutTime_PBWM" SG_ 2654339132 PreviousCanNMState_FD05_PBWM 0;
BA_ "GenSigTimeoutTime_IDCM" SG_ 2654339132 PreviousCanNMState_FD05_PBWM 0;
BA_ "GenSigTimeoutTime_ECM" SG_ 2654339132 PreviousCanNMState_FD05_PBWM 0;
BA_ "GenSigTimeoutTime_DMPI" SG_ 2654339132 PreviousCanNMState_FD05_PBWM 0;
BA_ "GenSigTimeoutTime_BPCM" SG_ 2654339132 PreviousCanNMState_FD05_PBWM 0;
BA_ "GenSigTimeoutTime_AGSM" SG_ 2654339132 PreviousCanNMState_FD05_PBWM 0;
BA_ "GenSigTimeoutTime_PBWM" SG_ 2654339132 GenericFailSts_FD11_PBWM 0;
BA_ "GenSigTimeoutTime_IDCM" SG_ 2654339132 GenericFailSts_FD11_PBWM 0;
BA_ "GenSigTimeoutTime_ECM" SG_ 2654339132 GenericFailSts_FD11_PBWM 0;
BA_ "GenSigTimeoutTime_DMPI" SG_ 2654339132 GenericFailSts_FD11_PBWM 0;
BA_ "GenSigTimeoutTime_BPCM" SG_ 2654339132 GenericFailSts_FD11_PBWM 0;
BA_ "GenSigTimeoutTime_AGSM" SG_ 2654339132 GenericFailSts_FD11_PBWM 0;
BA_ "GenSigTimeoutTime_PBWM" SG_ 2654339132 CurrentCanNMState_FD05_PBWM 0;
BA_ "GenSigTimeoutTime_IDCM" SG_ 2654339132 CurrentCanNMState_FD05_PBWM 0;
BA_ "GenSigTimeoutTime_ECM" SG_ 2654339132 CurrentCanNMState_FD05_PBWM 0;
BA_ "GenSigTimeoutTime_DMPI" SG_ 2654339132 CurrentCanNMState_FD05_PBWM 0;
BA_ "GenSigTimeoutTime_BPCM" SG_ 2654339132 CurrentCanNMState_FD05_PBWM 0;
BA_ "GenSigTimeoutTime_AGSM" SG_ 2654339132 CurrentCanNMState_FD05_PBWM 0;
BA_ "GenSigTimeoutTime_PBWM" SG_ 2654339132 GenericFailSts_FD05_PBWM 0;
BA_ "GenSigTimeoutTime_IDCM" SG_ 2654339132 GenericFailSts_FD05_PBWM 0;
BA_ "GenSigTimeoutTime_ECM" SG_ 2654339132 GenericFailSts_FD05_PBWM 0;
BA_ "GenSigTimeoutTime_DMPI" SG_ 2654339132 GenericFailSts_FD05_PBWM 0;
BA_ "GenSigTimeoutTime_BPCM" SG_ 2654339132 GenericFailSts_FD05_PBWM 0;
BA_ "GenSigTimeoutTime_AGSM" SG_ 2654339132 GenericFailSts_FD05_PBWM 0;
BA_ "GenSigTimeoutTime_PBWM" SG_ 2654339132 EOL_FD11_PBWM 0;
BA_ "GenSigTimeoutTime_IDCM" SG_ 2654339132 EOL_FD11_PBWM 0;
BA_ "GenSigTimeoutTime_ECM" SG_ 2654339132 EOL_FD11_PBWM 0;
BA_ "GenSigTimeoutTime_DMPI" SG_ 2654339132 EOL_FD11_PBWM 0;
BA_ "GenSigTimeoutTime_BPCM" SG_ 2654339132 EOL_FD11_PBWM 0;
BA_ "GenSigTimeoutTime_AGSM" SG_ 2654339132 EOL_FD11_PBWM 0;
BA_ "GenSigTimeoutTime_PBWM" SG_ 2654339132 EOL_FD05_PBWM 0;
BA_ "GenSigTimeoutTime_IDCM" SG_ 2654339132 EOL_FD05_PBWM 0;
BA_ "GenSigTimeoutTime_ECM" SG_ 2654339132 EOL_FD05_PBWM 0;
BA_ "GenSigTimeoutTime_DMPI" SG_ 2654339132 EOL_FD05_PBWM 0;
BA_ "GenSigTimeoutTime_BPCM" SG_ 2654339132 EOL_FD05_PBWM 0;
BA_ "GenSigTimeoutTime_AGSM" SG_ 2654339132 EOL_FD05_PBWM 0;
BA_ "GenSigTimeoutTime_PBWM" SG_ 2654339132 DES_FD11_PBWM 0;
BA_ "GenSigTimeoutTime_IDCM" SG_ 2654339132 DES_FD11_PBWM 0;
BA_ "GenSigTimeoutTime_ECM" SG_ 2654339132 DES_FD11_PBWM 0;
BA_ "GenSigTimeoutTime_DMPI" SG_ 2654339132 DES_FD11_PBWM 0;
BA_ "GenSigTimeoutTime_BPCM" SG_ 2654339132 DES_FD11_PBWM 0;
BA_ "GenSigTimeoutTime_AGSM" SG_ 2654339132 DES_FD11_PBWM 0;
BA_ "GenSigTimeoutTime_PBWM" SG_ 2654339132 DES_FD05_PBWM 0;
BA_ "GenSigTimeoutTime_IDCM" SG_ 2654339132 DES_FD05_PBWM 0;
BA_ "GenSigTimeoutTime_ECM" SG_ 2654339132 DES_FD05_PBWM 0;
BA_ "GenSigTimeoutTime_DMPI" SG_ 2654339132 DES_FD05_PBWM 0;
BA_ "GenSigTimeoutTime_BPCM" SG_ 2654339132 DES_FD05_PBWM 0;
BA_ "GenSigTimeoutTime_AGSM" SG_ 2654339132 DES_FD05_PBWM 0;
BA_ "GenSigTimeoutTime_PBWM" SG_ 2654339132 CurrentFailSts_FD11_PBWM 0;
BA_ "GenSigTimeoutTime_IDCM" SG_ 2654339132 CurrentFailSts_FD11_PBWM 0;
BA_ "GenSigTimeoutTime_ECM" SG_ 2654339132 CurrentFailSts_FD11_PBWM 0;
BA_ "GenSigTimeoutTime_DMPI" SG_ 2654339132 CurrentFailSts_FD11_PBWM 0;
BA_ "GenSigTimeoutTime_BPCM" SG_ 2654339132 CurrentFailSts_FD11_PBWM 0;
BA_ "GenSigTimeoutTime_AGSM" SG_ 2654339132 CurrentFailSts_FD11_PBWM 0;
BA_ "GenSigTimeoutTime_PBWM" SG_ 2654339132 CurrentFailSts_FD05_PBWM 0;
BA_ "GenSigTimeoutTime_IDCM" SG_ 2654339132 CurrentFailSts_FD05_PBWM 0;
BA_ "GenSigTimeoutTime_ECM" SG_ 2654339132 CurrentFailSts_FD05_PBWM 0;
BA_ "GenSigTimeoutTime_DMPI" SG_ 2654339132 CurrentFailSts_FD05_PBWM 0;
BA_ "GenSigTimeoutTime_BPCM" SG_ 2654339132 CurrentFailSts_FD05_PBWM 0;
BA_ "GenSigTimeoutTime_AGSM" SG_ 2654339132 CurrentFailSts_FD05_PBWM 0;
BA_ "GenSigTimeoutTime_PBWM" SG_ 2654339132 CurrentCanNMState_FD11_PBWM 0;
BA_ "GenSigTimeoutTime_IDCM" SG_ 2654339132 CurrentCanNMState_FD11_PBWM 0;
BA_ "GenSigTimeoutTime_ECM" SG_ 2654339132 CurrentCanNMState_FD11_PBWM 0;
BA_ "GenSigTimeoutTime_DMPI" SG_ 2654339132 CurrentCanNMState_FD11_PBWM 0;
BA_ "GenSigTimeoutTime_BPCM" SG_ 2654339132 CurrentCanNMState_FD11_PBWM 0;
BA_ "GenSigTimeoutTime_AGSM" SG_ 2654339132 CurrentCanNMState_FD11_PBWM 0;
BA_ "GenSigTimeoutTime_DMPI" SG_ 211 PIM_A_DC_Current_V 0;
BA_ "GenSigTimeoutTime_BPCM" SG_ 211 PIM_A_DC_Current_V 0;
BA_ "GenSigTimeoutTime_AGSM" SG_ 211 PIM_A_DC_Current_V 0;
BA_ "GenSigTimeoutTime_SGW" SG_ 211 PIM_A_DC_Current 0;
BA_ "GenSigTimeoutTime_PBWM" SG_ 211 PIM_A_DC_Current 0;
BA_ "GenSigTimeoutTime_IDCM" SG_ 211 PIM_A_DC_Current 0;
BA_ "GenSigTimeoutTime_ECM" SG_ 211 PIM_A_DC_Current 0;
BA_ "GenSigTimeoutTime_DMPI" SG_ 211 PIM_A_DC_Current 0;
BA_ "GenSigTimeoutTime_AGSM" SG_ 211 PIM_A_DC_Current 0;
BA_ "GenSigStartValue" SG_ 211 PIM_A_DC_Current 16384;
BA_ "GenSigTimeoutTime_SGW" SG_ 211 PIM_A_CpbltySpdDivVolt 0;
BA_ "GenSigTimeoutTime_PBWM" SG_ 211 PIM_A_CpbltySpdDivVolt 0;
BA_ "GenSigTimeoutTime_IDCM" SG_ 211 PIM_A_CpbltySpdDivVolt 0;
BA_ "GenSigTimeoutTime_ECM" SG_ 211 PIM_A_CpbltySpdDivVolt 0;
BA_ "GenSigTimeoutTime_DMPI" SG_ 211 PIM_A_CpbltySpdDivVolt 0;
BA_ "GenSigTimeoutTime_BPCM" SG_ 211 PIM_A_CpbltySpdDivVolt 0;
BA_ "GenSigTimeoutTime_AGSM" SG_ 211 PIM_A_CpbltySpdDivVolt 0;
BA_ "GenSigTimeoutTime_SGW" SG_ 211 PIM_A_CoolantTemp 0;
BA_ "GenSigTimeoutTime_PBWM" SG_ 211 PIM_A_CoolantTemp 0;
BA_ "GenSigTimeoutTime_IDCM" SG_ 211 PIM_A_CoolantTemp 0;
BA_ "GenSigTimeoutTime_ECM" SG_ 211 PIM_A_CoolantTemp 0;
BA_ "GenSigTimeoutTime_DMPI" SG_ 211 PIM_A_CoolantTemp 0;
BA_ "GenSigTimeoutTime_BPCM" SG_ 211 PIM_A_CoolantTemp 0;
BA_ "GenSigTimeoutTime_AGSM" SG_ 211 PIM_A_CoolantTemp 0;
BA_ "GenSigTimeoutTime_SGW" SG_ 211 PIM_A_AccelRawV 0;
BA_ "GenSigTimeoutTime_PBWM" SG_ 211 PIM_A_AccelRawV 0;
BA_ "GenSigTimeoutTime_IDCM" SG_ 211 PIM_A_AccelRawV 0;
BA_ "GenSigTimeoutTime_ECM" SG_ 211 PIM_A_AccelRawV 0;
BA_ "GenSigTimeoutTime_DMPI" SG_ 211 PIM_A_AccelRawV 0;
BA_ "GenSigTimeoutTime_BPCM" SG_ 211 PIM_A_AccelRawV 0;
BA_ "GenSigTimeoutTime_AGSM" SG_ 211 PIM_A_AccelRawV 0;
BA_ "GenSigTimeoutTime_SGW" SG_ 211 PIM_A_6SO_Status 0;
BA_ "GenSigTimeoutTime_PBWM" SG_ 211 PIM_A_6SO_Status 0;
BA_ "GenSigTimeoutTime_IDCM" SG_ 211 PIM_A_6SO_Status 0;
BA_ "GenSigTimeoutTime_ECM" SG_ 211 PIM_A_6SO_Status 0;
BA_ "GenSigTimeoutTime_DMPI" SG_ 211 PIM_A_6SO_Status 0;
BA_ "GenSigTimeoutTime_BPCM" SG_ 211 PIM_A_6SO_Status 0;
BA_ "GenSigTimeoutTime_AGSM" SG_ 211 PIM_A_6SO_Status 0;
BA_ "GenSigTimeoutTime_SGW" SG_ 211 PIM_A_3PS_Pos 0;
BA_ "GenSigTimeoutTime_PBWM" SG_ 211 PIM_A_3PS_Pos 0;
BA_ "GenSigTimeoutTime_IDCM" SG_ 211 PIM_A_3PS_Pos 0;
BA_ "GenSigTimeoutTime_ECM" SG_ 211 PIM_A_3PS_Pos 0;
BA_ "GenSigTimeoutTime_DMPI" SG_ 211 PIM_A_3PS_Pos 0;
BA_ "GenSigTimeoutTime_BPCM" SG_ 211 PIM_A_3PS_Pos 0;
BA_ "GenSigTimeoutTime_AGSM" SG_ 211 PIM_A_3PS_Pos 0;
BA_ "GenSigTimeoutTime_SGW" SG_ 211 MC_PIM_A 0;
BA_ "GenSigTimeoutTime_PBWM" SG_ 211 MC_PIM_A 0;
BA_ "GenSigTimeoutTime_IDCM" SG_ 211 MC_PIM_A 0;
BA_ "GenSigTimeoutTime_ECM" SG_ 211 MC_PIM_A 0;
BA_ "GenSigTimeoutTime_DMPI" SG_ 211 MC_PIM_A 0;
BA_ "GenSigTimeoutTime_BPCM" SG_ 211 MC_PIM_A 0;
BA_ "GenSigTimeoutTime_AGSM" SG_ 211 MC_PIM_A 0;
BA_ "GenSigTimeoutTime_SGW" SG_ 211 Cntr_PIM_A 0;
BA_ "GenSigTimeoutTime_PBWM" SG_ 211 Cntr_PIM_A 0;
BA_ "GenSigTimeoutTime_IDCM" SG_ 211 Cntr_PIM_A 0;
BA_ "GenSigTimeoutTime_ECM" SG_ 211 Cntr_PIM_A 0;
BA_ "GenSigTimeoutTime_DMPI" SG_ 211 Cntr_PIM_A 0;
BA_ "GenSigTimeoutTime_BPCM" SG_ 211 Cntr_PIM_A 0;
BA_ "GenSigTimeoutTime_AGSM" SG_ 211 Cntr_PIM_A 0;
BA_ "GenSigTimeoutTime_SGW" SG_ 211 MAC_PIM_A 0;
BA_ "GenSigTimeoutTime_PBWM" SG_ 211 MAC_PIM_A 0;
BA_ "GenSigTimeoutTime_IDCM" SG_ 211 MAC_PIM_A 0;
BA_ "GenSigTimeoutTime_ECM" SG_ 211 MAC_PIM_A 0;
BA_ "GenSigTimeoutTime_DMPI" SG_ 211 MAC_PIM_A 0;
BA_ "GenSigTimeoutTime_BPCM" SG_ 211 MAC_PIM_A 0;
BA_ "GenSigTimeoutTime_AGSM" SG_ 211 MAC_PIM_A 0;
BA_ "GenSigTimeoutTime_SGW" SG_ 211 CRC_PIM_A 0;
BA_ "GenSigTimeoutTime_PBWM" SG_ 211 CRC_PIM_A 0;
BA_ "GenSigTimeoutTime_IDCM" SG_ 211 CRC_PIM_A 0;
BA_ "GenSigTimeoutTime_ECM" SG_ 211 CRC_PIM_A 0;
BA_ "GenSigTimeoutTime_DMPI" SG_ 211 CRC_PIM_A 0;
BA_ "GenSigTimeoutTime_BPCM" SG_ 211 CRC_PIM_A 0;
BA_ "GenSigTimeoutTime_AGSM" SG_ 211 CRC_PIM_A 0;
BA_ "GenSigTimeoutTime_SGW" SG_ 215 Pinion_OverspeedWarning 0;
BA_ "GenSigTimeoutTime_PBWM" SG_ 215 Pinion_OverspeedWarning 0;
BA_ "GenSigTimeoutTime_IDCM" SG_ 215 Pinion_OverspeedWarning 0;
BA_ "GenSigTimeoutTime_ECM" SG_ 215 Pinion_OverspeedWarning 0;
BA_ "GenSigTimeoutTime_DMPI" SG_ 215 Pinion_OverspeedWarning 0;
BA_ "GenSigTimeoutTime_BPCM" SG_ 215 Pinion_OverspeedWarning 0;
BA_ "GenSigTimeoutTime_AGSM" SG_ 215 Pinion_OverspeedWarning 0;
BA_ "GenSigTimeoutTime_SGW" SG_ 215 PCU_Max_DischargePowerLmt 0;
BA_ "GenSigTimeoutTime_PBWM" SG_ 215 PCU_Max_DischargePowerLmt 0;
BA_ "GenSigTimeoutTime_IDCM" SG_ 215 PCU_Max_DischargePowerLmt 0;
BA_ "GenSigTimeoutTime_ECM" SG_ 215 PCU_Max_DischargePowerLmt 0;
BA_ "GenSigTimeoutTime_DMPI" SG_ 215 PCU_Max_DischargePowerLmt 0;
BA_ "GenSigTimeoutTime_BPCM" SG_ 215 PCU_Max_DischargePowerLmt 0;
BA_ "GenSigTimeoutTime_AGSM" SG_ 215 PCU_Max_DischargePowerLmt 0;
BA_ "GenSigTimeoutTime_SGW" SG_ 215 PCU_MaxBoostedVoltage 0;
BA_ "GenSigTimeoutTime_PBWM" SG_ 215 PCU_MaxBoostedVoltage 0;
BA_ "GenSigTimeoutTime_IDCM" SG_ 215 PCU_MaxBoostedVoltage 0;
BA_ "GenSigTimeoutTime_ECM" SG_ 215 PCU_MaxBoostedVoltage 0;
BA_ "GenSigTimeoutTime_DMPI" SG_ 215 PCU_MaxBoostedVoltage 0;
BA_ "GenSigTimeoutTime_BPCM" SG_ 215 PCU_MaxBoostedVoltage 0;
BA_ "GenSigTimeoutTime_AGSM" SG_ 215 PCU_MaxBoostedVoltage 0;
BA_ "GenSigTimeoutTime_SGW" SG_ 215 PCU_MIL_Request 0;
BA_ "GenSigTimeoutTime_PBWM" SG_ 215 PCU_MIL_Request 0;
BA_ "GenSigTimeoutTime_IDCM" SG_ 215 PCU_MIL_Request 0;
BA_ "GenSigTimeoutTime_DMPI" SG_ 215 PCU_MIL_Request 0;
BA_ "GenSigTimeoutTime_BPCM" SG_ 215 PCU_MIL_Request 0;
BA_ "GenSigTimeoutTime_AGSM" SG_ 215 PCU_MIL_Request 0;
BA_ "GenSigTimeoutTime_SGW" SG_ 215 PCU_Temporary_Stop_Flag 0;
BA_ "GenSigTimeoutTime_PBWM" SG_ 215 PCU_Temporary_Stop_Flag 0;
BA_ "GenSigTimeoutTime_IDCM" SG_ 215 PCU_Temporary_Stop_Flag 0;
BA_ "GenSigTimeoutTime_ECM" SG_ 215 PCU_Temporary_Stop_Flag 0;
BA_ "GenSigTimeoutTime_DMPI" SG_ 215 PCU_Temporary_Stop_Flag 0;
BA_ "GenSigTimeoutTime_BPCM" SG_ 215 PCU_Temporary_Stop_Flag 0;
BA_ "GenSigTimeoutTime_AGSM" SG_ 215 PCU_Temporary_Stop_Flag 0;
BA_ "GenSigTimeoutTime_SGW" SG_ 215 BoostConverterFailureSts 0;
BA_ "GenSigTimeoutTime_PBWM" SG_ 215 BoostConverterFailureSts 0;
BA_ "GenSigTimeoutTime_IDCM" SG_ 215 BoostConverterFailureSts 0;
BA_ "GenSigTimeoutTime_ECM" SG_ 215 BoostConverterFailureSts 0;
BA_ "GenSigTimeoutTime_DMPI" SG_ 215 BoostConverterFailureSts 0;
BA_ "GenSigTimeoutTime_BPCM" SG_ 215 BoostConverterFailureSts 0;
BA_ "GenSigTimeoutTime_AGSM" SG_ 215 BoostConverterFailureSts 0;
BA_ "GenSigTimeoutTime_DMPI" SG_ 215 Cntr_PCU_FD_1 0;
BA_ "GenSigTimeoutTime_BPCM" SG_ 215 Cntr_PCU_FD_1 0;
BA_ "GenSigTimeoutTime_AGSM" SG_ 215 Cntr_PCU_FD_1 0;
BA_ "GenSigTimeoutTime_SGW" SG_ 215 Cntr_PCU_FD_1 0;
BA_ "GenSigTimeoutTime_PBWM" SG_ 215 Cntr_PCU_FD_1 0;
BA_ "GenSigTimeoutTime_IDCM" SG_ 215 Cntr_PCU_FD_1 0;
BA_ "GenSigTimeoutTime_ECM" SG_ 215 Cntr_PCU_FD_1 0;
BA_ "GenSigTimeoutTime_SGW" SG_ 215 CRC_PCU_FD_1 0;
BA_ "GenSigTimeoutTime_PBWM" SG_ 215 CRC_PCU_FD_1 0;
BA_ "GenSigTimeoutTime_IDCM" SG_ 215 CRC_PCU_FD_1 0;
BA_ "GenSigTimeoutTime_ECM" SG_ 215 CRC_PCU_FD_1 0;
BA_ "GenSigTimeoutTime_DMPI" SG_ 215 CRC_PCU_FD_1 0;
BA_ "GenSigTimeoutTime_BPCM" SG_ 215 CRC_PCU_FD_1 0;
BA_ "GenSigTimeoutTime_AGSM" SG_ 215 CRC_PCU_FD_1 0;
BA_ "GenSigTimeoutTime_SGW" SG_ 215 MAC_PCU_FD_1 0;
BA_ "GenSigTimeoutTime_PBWM" SG_ 215 MAC_PCU_FD_1 0;
BA_ "GenSigTimeoutTime_IDCM" SG_ 215 MAC_PCU_FD_1 0;
BA_ "GenSigTimeoutTime_ECM" SG_ 215 MAC_PCU_FD_1 0;
BA_ "GenSigTimeoutTime_DMPI" SG_ 215 MAC_PCU_FD_1 0;
BA_ "GenSigTimeoutTime_BPCM" SG_ 215 MAC_PCU_FD_1 0;
BA_ "GenSigTimeoutTime_AGSM" SG_ 215 MAC_PCU_FD_1 0;
BA_ "GenSigTimeoutTime_SGW" SG_ 215 MessageCounter_PCU_FD_1 0;
BA_ "GenSigTimeoutTime_PBWM" SG_ 215 MessageCounter_PCU_FD_1 0;
BA_ "GenSigTimeoutTime_IDCM" SG_ 215 MessageCounter_PCU_FD_1 0;
BA_ "GenSigTimeoutTime_ECM" SG_ 215 MessageCounter_PCU_FD_1 0;
BA_ "GenSigTimeoutTime_DMPI" SG_ 215 MessageCounter_PCU_FD_1 0;
BA_ "GenSigTimeoutTime_BPCM" SG_ 215 MessageCounter_PCU_FD_1 0;
BA_ "GenSigTimeoutTime_AGSM" SG_ 215 MessageCounter_PCU_FD_1 0;
BA_ "GenSigTimeoutTime_SGW" SG_ 215 PCU_Diagnostic_Code 0;
BA_ "GenSigTimeoutTime_PBWM" SG_ 215 PCU_Diagnostic_Code 0;
BA_ "GenSigTimeoutTime_IDCM" SG_ 215 PCU_Diagnostic_Code 0;
BA_ "GenSigTimeoutTime_ECM" SG_ 215 PCU_Diagnostic_Code 0;
BA_ "GenSigTimeoutTime_DMPI" SG_ 215 PCU_Diagnostic_Code 0;
BA_ "GenSigTimeoutTime_BPCM" SG_ 215 PCU_Diagnostic_Code 0;
BA_ "GenSigTimeoutTime_AGSM" SG_ 215 PCU_Diagnostic_Code 0;
BA_ "GenSigTimeoutTime_SGW" SG_ 215 PCU_DriveReadyCompletion_Status 0;
BA_ "GenSigTimeoutTime_PBWM" SG_ 215 PCU_DriveReadyCompletion_Status 0;
BA_ "GenSigTimeoutTime_IDCM" SG_ 215 PCU_DriveReadyCompletion_Status 0;
BA_ "GenSigTimeoutTime_ECM" SG_ 215 PCU_DriveReadyCompletion_Status 0;
BA_ "GenSigTimeoutTime_DMPI" SG_ 215 PCU_DriveReadyCompletion_Status 0;
BA_ "GenSigTimeoutTime_BPCM" SG_ 215 PCU_DriveReadyCompletion_Status 0;
BA_ "GenSigTimeoutTime_AGSM" SG_ 215 PCU_DriveReadyCompletion_Status 0;
BA_ "GenSigTimeoutTime_SGW" SG_ 2564682188 N_PDU 0;
BA_ "GenSigTimeoutTime_PBWM" SG_ 2564682188 N_PDU 0;
BA_ "GenSigTimeoutTime_IDCM" SG_ 2564682188 N_PDU 0;
BA_ "GenSigTimeoutTime_EVCU2" SG_ 2564682188 N_PDU 0;
BA_ "GenSigTimeoutTime_ECM" SG_ 2564682188 N_PDU 0;
BA_ "GenSigTimeoutTime_DMPI" SG_ 2564682188 N_PDU 0;
BA_ "GenSigTimeoutTime_BPCM" SG_ 2564682188 N_PDU 0;
BA_ "GenSigTimeoutTime_AGSM" SG_ 2564682188 N_PDU 0;
BA_ "GenSigTimeoutTime_SGW" SG_ 2564485580 N_PDU 0;
BA_ "GenSigTimeoutTime_PBWM" SG_ 2564485580 N_PDU 0;
BA_ "GenSigTimeoutTime_IDCM" SG_ 2564485580 N_PDU 0;
BA_ "GenSigTimeoutTime_EVCU2" SG_ 2564485580 N_PDU 0;
BA_ "GenSigTimeoutTime_ECM" SG_ 2564485580 N_PDU 0;
BA_ "GenSigTimeoutTime_DMPI" SG_ 2564485580 N_PDU 0;
BA_ "GenSigTimeoutTime_BPCM" SG_ 2564485580 N_PDU 0;
BA_ "GenSigTimeoutTime_AGSM" SG_ 2564485580 N_PDU 0;
BA_ "GenSigTimeoutTime_SGW" SG_ 2564682051 N_PDU 0;
BA_ "GenSigTimeoutTime_PBWM" SG_ 2564682051 N_PDU 0;
BA_ "GenSigTimeoutTime_IDCM" SG_ 2564682051 N_PDU 0;
BA_ "GenSigTimeoutTime_EVCU2" SG_ 2564682051 N_PDU 0;
BA_ "GenSigTimeoutTime_ECM" SG_ 2564682051 N_PDU 0;
BA_ "GenSigTimeoutTime_DMPI" SG_ 2564682051 N_PDU 0;
BA_ "GenSigTimeoutTime_BPCM" SG_ 2564682051 N_PDU 0;
BA_ "GenSigTimeoutTime_AGSM" SG_ 2564682051 N_PDU 0;
BA_ "GenSigTimeoutTime_SGW" SG_ 2564682307 N_PDU 0;
BA_ "GenSigTimeoutTime_PBWM" SG_ 2564682307 N_PDU 0;
BA_ "GenSigTimeoutTime_IDCM" SG_ 2564682307 N_PDU 0;
BA_ "GenSigTimeoutTime_EVCU2" SG_ 2564682307 N_PDU 0;
BA_ "GenSigTimeoutTime_ECM" SG_ 2564682307 N_PDU 0;
BA_ "GenSigTimeoutTime_DMPI" SG_ 2564682307 N_PDU 0;
BA_ "GenSigTimeoutTime_BPCM" SG_ 2564682307 N_PDU 0;
BA_ "GenSigTimeoutTime_AGSM" SG_ 2564682307 N_PDU 0;
BA_ "GenSigTimeoutTime_SGW" SG_ 2564682444 N_PDU 0;
BA_ "GenSigTimeoutTime_PBWM" SG_ 2564682444 N_PDU 0;
BA_ "GenSigTimeoutTime_IDCM" SG_ 2564682444 N_PDU 0;
BA_ "GenSigTimeoutTime_EVCU2" SG_ 2564682444 N_PDU 0;
BA_ "GenSigTimeoutTime_ECM" SG_ 2564682444 N_PDU 0;
BA_ "GenSigTimeoutTime_DMPI" SG_ 2564682444 N_PDU 0;
BA_ "GenSigTimeoutTime_BPCM" SG_ 2564682444 N_PDU 0;
BA_ "GenSigTimeoutTime_AGSM" SG_ 2564682444 N_PDU 0;
BA_ "GenSigTimeoutTime_SGW" SG_ 2564485836 N_PDU 0;
BA_ "GenSigTimeoutTime_PBWM" SG_ 2564485836 N_PDU 0;
BA_ "GenSigTimeoutTime_IDCM" SG_ 2564485836 N_PDU 0;
BA_ "GenSigTimeoutTime_EVCU2" SG_ 2564485836 N_PDU 0;
BA_ "GenSigTimeoutTime_ECM" SG_ 2564485836 N_PDU 0;
BA_ "GenSigTimeoutTime_DMPI" SG_ 2564485836 N_PDU 0;
BA_ "GenSigTimeoutTime_BPCM" SG_ 2564485836 N_PDU 0;
BA_ "GenSigTimeoutTime_AGSM" SG_ 2564485836 N_PDU 0;
BA_ "GenSigTimeoutTime_PBWM" SG_ 2654339138 CurrentCanNMState_FD05_DMPI 0;
BA_ "GenSigTimeoutTime_IDCM" SG_ 2654339138 CurrentCanNMState_FD05_DMPI 0;
BA_ "GenSigTimeoutTime_ECM" SG_ 2654339138 CurrentCanNMState_FD05_DMPI 0;
BA_ "GenSigTimeoutTime_DMPI" SG_ 2654339138 CurrentCanNMState_FD05_DMPI 0;
BA_ "GenSigTimeoutTime_BPCM" SG_ 2654339138 CurrentCanNMState_FD05_DMPI 0;
BA_ "GenSigTimeoutTime_AGSM" SG_ 2654339138 CurrentCanNMState_FD05_DMPI 0;
BA_ "GenSigTimeoutTime_PBWM" SG_ 2654339138 CurrentCanNMState_FD11_DMPI 0;
BA_ "GenSigTimeoutTime_IDCM" SG_ 2654339138 CurrentCanNMState_FD11_DMPI 0;
BA_ "GenSigTimeoutTime_ECM" SG_ 2654339138 CurrentCanNMState_FD11_DMPI 0;
BA_ "GenSigTimeoutTime_DMPI" SG_ 2654339138 CurrentCanNMState_FD11_DMPI 0;
BA_ "GenSigTimeoutTime_BPCM" SG_ 2654339138 CurrentCanNMState_FD11_DMPI 0;
BA_ "GenSigTimeoutTime_AGSM" SG_ 2654339138 CurrentCanNMState_FD11_DMPI 0;
BA_ "GenSigTimeoutTime_PBWM" SG_ 2654339138 CurrentFailSts_FD05_DMPI 0;
BA_ "GenSigTimeoutTime_IDCM" SG_ 2654339138 CurrentFailSts_FD05_DMPI 0;
BA_ "GenSigTimeoutTime_ECM" SG_ 2654339138 CurrentFailSts_FD05_DMPI 0;
BA_ "GenSigTimeoutTime_DMPI" SG_ 2654339138 CurrentFailSts_FD05_DMPI 0;
BA_ "GenSigTimeoutTime_BPCM" SG_ 2654339138 CurrentFailSts_FD05_DMPI 0;
BA_ "GenSigTimeoutTime_AGSM" SG_ 2654339138 CurrentFailSts_FD05_DMPI 0;
BA_ "GenSigTimeoutTime_PBWM" SG_ 2654339138 CurrentFailSts_FD11_DMPI 0;
BA_ "GenSigTimeoutTime_IDCM" SG_ 2654339138 CurrentFailSts_FD11_DMPI 0;
BA_ "GenSigTimeoutTime_ECM" SG_ 2654339138 CurrentFailSts_FD11_DMPI 0;
BA_ "GenSigTimeoutTime_DMPI" SG_ 2654339138 CurrentFailSts_FD11_DMPI 0;
BA_ "GenSigTimeoutTime_BPCM" SG_ 2654339138 CurrentFailSts_FD11_DMPI 0;
BA_ "GenSigTimeoutTime_AGSM" SG_ 2654339138 CurrentFailSts_FD11_DMPI 0;
BA_ "GenSigTimeoutTime_PBWM" SG_ 2654339138 DES_FD05_DMPI 0;
BA_ "GenSigTimeoutTime_IDCM" SG_ 2654339138 DES_FD05_DMPI 0;
BA_ "GenSigTimeoutTime_ECM" SG_ 2654339138 DES_FD05_DMPI 0;
BA_ "GenSigTimeoutTime_DMPI" SG_ 2654339138 DES_FD05_DMPI 0;
BA_ "GenSigTimeoutTime_BPCM" SG_ 2654339138 DES_FD05_DMPI 0;
BA_ "GenSigTimeoutTime_AGSM" SG_ 2654339138 DES_FD05_DMPI 0;
BA_ "GenSigTimeoutTime_PBWM" SG_ 2654339138 DES_FD11_DMPI 0;
BA_ "GenSigTimeoutTime_IDCM" SG_ 2654339138 DES_FD11_DMPI 0;
BA_ "GenSigTimeoutTime_ECM" SG_ 2654339138 DES_FD11_DMPI 0;
BA_ "GenSigTimeoutTime_DMPI" SG_ 2654339138 DES_FD11_DMPI 0;
BA_ "GenSigTimeoutTime_BPCM" SG_ 2654339138 DES_FD11_DMPI 0;
BA_ "GenSigTimeoutTime_AGSM" SG_ 2654339138 DES_FD11_DMPI 0;
BA_ "GenSigTimeoutTime_PBWM" SG_ 2654339138 EOL_FD05_DMPI 0;
BA_ "GenSigTimeoutTime_IDCM" SG_ 2654339138 EOL_FD05_DMPI 0;
BA_ "GenSigTimeoutTime_ECM" SG_ 2654339138 EOL_FD05_DMPI 0;
BA_ "GenSigTimeoutTime_DMPI" SG_ 2654339138 EOL_FD05_DMPI 0;
BA_ "GenSigTimeoutTime_BPCM" SG_ 2654339138 EOL_FD05_DMPI 0;
BA_ "GenSigTimeoutTime_AGSM" SG_ 2654339138 EOL_FD05_DMPI 0;
BA_ "GenSigTimeoutTime_PBWM" SG_ 2654339138 EOL_FD11_DMPI 0;
BA_ "GenSigTimeoutTime_IDCM" SG_ 2654339138 EOL_FD11_DMPI 0;
BA_ "GenSigTimeoutTime_ECM" SG_ 2654339138 EOL_FD11_DMPI 0;
BA_ "GenSigTimeoutTime_DMPI" SG_ 2654339138 EOL_FD11_DMPI 0;
BA_ "GenSigTimeoutTime_BPCM" SG_ 2654339138 EOL_FD11_DMPI 0;
BA_ "GenSigTimeoutTime_AGSM" SG_ 2654339138 EOL_FD11_DMPI 0;
BA_ "GenSigTimeoutTime_PBWM" SG_ 2654339138 GenericFailSts_FD05_DMPI 0;
BA_ "GenSigTimeoutTime_IDCM" SG_ 2654339138 GenericFailSts_FD05_DMPI 0;
BA_ "GenSigTimeoutTime_ECM" SG_ 2654339138 GenericFailSts_FD05_DMPI 0;
BA_ "GenSigTimeoutTime_DMPI" SG_ 2654339138 GenericFailSts_FD05_DMPI 0;
BA_ "GenSigTimeoutTime_BPCM" SG_ 2654339138 GenericFailSts_FD05_DMPI 0;
BA_ "GenSigTimeoutTime_AGSM" SG_ 2654339138 GenericFailSts_FD05_DMPI 0;
BA_ "GenSigTimeoutTime_PBWM" SG_ 2654339138 GenericFailSts_FD11_DMPI 0;
BA_ "GenSigTimeoutTime_IDCM" SG_ 2654339138 GenericFailSts_FD11_DMPI 0;
BA_ "GenSigTimeoutTime_ECM" SG_ 2654339138 GenericFailSts_FD11_DMPI 0;
BA_ "GenSigTimeoutTime_DMPI" SG_ 2654339138 GenericFailSts_FD11_DMPI 0;
BA_ "GenSigTimeoutTime_BPCM" SG_ 2654339138 GenericFailSts_FD11_DMPI 0;
BA_ "GenSigTimeoutTime_AGSM" SG_ 2654339138 GenericFailSts_FD11_DMPI 0;
BA_ "GenSigTimeoutTime_PBWM" SG_ 2654339138 PreviousCanNMState_FD05_DMPI 0;
BA_ "GenSigTimeoutTime_IDCM" SG_ 2654339138 PreviousCanNMState_FD05_DMPI 0;
BA_ "GenSigTimeoutTime_ECM" SG_ 2654339138 PreviousCanNMState_FD05_DMPI 0;
BA_ "GenSigTimeoutTime_DMPI" SG_ 2654339138 PreviousCanNMState_FD05_DMPI 0;
BA_ "GenSigTimeoutTime_BPCM" SG_ 2654339138 PreviousCanNMState_FD05_DMPI 0;
BA_ "GenSigTimeoutTime_AGSM" SG_ 2654339138 PreviousCanNMState_FD05_DMPI 0;
BA_ "GenSigTimeoutTime_PBWM" SG_ 2654339138 PreviousCanNMState_FD11_DMPI 0;
BA_ "GenSigTimeoutTime_IDCM" SG_ 2654339138 PreviousCanNMState_FD11_DMPI 0;
BA_ "GenSigTimeoutTime_ECM" SG_ 2654339138 PreviousCanNMState_FD11_DMPI 0;
BA_ "GenSigTimeoutTime_DMPI" SG_ 2654339138 PreviousCanNMState_FD11_DMPI 0;
BA_ "GenSigTimeoutTime_BPCM" SG_ 2654339138 PreviousCanNMState_FD11_DMPI 0;
BA_ "GenSigTimeoutTime_AGSM" SG_ 2654339138 PreviousCanNMState_FD11_DMPI 0;
BA_ "GenSigTimeoutTime_PBWM" SG_ 2654339138 StayActiveSource_FD05_DMPI 0;
BA_ "GenSigTimeoutTime_IDCM" SG_ 2654339138 StayActiveSource_FD05_DMPI 0;
BA_ "GenSigTimeoutTime_ECM" SG_ 2654339138 StayActiveSource_FD05_DMPI 0;
BA_ "GenSigTimeoutTime_DMPI" SG_ 2654339138 StayActiveSource_FD05_DMPI 0;
BA_ "GenSigTimeoutTime_BPCM" SG_ 2654339138 StayActiveSource_FD05_DMPI 0;
BA_ "GenSigTimeoutTime_AGSM" SG_ 2654339138 StayActiveSource_FD05_DMPI 0;
BA_ "GenSigTimeoutTime_PBWM" SG_ 2654339138 StayActiveSource_FD11_DMPI 0;
BA_ "GenSigTimeoutTime_IDCM" SG_ 2654339138 StayActiveSource_FD11_DMPI 0;
BA_ "GenSigTimeoutTime_ECM" SG_ 2654339138 StayActiveSource_FD11_DMPI 0;
BA_ "GenSigTimeoutTime_DMPI" SG_ 2654339138 StayActiveSource_FD11_DMPI 0;
BA_ "GenSigTimeoutTime_BPCM" SG_ 2654339138 StayActiveSource_FD11_DMPI 0;
BA_ "GenSigTimeoutTime_AGSM" SG_ 2654339138 StayActiveSource_FD11_DMPI 0;
BA_ "GenSigTimeoutTime_PBWM" SG_ 2654339138 WakeupSource_FD05_DMPI 0;
BA_ "GenSigTimeoutTime_IDCM" SG_ 2654339138 WakeupSource_FD05_DMPI 0;
BA_ "GenSigTimeoutTime_ECM" SG_ 2654339138 WakeupSource_FD05_DMPI 0;
BA_ "GenSigTimeoutTime_DMPI" SG_ 2654339138 WakeupSource_FD05_DMPI 0;
BA_ "GenSigTimeoutTime_BPCM" SG_ 2654339138 WakeupSource_FD05_DMPI 0;
BA_ "GenSigTimeoutTime_AGSM" SG_ 2654339138 WakeupSource_FD05_DMPI 0;
BA_ "GenSigTimeoutTime_PBWM" SG_ 2654339138 WakeupSource_FD11_DMPI 0;
BA_ "GenSigTimeoutTime_IDCM" SG_ 2654339138 WakeupSource_FD11_DMPI 0;
BA_ "GenSigTimeoutTime_ECM" SG_ 2654339138 WakeupSource_FD11_DMPI 0;
BA_ "GenSigTimeoutTime_DMPI" SG_ 2654339138 WakeupSource_FD11_DMPI 0;
BA_ "GenSigTimeoutTime_BPCM" SG_ 2654339138 WakeupSource_FD11_DMPI 0;
BA_ "GenSigTimeoutTime_AGSM" SG_ 2654339138 WakeupSource_FD11_DMPI 0;
BA_ "GenSigTimeoutTime_DMPI" SG_ 215 BoostConv_UpperIGBT_TempFltd 0;
BA_ "GenSigTimeoutTime_BPCM" SG_ 215 BoostConv_UpperIGBT_TempFltd 0;
BA_ "GenSigTimeoutTime_AGSM" SG_ 215 BoostConv_UpperIGBT_TempFltd 0;
BA_ "GenSigTimeoutTime_SGW" SG_ 215 BoostConv_LowerIGBT_TempFltd 0;
BA_ "GenSigTimeoutTime_PBWM" SG_ 215 BoostConv_LowerIGBT_TempFltd 0;
BA_ "GenSigTimeoutTime_IDCM" SG_ 215 BoostConv_LowerIGBT_TempFltd 0;
BA_ "GenSigTimeoutTime_ECM" SG_ 215 BoostConv_LowerIGBT_TempFltd 0;
BA_ "GenSigTimeoutTime_DMPI" SG_ 215 BoostConv_LowerIGBT_TempFltd 0;
BA_ "GenSigTimeoutTime_BPCM" SG_ 215 BoostConv_LowerIGBT_TempFltd 0;
BA_ "GenSigTimeoutTime_AGSM" SG_ 215 BoostConv_LowerIGBT_TempFltd 0;
BA_ "GenSigTimeoutTime_SGW" SG_ 215 BoostConv_ReactorTemp 0;
BA_ "GenSigTimeoutTime_PBWM" SG_ 215 BoostConv_ReactorTemp 0;
BA_ "GenSigTimeoutTime_IDCM" SG_ 215 BoostConv_ReactorTemp 0;
BA_ "GenSigTimeoutTime_ECM" SG_ 215 BoostConv_ReactorTemp 0;
BA_ "GenSigTimeoutTime_DMPI" SG_ 215 BoostConv_ReactorTemp 0;
BA_ "GenSigTimeoutTime_BPCM" SG_ 215 BoostConv_ReactorTemp 0;
BA_ "GenSigTimeoutTime_AGSM" SG_ 215 BoostConv_ReactorTemp 0;
BA_ "GenSigTimeoutTime_SGW" SG_ 2654486588 CBV_bit0_RepeatMessageRequestBit 0;
BA_ "GenSigTimeoutTime_PBWM" SG_ 2654486588 CBV_bit0_RepeatMessageRequestBit 0;
BA_ "GenSigTimeoutTime_IDCM" SG_ 2654486588 CBV_bit0_RepeatMessageRequestBit 0;
BA_ "GenSigTimeoutTime_EVCU2" SG_ 2654486588 CBV_bit0_RepeatMessageRequestBit 0;
BA_ "GenSigTimeoutTime_ECM" SG_ 2654486588 CBV_bit0_RepeatMessageRequestBit 0;
BA_ "GenSigTimeoutTime_DMPI" SG_ 2654486588 CBV_bit0_RepeatMessageRequestBit 0;
BA_ "GenSigTimeoutTime_BPCM" SG_ 2654486588 CBV_bit0_RepeatMessageRequestBit 0;
BA_ "GenSigTimeoutTime_AGSM" SG_ 2654486588 CBV_bit0_RepeatMessageRequestBit 0;
BA_ "GenSigTimeoutTime_SGW" SG_ 2654486588 CBV_bit1 0;
BA_ "GenSigTimeoutTime_PBWM" SG_ 2654486588 CBV_bit1 0;
BA_ "GenSigTimeoutTime_IDCM" SG_ 2654486588 CBV_bit1 0;
BA_ "GenSigTimeoutTime_EVCU2" SG_ 2654486588 CBV_bit1 0;
BA_ "GenSigTimeoutTime_ECM" SG_ 2654486588 CBV_bit1 0;
BA_ "GenSigTimeoutTime_DMPI" SG_ 2654486588 CBV_bit1 0;
BA_ "GenSigTimeoutTime_BPCM" SG_ 2654486588 CBV_bit1 0;
BA_ "GenSigTimeoutTime_AGSM" SG_ 2654486588 CBV_bit1 0;
BA_ "GenSigTimeoutTime_SGW" SG_ 2654486588 CBV_bit4_ActiveWakeupBit 0;
BA_ "GenSigTimeoutTime_PBWM" SG_ 2654486588 CBV_bit4_ActiveWakeupBit 0;
BA_ "GenSigTimeoutTime_IDCM" SG_ 2654486588 CBV_bit4_ActiveWakeupBit 0;
BA_ "GenSigTimeoutTime_EVCU2" SG_ 2654486588 CBV_bit4_ActiveWakeupBit 0;
BA_ "GenSigTimeoutTime_ECM" SG_ 2654486588 CBV_bit4_ActiveWakeupBit 0;
BA_ "GenSigTimeoutTime_DMPI" SG_ 2654486588 CBV_bit4_ActiveWakeupBit 0;
BA_ "GenSigTimeoutTime_BPCM" SG_ 2654486588 CBV_bit4_ActiveWakeupBit 0;
BA_ "GenSigTimeoutTime_AGSM" SG_ 2654486588 CBV_bit4_ActiveWakeupBit 0;
BA_ "GenSigTimeoutTime_SGW" SG_ 2654486588 CBV_bit3_NMCoordinatorBit 0;
BA_ "GenSigTimeoutTime_PBWM" SG_ 2654486588 CBV_bit3_NMCoordinatorBit 0;
BA_ "GenSigTimeoutTime_IDCM" SG_ 2654486588 CBV_bit3_NMCoordinatorBit 0;
BA_ "GenSigTimeoutTime_EVCU2" SG_ 2654486588 CBV_bit3_NMCoordinatorBit 0;
BA_ "GenSigTimeoutTime_ECM" SG_ 2654486588 CBV_bit3_NMCoordinatorBit 0;
BA_ "GenSigTimeoutTime_DMPI" SG_ 2654486588 CBV_bit3_NMCoordinatorBit 0;
BA_ "GenSigTimeoutTime_BPCM" SG_ 2654486588 CBV_bit3_NMCoordinatorBit 0;
BA_ "GenSigTimeoutTime_AGSM" SG_ 2654486588 CBV_bit3_NMCoordinatorBit 0;
BA_ "GenSigTimeoutTime_SGW" SG_ 2654486588 CBV_bit2 0;
BA_ "GenSigTimeoutTime_PBWM" SG_ 2654486588 CBV_bit2 0;
BA_ "GenSigTimeoutTime_IDCM" SG_ 2654486588 CBV_bit2 0;
BA_ "GenSigTimeoutTime_EVCU2" SG_ 2654486588 CBV_bit2 0;
BA_ "GenSigTimeoutTime_ECM" SG_ 2654486588 CBV_bit2 0;
BA_ "GenSigTimeoutTime_DMPI" SG_ 2654486588 CBV_bit2 0;
BA_ "GenSigTimeoutTime_BPCM" SG_ 2654486588 CBV_bit2 0;
BA_ "GenSigTimeoutTime_AGSM" SG_ 2654486588 CBV_bit2 0;
BA_ "GenSigTimeoutTime_SGW" SG_ 2654486588 CBV_bit7 0;
BA_ "GenSigTimeoutTime_PBWM" SG_ 2654486588 CBV_bit7 0;
BA_ "GenSigTimeoutTime_IDCM" SG_ 2654486588 CBV_bit7 0;
BA_ "GenSigTimeoutTime_EVCU2" SG_ 2654486588 CBV_bit7 0;
BA_ "GenSigTimeoutTime_ECM" SG_ 2654486588 CBV_bit7 0;
BA_ "GenSigTimeoutTime_DMPI" SG_ 2654486588 CBV_bit7 0;
BA_ "GenSigTimeoutTime_BPCM" SG_ 2654486588 CBV_bit7 0;
BA_ "GenSigTimeoutTime_AGSM" SG_ 2654486588 CBV_bit7 0;
BA_ "GenSigTimeoutTime_SGW" SG_ 2654486588 SourceNodeIdentifier 0;
BA_ "GenSigTimeoutTime_PBWM" SG_ 2654486588 SourceNodeIdentifier 0;
BA_ "GenSigTimeoutTime_IDCM" SG_ 2654486588 SourceNodeIdentifier 0;
BA_ "GenSigTimeoutTime_EVCU2" SG_ 2654486588 SourceNodeIdentifier 0;
BA_ "GenSigTimeoutTime_ECM" SG_ 2654486588 SourceNodeIdentifier 0;
BA_ "GenSigTimeoutTime_DMPI" SG_ 2654486588 SourceNodeIdentifier 0;
BA_ "GenSigTimeoutTime_BPCM" SG_ 2654486588 SourceNodeIdentifier 0;
BA_ "GenSigTimeoutTime_AGSM" SG_ 2654486588 SourceNodeIdentifier 0;
BA_ "GenSigTimeoutTime_SGW" SG_ 2654486588 CBV_bit6_PartialNtwInfBit 0;
BA_ "GenSigTimeoutTime_PBWM" SG_ 2654486588 CBV_bit6_PartialNtwInfBit 0;
BA_ "GenSigTimeoutTime_IDCM" SG_ 2654486588 CBV_bit6_PartialNtwInfBit 0;
BA_ "GenSigTimeoutTime_EVCU2" SG_ 2654486588 CBV_bit6_PartialNtwInfBit 0;
BA_ "GenSigTimeoutTime_ECM" SG_ 2654486588 CBV_bit6_PartialNtwInfBit 0;
BA_ "GenSigTimeoutTime_DMPI" SG_ 2654486588 CBV_bit6_PartialNtwInfBit 0;
BA_ "GenSigTimeoutTime_BPCM" SG_ 2654486588 CBV_bit6_PartialNtwInfBit 0;
BA_ "GenSigTimeoutTime_AGSM" SG_ 2654486588 CBV_bit6_PartialNtwInfBit 0;
BA_ "GenSigTimeoutTime_SGW" SG_ 2654486588 CBV_bit5 0;
BA_ "GenSigTimeoutTime_PBWM" SG_ 2654486588 CBV_bit5 0;
BA_ "GenSigTimeoutTime_IDCM" SG_ 2654486588 CBV_bit5 0;
BA_ "GenSigTimeoutTime_EVCU2" SG_ 2654486588 CBV_bit5 0;
BA_ "GenSigTimeoutTime_ECM" SG_ 2654486588 CBV_bit5 0;
BA_ "GenSigTimeoutTime_DMPI" SG_ 2654486588 CBV_bit5 0;
BA_ "GenSigTimeoutTime_BPCM" SG_ 2654486588 CBV_bit5 0;
BA_ "GenSigTimeoutTime_AGSM" SG_ 2654486588 CBV_bit5 0;
BA_ "GenSigTimeoutTime_AGSM" SG_ 2654486594 CBV_bit4_ActiveWakeupBit 0;
BA_ "GenSigTimeoutTime_SGW" SG_ 2654486594 CBV_bit4_ActiveWakeupBit 0;
BA_ "GenSigTimeoutTime_PBWM" SG_ 2654486594 CBV_bit4_ActiveWakeupBit 0;
BA_ "GenSigTimeoutTime_IDCM" SG_ 2654486594 CBV_bit4_ActiveWakeupBit 0;
BA_ "GenSigTimeoutTime_EVCU2" SG_ 2654486594 CBV_bit4_ActiveWakeupBit 0;
BA_ "GenSigTimeoutTime_ECM" SG_ 2654486594 CBV_bit4_ActiveWakeupBit 0;
BA_ "GenSigTimeoutTime_DMPI" SG_ 2654486594 CBV_bit4_ActiveWakeupBit 0;
BA_ "GenSigTimeoutTime_BPCM" SG_ 2654486594 CBV_bit4_ActiveWakeupBit 0;
BA_ "GenSigTimeoutTime_SGW" SG_ 2654486594 CBV_bit5 0;
BA_ "GenSigTimeoutTime_PBWM" SG_ 2654486594 CBV_bit5 0;
BA_ "GenSigTimeoutTime_IDCM" SG_ 2654486594 CBV_bit5 0;
BA_ "GenSigTimeoutTime_EVCU2" SG_ 2654486594 CBV_bit5 0;
BA_ "GenSigTimeoutTime_ECM" SG_ 2654486594 CBV_bit5 0;
BA_ "GenSigTimeoutTime_DMPI" SG_ 2654486594 CBV_bit5 0;
BA_ "GenSigTimeoutTime_BPCM" SG_ 2654486594 CBV_bit5 0;
BA_ "GenSigTimeoutTime_AGSM" SG_ 2654486594 CBV_bit5 0;
BA_ "GenSigTimeoutTime_SGW" SG_ 2654486594 CBV_bit7 0;
BA_ "GenSigTimeoutTime_PBWM" SG_ 2654486594 CBV_bit7 0;
BA_ "GenSigTimeoutTime_IDCM" SG_ 2654486594 CBV_bit7 0;
BA_ "GenSigTimeoutTime_EVCU2" SG_ 2654486594 CBV_bit7 0;
BA_ "GenSigTimeoutTime_ECM" SG_ 2654486594 CBV_bit7 0;
BA_ "GenSigTimeoutTime_DMPI" SG_ 2654486594 CBV_bit7 0;
BA_ "GenSigTimeoutTime_BPCM" SG_ 2654486594 CBV_bit7 0;
BA_ "GenSigTimeoutTime_AGSM" SG_ 2654486594 CBV_bit7 0;
BA_ "GenSigTimeoutTime_SGW" SG_ 2654486594 CBV_bit6_PartialNtwInfBit 0;
BA_ "GenSigTimeoutTime_PBWM" SG_ 2654486594 CBV_bit6_PartialNtwInfBit 0;
BA_ "GenSigTimeoutTime_IDCM" SG_ 2654486594 CBV_bit6_PartialNtwInfBit 0;
BA_ "GenSigTimeoutTime_EVCU2" SG_ 2654486594 CBV_bit6_PartialNtwInfBit 0;
BA_ "GenSigTimeoutTime_ECM" SG_ 2654486594 CBV_bit6_PartialNtwInfBit 0;
BA_ "GenSigTimeoutTime_DMPI" SG_ 2654486594 CBV_bit6_PartialNtwInfBit 0;
BA_ "GenSigTimeoutTime_BPCM" SG_ 2654486594 CBV_bit6_PartialNtwInfBit 0;
BA_ "GenSigTimeoutTime_AGSM" SG_ 2654486594 CBV_bit6_PartialNtwInfBit 0;
BA_ "GenSigTimeoutTime_SGW" SG_ 2654486594 SourceNodeIdentifier 0;
BA_ "GenSigTimeoutTime_PBWM" SG_ 2654486594 SourceNodeIdentifier 0;
BA_ "GenSigTimeoutTime_IDCM" SG_ 2654486594 SourceNodeIdentifier 0;
BA_ "GenSigTimeoutTime_EVCU2" SG_ 2654486594 SourceNodeIdentifier 0;
BA_ "GenSigTimeoutTime_ECM" SG_ 2654486594 SourceNodeIdentifier 0;
BA_ "GenSigTimeoutTime_DMPI" SG_ 2654486594 SourceNodeIdentifier 0;
BA_ "GenSigTimeoutTime_BPCM" SG_ 2654486594 SourceNodeIdentifier 0;
BA_ "GenSigTimeoutTime_AGSM" SG_ 2654486594 SourceNodeIdentifier 0;
BA_ "GenSigTimeoutTime_SGW" SG_ 2654486594 CBV_bit2 0;
BA_ "GenSigTimeoutTime_PBWM" SG_ 2654486594 CBV_bit2 0;
BA_ "GenSigTimeoutTime_IDCM" SG_ 2654486594 CBV_bit2 0;
BA_ "GenSigTimeoutTime_EVCU2" SG_ 2654486594 CBV_bit2 0;
BA_ "GenSigTimeoutTime_ECM" SG_ 2654486594 CBV_bit2 0;
BA_ "GenSigTimeoutTime_DMPI" SG_ 2654486594 CBV_bit2 0;
BA_ "GenSigTimeoutTime_BPCM" SG_ 2654486594 CBV_bit2 0;
BA_ "GenSigTimeoutTime_AGSM" SG_ 2654486594 CBV_bit2 0;
BA_ "GenSigTimeoutTime_SGW" SG_ 2654486594 CBV_bit3_NMCoordinatorBit 0;
BA_ "GenSigTimeoutTime_PBWM" SG_ 2654486594 CBV_bit3_NMCoordinatorBit 0;
BA_ "GenSigTimeoutTime_IDCM" SG_ 2654486594 CBV_bit3_NMCoordinatorBit 0;
BA_ "GenSigTimeoutTime_EVCU2" SG_ 2654486594 CBV_bit3_NMCoordinatorBit 0;
BA_ "GenSigTimeoutTime_ECM" SG_ 2654486594 CBV_bit3_NMCoordinatorBit 0;
BA_ "GenSigTimeoutTime_DMPI" SG_ 2654486594 CBV_bit3_NMCoordinatorBit 0;
BA_ "GenSigTimeoutTime_BPCM" SG_ 2654486594 CBV_bit3_NMCoordinatorBit 0;
BA_ "GenSigTimeoutTime_AGSM" SG_ 2654486594 CBV_bit3_NMCoordinatorBit 0;
BA_ "GenSigTimeoutTime_SGW" SG_ 2654486594 CBV_bit1 0;
BA_ "GenSigTimeoutTime_PBWM" SG_ 2654486594 CBV_bit1 0;
BA_ "GenSigTimeoutTime_IDCM" SG_ 2654486594 CBV_bit1 0;
BA_ "GenSigTimeoutTime_EVCU2" SG_ 2654486594 CBV_bit1 0;
BA_ "GenSigTimeoutTime_ECM" SG_ 2654486594 CBV_bit1 0;
BA_ "GenSigTimeoutTime_DMPI" SG_ 2654486594 CBV_bit1 0;
BA_ "GenSigTimeoutTime_BPCM" SG_ 2654486594 CBV_bit1 0;
BA_ "GenSigTimeoutTime_AGSM" SG_ 2654486594 CBV_bit1 0;
BA_ "GenSigTimeoutTime_SGW" SG_ 2654486594 CBV_bit0_RepeatMessageRequestBit 0;
BA_ "GenSigTimeoutTime_PBWM" SG_ 2654486594 CBV_bit0_RepeatMessageRequestBit 0;
BA_ "GenSigTimeoutTime_IDCM" SG_ 2654486594 CBV_bit0_RepeatMessageRequestBit 0;
BA_ "GenSigTimeoutTime_EVCU2" SG_ 2654486594 CBV_bit0_RepeatMessageRequestBit 0;
BA_ "GenSigTimeoutTime_ECM" SG_ 2654486594 CBV_bit0_RepeatMessageRequestBit 0;
BA_ "GenSigTimeoutTime_DMPI" SG_ 2654486594 CBV_bit0_RepeatMessageRequestBit 0;
BA_ "GenSigTimeoutTime_BPCM" SG_ 2654486594 CBV_bit0_RepeatMessageRequestBit 0;
BA_ "GenSigTimeoutTime_AGSM" SG_ 2654486594 CBV_bit0_RepeatMessageRequestBit 0;
BA_ "GenSigTimeoutTime_SGW" SG_ 504 MC_MCPB_STATUS 0;
BA_ "GenSigTimeoutTime_PBWM" SG_ 504 MC_MCPB_STATUS 0;
BA_ "GenSigTimeoutTime_IDCM" SG_ 504 MC_MCPB_STATUS 0;
BA_ "GenSigTimeoutTime_EVCU2" SG_ 504 MC_MCPB_STATUS 0;
BA_ "GenSigTimeoutTime_ECM" SG_ 504 MC_MCPB_STATUS 0;
BA_ "GenSigTimeoutTime_DMPI" SG_ 504 MC_MCPB_STATUS 0;
BA_ "GenSigTimeoutTime_AGSM" SG_ 504 MC_MCPB_STATUS 0;
BA_ "GenSigTimeoutTime_SGW" SG_ 504 MCPB_DC_Current_P 0;
BA_ "GenSigTimeoutTime_PBWM" SG_ 504 MCPB_DC_Current_P 0;
BA_ "GenSigTimeoutTime_IDCM" SG_ 504 MCPB_DC_Current_P 0;
BA_ "GenSigTimeoutTime_EVCU2" SG_ 504 MCPB_DC_Current_P 0;
BA_ "GenSigTimeoutTime_ECM" SG_ 504 MCPB_DC_Current_P 0;
BA_ "GenSigTimeoutTime_DMPI" SG_ 504 MCPB_DC_Current_P 0;
BA_ "GenSigTimeoutTime_AGSM" SG_ 504 MCPB_DC_Current_P 0;
BA_ "GenSigStartValue" SG_ 504 MCPB_DC_Current_P 16384;
BA_ "GenSigTimeoutTime_SGW" SG_ 503 CRC_MCPA_STATUS 0;
BA_ "GenSigTimeoutTime_PBWM" SG_ 503 CRC_MCPA_STATUS 0;
BA_ "GenSigTimeoutTime_IDCM" SG_ 503 CRC_MCPA_STATUS 0;
BA_ "GenSigTimeoutTime_EVCU2" SG_ 503 CRC_MCPA_STATUS 0;
BA_ "GenSigTimeoutTime_ECM" SG_ 503 CRC_MCPA_STATUS 0;
BA_ "GenSigTimeoutTime_DMPI" SG_ 503 CRC_MCPA_STATUS 0;
BA_ "GenSigTimeoutTime_AGSM" SG_ 503 CRC_MCPA_STATUS 0;
BA_ "GenSigTimeoutTime_SGW" SG_ 503 MC_MCPA_STATUS 0;
BA_ "GenSigTimeoutTime_PBWM" SG_ 503 MC_MCPA_STATUS 0;
BA_ "GenSigTimeoutTime_IDCM" SG_ 503 MC_MCPA_STATUS 0;
BA_ "GenSigTimeoutTime_EVCU2" SG_ 503 MC_MCPA_STATUS 0;
BA_ "GenSigTimeoutTime_ECM" SG_ 503 MC_MCPA_STATUS 0;
BA_ "GenSigTimeoutTime_DMPI" SG_ 503 MC_MCPA_STATUS 0;
VAL_ 2654486594 CBV_bit6_PartialNtwInfBit 0 "NM PDU contains no Partial Network request information" 1 "NM PDU contains Partial Network request information";
VAL_ 2654486588 CBV_bit6_PartialNtwInfBit 0 "NM PDU contains no Partial Network request information" 1 "NM PDU contains Partial Network request information";
VAL_ 2654486588 CBV_bit4_ActiveWakeupBit 0 "PassiveWakeup" 1 "ActiveWakeup";
VAL_ 2654486594 CBV_bit4_ActiveWakeupBit 0 "PassiveWakeup" 1 "ActiveWakeup";
VAL_ 2654486588 CBV_bit3_NMCoordinatorBit 0 "Start of synchronized shutdown is not requested by main coordinator" 1 "Start of synchronized shutdown is requested by main coordinator";
VAL_ 2654486594 CBV_bit3_NMCoordinatorBit 0 "Start of synchronized shutdown is not requested by main coordinator" 1 "Start of synchronized shutdown is requested by main coordinator";
VAL_ 2654486594 CBV_bit0_RepeatMessageRequestBit 0 "Repeat Message State not requested" 1 "Repeat Message State requested";
VAL_ 2654486588 CBV_bit0_RepeatMessageRequestBit 0 "Repeat Message State not requested" 1 "Repeat Message State requested";
VAL_ 2654339132 WakeupSource_FD11_PBWM 0 "No_Wakeup";
VAL_ 2654339132 WakeupSource_FD05_PBWM 0 "No_Wakeup";
VAL_ 2654339132 StayActiveSource_FD11_PBWM 0 "CANNM_Ready_Sleep" 1 "IGN_ON" 2 "NonDefault_Diag" 4 "ING_OFF_NormSt_RptSt" 8 "HV_ON" 1073741824 "SASource_Not_Listed";
VAL_ 2654339132 PreviousCanNMState_FD11_PBWM 0 "Uninitialized State" 1 "Bus-Sleep State" 2 "Prepare-Bus State" 3 "Ready-Sleep State" 4 "Normal Operation State" 5 "Repeat Message State" 6 "Synchronize State" 7 "Offline State";
VAL_ 2654339132 PreviousCanNMState_FD05_PBWM 0 "Uninitialized State" 1 "Bus-Sleep State" 2 "Prepare-Bus State" 3 "Ready-Sleep State" 4 "Normal Operation State" 5 "Repeat Message State" 6 "Synchronize State" 7 "Offline State";
VAL_ 2654339132 GenericFailSts_FD11_PBWM 0 "No_Fail_Present" 1 "Fail_Present";
VAL_ 2654339132 GenericFailSts_FD05_PBWM 0 "No_Fail_Present" 1 "Fail_Present";
VAL_ 2654339132 EOL_FD11_PBWM 0 "No_EOL_Programming" 1 "EOL_Programming";
VAL_ 2654339132 EOL_FD05_PBWM 0 "No_EOL_Programming" 1 "EOL_Programming";
VAL_ 2654339132 DES_FD11_PBWM 0 "Error_Active_state" 1 "Error_passive_warning_state" 2 "Bus_off_state" 3 "Not_used";
VAL_ 2654339132 DES_FD05_PBWM 0 "Error_Active_state" 1 "Error_passive_warning_state" 2 "Bus_off_state" 3 "Not_used";
VAL_ 2654339132 CurrentFailSts_FD11_PBWM 0 "No_Fail_Present" 1 "Fail_Present";
VAL_ 2654339132 CurrentFailSts_FD05_PBWM 0 "No_Fail_Present" 1 "Fail_Present";
VAL_ 2654339132 CurrentCanNMState_FD11_PBWM 0 "Uninitialized State" 1 "Bus-Sleep State" 2 "Prepare-Bus State" 3 "Ready-Sleep State" 4 "Normal Operation State" 5 "Repeat Message State" 6 "Synchronize State" 7 "Offline State";
VAL_ 2654339132 CurrentCanNMState_FD05_PBWM 0 "Uninitialized State" 1 "Bus-Sleep State" 2 "Prepare-Bus State" 3 "Ready-Sleep State" 4 "Normal Operation State" 5 "Repeat Message State" 6 "Synchronize State" 7 "Offline State";
VAL_ 2654339138 WakeupSource_FD11_DMPI 0 "No_Wakeup";
VAL_ 2654339138 WakeupSource_FD05_DMPI 0 "No_Wakeup";
VAL_ 2654339138 StayActiveSource_FD11_DMPI 0 "CANNM_Ready_Sleep" 1 "IGN_ON" 2 "NonDefault_Diag" 4 "ING_OFF_NormSt_RptSt" 8 "HV_ON" 1073741824 "SASource_Not_Listed";
VAL_ 2654339138 PreviousCanNMState_FD11_DMPI 0 "Uninitialized State" 1 "Bus-Sleep State" 2 "Prepare-Bus State" 3 "Ready-Sleep State" 4 "Normal Operation State" 5 "Repeat Message State" 6 "Synchronize State" 7 "Offline State";
VAL_ 2654339138 PreviousCanNMState_FD05_DMPI 0 "Uninitialized State" 1 "Bus-Sleep State" 2 "Prepare-Bus State" 3 "Ready-Sleep State" 4 "Normal Operation State" 5 "Repeat Message State" 6 "Synchronize State" 7 "Offline State";
VAL_ 2654339138 GenericFailSts_FD11_DMPI 0 "No_Fail_Present" 1 "Fail_Present";
VAL_ 2654339138 GenericFailSts_FD05_DMPI 0 "No_Fail_Present" 1 "Fail_Present";
VAL_ 2654339138 EOL_FD11_DMPI 0 "No_EOL_Programming" 1 "EOL_Programming";
VAL_ 2654339138 EOL_FD05_DMPI 0 "No_EOL_Programming" 1 "EOL_Programming";
VAL_ 2654339138 DES_FD11_DMPI 0 "Error_Active_state" 1 "Error_passive_warning_state" 2 "Bus_off_state" 3 "Not_used";
VAL_ 2654339138 DES_FD05_DMPI 0 "Error_Active_state" 1 "Error_passive_warning_state" 2 "Bus_off_state" 3 "Not_used";
VAL_ 2654339138 CurrentFailSts_FD11_DMPI 0 "No_Fail_Present" 1 "Fail_Present";
VAL_ 2654339138 CurrentFailSts_FD05_DMPI 0 "No_Fail_Present" 1 "Fail_Present";
VAL_ 2654339138 CurrentCanNMState_FD11_DMPI 0 "Uninitialized State" 1 "Bus-Sleep State" 2 "Prepare-Bus State" 3 "Ready-Sleep State" 4 "Normal Operation State" 5 "Repeat Message State" 6 "Synchronize State" 7 "Offline State";
VAL_ 2654339138 CurrentCanNMState_FD05_DMPI 0 "Uninitialized State" 1 "Bus-Sleep State" 2 "Prepare-Bus State" 3 "Ready-Sleep State" 4 "Normal Operation State" 5 "Repeat Message State" 6 "Synchronize State" 7 "Offline State";
VAL_ 1811 Real_Time_Validity 0 "Valid" 1 "Not_Valid";
VAL_ 1811 Real_Time_Clock 4294967295 "SNA";
VAL_ 212 PIM_B_Torque_Achieved_V 0 "Valid" 1 "Invalid";
VAL_ 212 PIM_B_TorqAchieved_AEMD_V 0 "Valid" 1 "Invalid";
VAL_ 212 PIM_B_SPT_Stat 0 "Undetermined " 1 "Passed" 2 "Failed";
VAL_ 212 PIM_B_RPM_V 0 "Valid" 1 "Invalid";
VAL_ 212 PIM_B_MtrMinCpbltyTrq 8191 "SNA";
VAL_ 212 PIM_B_MtrMaxCpbltyTrq 8191 "SNA";
VAL_ 212 PIM_B_MtrIndex 31 "SNA";
VAL_ 212 PIM_B_MinTorq 8191 "SNA";
VAL_ 212 PIM_B_MaxTorq 8191 "SNA";
VAL_ 212 PIM_B_Invrtr_State 0 "NORMAL_POWER_STAGE_OFF " 1 "NORMAL_POWER_STAGE_ON " 2 "NORMAL_POWER_STAGE_OVERRIDE" 3 "ACTIVE_DISCHARGE " 4 "INVERTER_FAULTED " 5 "NORMAL_POWER_STAGE_OFF_HV_RQD" 6 "NORMAL_VC_PRIMING" 7 "NORMAL_VC_ON";
VAL_ 212 PIM_B_InterlockSts 0 "Not_Performed" 1 "OK" 2 "Fail" 3 "Invalid";
VAL_ 212 PIM_B_HV_CnctrOpn_Req 0 "False" 1 "True";
VAL_ 212 PIM_B_Dschrge_Status 0 "AD_INDETERMINATE" 1 "AD_INPROGRESS" 2 "AD_COMPLETE" 3 "AD_FAILED";
VAL_ 212 PIM_B_DeratingFactor 63 "SNA";
VAL_ 212 PIM_B_DerateReason 0 "Reason1" 1 "Reason2" 2 "Reason3" 3 "Reason4" 4 "Reason5" 5 "Reason6" 6 "Reason7" 7 "Reason8" 8 "Reason9" 9 "Reason10" 10 "Reason11" 11 "Reason12" 12 "Reason13" 13 "Reason14" 14 "Reason15" 15 "Reason16";
VAL_ 212 PIM_B_DC_Voltage 1023 "SNA";
VAL_ 212 PIM_B_DC_Volt_V 0 "Valid" 1 "Invalid";
VAL_ 212 PIM_B_DC_Current_V 0 "Valid" 1 "Invalid";
VAL_ 212 PIM_B_CpbltySpdDivVolt 65535 "SNA";
VAL_ 212 PIM_B_CoolantTemp 2047 "SNA";
VAL_ 212 PIM_B_AccelRawV 0 "Valid" 1 "Invalid";
VAL_ 212 PIM_B_6SO_Status 0 "3PS" 1 "6SO" 2 "Switching" 3 "SNA";
VAL_ 212 PIM_B_3PS_Pos 0 "False" 1 "True";
VAL_ 211 PIM_A_Torque_Achieved_V 0 "Valid" 1 "Invalid";
VAL_ 211 PIM_A_TorqAchieved_AEMD_V 0 "Valid" 1 "Invalid";
VAL_ 211 PIM_A_SPT_Stat 0 "Undetermined " 1 "Passed" 2 "Failed";
VAL_ 211 PIM_A_RPM_V 0 "Valid" 1 "Invalid";
VAL_ 211 PIM_A_MtrMinCpbltyTrq 8191 "SNA";
VAL_ 211 PIM_A_MtrMaxCpbltyTrq 8191 "SNA";
VAL_ 211 PIM_A_MtrIndex 31 "SNA";
VAL_ 211 PIM_A_MinTorq 8191 "SNA";
VAL_ 211 PIM_A_MaxTorq 8191 "SNA";
VAL_ 211 PIM_A_Invrtr_State 0 "NORMAL_POWER_STAGE_OFF " 1 "NORMAL_POWER_STAGE_ON " 2 "NORMAL_POWER_STAGE_OVERRIDE" 3 "ACTIVE_DISCHARGE " 4 "INVERTER_FAULTED " 5 "NORMAL_POWER_STAGE_OFF_HV_RQD" 6 "NORMAL_VC_PRIMING" 7 "NORMAL_VC_ON";
VAL_ 211 PIM_A_InterlockSts 0 "Not_Performed" 1 "OK" 2 "Fail" 3 "Invalid";
VAL_ 211 PIM_A_HV_CnctrOpn_Req 0 "False" 1 "True";
VAL_ 211 PIM_A_Dschrge_Status 0 "AD_INDETERMINATE" 1 "AD_INPROGRESS" 2 "AD_COMPLETE" 3 "AD_FAILED";
VAL_ 211 PIM_A_DeratingFactor 63 "SNA";
VAL_ 211 PIM_A_DerateReason 0 "Reason1" 1 "Reason2" 2 "Reason3" 3 "Reason4" 4 "Reason5" 5 "Reason6" 6 "Reason7" 7 "Reason8" 8 "Reason9" 9 "Reason10" 10 "Reason11" 11 "Reason12" 12 "Reason13" 13 "Reason14" 14 "Reason15" 15 "Reason16";
VAL_ 211 PIM_A_DC_Voltage 1023 "SNA";
VAL_ 211 PIM_A_DC_Volt_V 0 "Valid" 1 "Invalid";
VAL_ 211 PIM_A_DC_Current_V 0 "Valid" 1 "Invalid";
VAL_ 211 PIM_A_CpbltySpdDivVolt 65535 "SNA";
VAL_ 211 PIM_A_CoolantTemp 2047 "SNA";
VAL_ 211 PIM_A_AccelRawV 0 "Valid" 1 "Invalid";
VAL_ 211 PIM_A_6SO_Status 0 "3PS" 1 "6SO" 2 "Switching" 3 "1PS";
VAL_ 211 PIM_A_3PS_Pos 0 "False" 1 "True";
VAL_ 215 Pinion_OverspeedWarning 0 "False" 1 "True";
VAL_ 215 PCU_Temporary_Stop_Flag 0 "No_Request" 1 "Temporary_Stop_Request";
VAL_ 215 PCU_MIL_Request 0 "NO_MIL_Request" 1 "MIL_Request";
VAL_ 215 PCU_MaxBoostedVoltage 1023 "SNA";
VAL_ 215 PCU_Max_DischargePowerLmt 16383 "SNA";
VAL_ 215 PCU_Max_ChargePowerLmt 16383 "SNA";
VAL_ 215 PCU_DriveReadyCompletion_Status 0 "Not_ready" 1 "Ready";
VAL_ 215 PCU_Diagnostic_Code 65535 "SNA";
VAL_ 215 BoostConverterFailureSts 0 "Normal" 1 "Faulted" 2 "Power_Limitation" 3 "Voltage_Limitation";
VAL_ 215 BoostConverter_Current 32767 "SNA";
VAL_ 215 BoostConv_UpperIGBT_TempFltd 4095 "SNA";
VAL_ 215 BoostConv_ReactorTemp 4095 "SNA";
VAL_ 215 BoostConv_LowerIGBT_TempFltd 4095 "SNA";
VAL_ 214 Mtr_6SO_Request_MCPB_2 0 "False" 1 "True";
VAL_ 214 Mtr_6SO_Request_MCPA_2 0 "False" 1 "True";
VAL_ 214 ModeCommand_MCPB_2 0 "Inverter_Disabled" 1 "Torque_Control" 2 "Speed_Control" 3 "Active_Discharge" 4 "Disable_Immediate" 5 "Voltage_Control" 6 "Rapid_Shutdown" 7 "Shutdown_Initiated" 8 "ROL_Routine" 9 "Active_Short_Circuit" 15 "SNA";
VAL_ 214 ModeCommand_MCPA_2 0 "Inverter_Disabled" 1 "Torque_Control" 2 "Speed_Control" 3 "Active_Discharge" 4 "Disable_Immediate" 5 "Voltage_Control" 6 "0x6 Rapid_Shutdown" 7 "Shutdown_Initiated" 8 "ROL_Routine" 9 "Active_Short_Circuit" 15 "SNA";
VAL_ 214 MinTorque_Limit_MCPB_2 16383 "SNA";
VAL_ 214 MinTorque_Limit_MCPA_2 16383 "SNA";
VAL_ 214 MaxTorque_Limit_MCPB_2 16383 "SNA";
VAL_ 214 MaxTorque_Limit_MCPA_2 16383 "SNA";
VAL_ 214 HVBatVlt_V_2 0 "Valid" 1 "Invalid";
VAL_ 214 EVCU_END_Request_Flag_2 0 "No_Request" 1 "Request";
VAL_ 1072 EVSE_EnergizingState 0 "Disable" 1 "Enable";
VAL_ 1072 EVSE_ChargingSystemError 0 "Normal" 1 "Error";
VAL_ 1072 EVSE_CHAdeMOProtocol 0 "CHAdeMO_0_9_and_earlier" 1 "CHAdeMO_0_9_and_0_9_1" 2 "CHAdeMO_1_0and1_0_1and1_1and1_2" 3 "CHAdeMO_2_0" 7 "SNA";
VAL_ 1072 EVSE_BatteryCompatibilty 0 "compatible" 1 "Incompatible";
VAL_ 1073 VehicleDriveSts 0 "Parked" 1 "Not_parked";
VAL_ 1073 StopReqBeforeCharge 0 "No_Request" 1 "Request_Stop";
VAL_ 1073 EVContactorSts 0 "Contactor_closed" 1 "EV_Contactor_Open";
VAL_ 1073 CHAdeMOProtocol 0 "CHAdeMO_0_9_and_earlier" 1 "CHAdeMO_0_9_and_0_9_1" 2 "CHAdeMO_1_0and1_0_1and1_1and1_2" 3 "CHAdeMO_2_0" 7 "SNA";
VAL_ 1073 BattVoltDeviationErr 0 "Normal" 1 "Fault";
VAL_ 215 Output_Torque_Limit 32767 "SNA";
VAL_ 215 PCU_Max_DischargePowerLmt_ShrTrm 16383 "SNA";
VAL_ 215 DMPI_OilTemperatureSts 0 "Normal" 1 "High";
VAL_ 214 AEMD_Sclr_Gn_MCPB_2 2047 "SNA";
VAL_ 214 AEMD_Sclr_Gn_MCPA_2 2047 "SNA";
VAL_ 1072 CdM_Charger_connector_lock 0 "Lock_release" 1 "Lock";
VAL_ 1073 EVCU_CP3Cmd 0 "Disable_veh_charge_permission" 1 "Enable_veh_charge_permission";
VAL_ 1073 CdM_Remained_batt_capacity 255 "SNA";
VAL_ 577 QualifyDriveCycle 0 "Not_Realized" 1 "Realized";
VAL_ 220 VIN_MSG_OBD 0 "VIN_LO" 1 "VIN_MID" 2 "VIN_HI" 3 "SNA";
VAL_ 220 VehicleSpeedVSOSig_OBD 8191 "SNA";
VAL_ 220 OperationalModeSts_OBD 0 "Initialization" 1 "Ignition_Off_WithoutKey" 2 "Ignition_Off" 3 "Ignition_Acc" 4 "Ignition_On" 5 "Ignition_Pre_Start" 6 "Ignition_Start" 7 "Ignition_Cranking" 8 "Ignition_On_EngOn" 9 "Ignition_Pre_Acc" 10 "Ignition_Pre_Off" 11 "Automatic_Cranking" 12 "Automatic_Stop" 13 "Key_Authenticated" 14 "Not_Used" 15 "SNA";
VAL_ 220 EngineSpeedFailSts_W_OBD 0 "Fail_not_present" 1 "Fail_present";
VAL_ 220 EngineSpeed_W_OBD 16383 "SNA";
VAL_ 220 CmdIgnSts_OBD 0 "Initialization" 1 "IGN_LK" 3 "ACC" 4 "RUN" 5 "START" 7 "SNA";
VAL_ 200 TotalAxle_Rq_BSM_PT 65535 "SNA";
VAL_ 200 TotalAxle_Min_Rq_BSM_PT 0 "Not_Active" 1 "Active";
VAL_ 200 TotalAxle_Max_Rq_BSM_PT 0 "Not_Active" 1 "Active";
VAL_ 200 Total_AxleTorque_Static_PT 65535 "SNA";
VAL_ 200 RHFWheelSpeed_PT 8191 "SNA";
VAL_ 200 RHF_WheelSensorFailSts_PT 0 "Fail_Not_Present" 1 "Fail_Present";
VAL_ 200 LHFWheelSpeed_PT 8191 "SNA";
VAL_ 200 LHF_WheelSensorFailSts_PT 0 "Fail_Not_Present" 1 "Fail_Present";
VAL_ 200 Ft_RrCouplingTrq_Desired_PT 255 "SNA";
VAL_ 200 Ft_RrCouplingTrq_Actual_PT 255 "SNA";
VAL_ 200 ESCActive_PT 0 "Not_Active" 1 "Active";
VAL_ 200 Axle_TorqueStatic_D_TTC_PT 65535 "SNA";
VAL_ 200 Axle_TorqueStatic_D_TTC_ESC_PT 65535 "SNA";
VAL_ 200 AWDSysStat_PT 0 "SH_IPG" 1 "4LO" 2 "4HI" 3 "2WD" 4 "NEUTRAL" 5 "SYNC_IPG" 6 "4WDLock" 7 "SNA";
VAL_ 200 AtmosphericPressureFailSts_PT 0 "Fail_Not_Present" 1 "Fail_Present";
VAL_ 200 AtmosphericPressure_W_PT 255 "SNA";
VAL_ 215 DMPI_TransmissionTemperature 63 "SNA";
VAL_ 220 ExternalTemperatureC_OBD 511 "SNA";
VAL_ 215 REPRGD_PFC_CLR_DMPI 0 "Do_Nothing" 1 "Set_Incomplete";
VAL_ 215 CODE_CLR_DMPI 0 "Not_Clear" 1 "Clear";
VAL_ 212 PIM_B_AccelRaw 65535 "SNA";
VAL_ 211 PIM_A_AccelRaw 65535 "SNA";
VAL_ 1073 CdM_ExtFun_Veh_HC_Control_Comp 0 "High_current_cntrl_not_applied" 1 "High_current_cntrl_is_applied";
VAL_ 1073 CdM_ExtFun_Veh_Dyn_Control_Comp 0 "No_dyn_cntrl_of_extd_function" 1 "Dyn_cntrl_of_extd_function";
VAL_ 1073 CdM_ExtFun_Min_Batt_Volt 2047 "SNA";
VAL_ 214 Boost_Torque_Margin_MCPB 1023 "SNA";
VAL_ 214 Boost_Torque_Margin_MCPA 1023 "SNA";
SIG_GROUP_ 200 PT_SYSTEM_FD_4_Pkt 1 : TotalAxle_Rq_BSM_PT TotalAxle_Min_Rq_BSM_PT TotalAxle_Max_Rq_BSM_PT Total_AxleTorque_Static_PT RHFWheelSpeed_PT RHF_WheelSensorFailSts_PT LHFWheelSpeed_PT LHF_WheelSensorFailSts_PT Ft_RrCouplingTrq_Desired_PT Ft_RrCouplingTrq_Actual_PT ESCActive_PT Axle_TorqueStatic_D_TTC_PT Axle_TorqueStatic_D_TTC_ESC_PT AWDSysStat_PT AtmosphericPressureFailSts_PT AtmosphericPressure_W_PT MessageCounter_PT_SYSTEM_FD_4 CRC_PT_SYSTEM_FD_4;
SIG_GROUP_ 212 PIM_B_Pkt 1 : PIM_B_Torque_Achieved PIM_B_Torque_Achieved_V PIM_B_TorqAchieved_AEMD_V PIM_B_TorqAchieved_AEMD PIM_B_SPT_Stat PIM_B_Spd_Lim PIM_B_RPM_V PIM_B_RPM PIM_B_MtrMinCpbltyTrq PIM_B_MtrMaxCpbltyTrq PIM_B_MtrIndex PIM_B_MinTorq PIM_B_MaxTorq PIM_B_Invrtr_State PIM_B_InterlockSts PIM_B_HV_CnctrOpn_Req PIM_B_Dschrge_Status PIM_B_DeratingFactor PIM_B_DerateReason PIM_B_DC_Voltage PIM_B_DC_Volt_V PIM_B_DC_Current_V PIM_B_DC_Current PIM_B_CpbltySpdDivVolt PIM_B_CoolantTemp PIM_B_AccelRawV PIM_B_6SO_Status PIM_B_3PS_Pos MC_PIM_B MAC_PIM_B CRC_PIM_B Cntr_PIM_B PIM_B_AccelRaw;
SIG_GROUP_ 211 PIM_A_Pkt 1 : PIM_A_Torque_Achieved PIM_A_Torque_Achieved_V PIM_A_TorqAchieved_AEMD_V PIM_A_TorqAchieved_AEMD PIM_A_SPT_Stat PIM_A_Spd_Lim PIM_A_RPM_V PIM_A_RPM PIM_A_MtrMinCpbltyTrq PIM_A_MtrMaxCpbltyTrq PIM_A_MtrIndex PIM_A_MinTorq PIM_A_MaxTorq PIM_A_Invrtr_State PIM_A_InterlockSts PIM_A_HV_CnctrOpn_Req PIM_A_Dschrge_Status PIM_A_DeratingFactor PIM_A_DerateReason PIM_A_DC_Voltage PIM_A_DC_Volt_V PIM_A_DC_Current_V PIM_A_DC_Current PIM_A_CpbltySpdDivVolt PIM_A_CoolantTemp PIM_A_AccelRawV PIM_A_6SO_Status PIM_A_3PS_Pos MC_PIM_A MAC_PIM_A CRC_PIM_A Cntr_PIM_A PIM_A_AccelRaw;
SIG_GROUP_ 215 PCU_FD_1_Pkt 1 : Pinion_OverspeedWarning PCU_Temporary_Stop_Flag PCU_MIL_Request PCU_MaxBoostedVoltage PCU_Max_DischargePowerLmt PCU_Max_ChargePowerLmt PCU_DriveReadyCompletion_Status PCU_Diagnostic_Code MessageCounter_PCU_FD_1 MAC_PCU_FD_1 CRC_PCU_FD_1 Cntr_PCU_FD_1 BoostConverterFailureSts BoostConverter_Current BoostConv_UpperIGBT_TempFltd BoostConv_ReactorTemp BoostConv_LowerIGBT_TempFltd Output_Torque_Limit BoostConverterDerateReason PCU_Max_DischargePowerLmt_ShrTrm DMPI_OilTemperatureSts DMPI_TransmissionTemperature REPRGD_PFC_CLR_DMPI CODE_CLR_DMPI;
SIG_GROUP_ 214 INVTARGET1_2_Pkt 1 : UDCMin_Unlim_MCPB_2 UDCMin_Unlim_MCPA_2 UDCMax_Unlim_MCPB_2 UDCMax_Unlim_MCPA_2 TqGrdtLim_MCPB_2 TqGrdtLim_MCPA_2 TorqueCommand_MCPB_2 TorqueCommand_MCPA_2 TargetMotorRPM_MCPB_2 TargetMotorRPM_MCPA_2 SpdGrdtLim_MCPB_2 SpdGrdtLim_MCPA_2 Mtr_6SO_Request_MCPB_2 Mtr_6SO_Request_MCPA_2 ModeCommand_MCPB_2 ModeCommand_MCPA_2 MinTorque_Limit_MCPB_2 MinTorque_Limit_MCPA_2 MessageCounter_INVTARGET1_2 MaxTorque_Limit_MCPB_2 MaxTorque_Limit_MCPA_2 MAC_INVTARGET1_2 LgsDiagCldStrtCndMet_MCPB_2 LgsDiagCldStrtCndFltPr_MCPB_2 HVBatVlt_V_2 EVCU_END_Request_Flag_2 CRC_INVTARGET1_2 Cntr_INVTARGET1_2 AEMD_MinOffset_MCPB_2 AEMD_MinOffset_MCPA_2 AEMD_MaxOffset_MCPB_2 AEMD_Cutoff_FreqLow_MCPB_2 AEMD_Cutoff_FreqLow_MCPA_2 AEMD_Cutoff_FreqHigh_MCPB_2 AEMD_Cutoff_FreqHigh_MCPA_2 AEMD_Sclr_Gn_MCPB_2 AEMD_Sclr_Gn_MCPA_2 AEMD_Torque_BoostVolt_Margin Boost_Torque_Margin_MCPB Boost_Torque_Margin_MCPA;
